VERSION ""

NS_ :

BS_:

BU_: LMFS RMFS TPMS TCU_ERAGLONASS E_APU PCCM NOX_2 NOX_1 ENGINE_CONTROL_MODULE TRANSMISSION INTARDER EBS TACHOGRAPH INSTRUMENT_CLUSTER CAMERA RADAR BCM

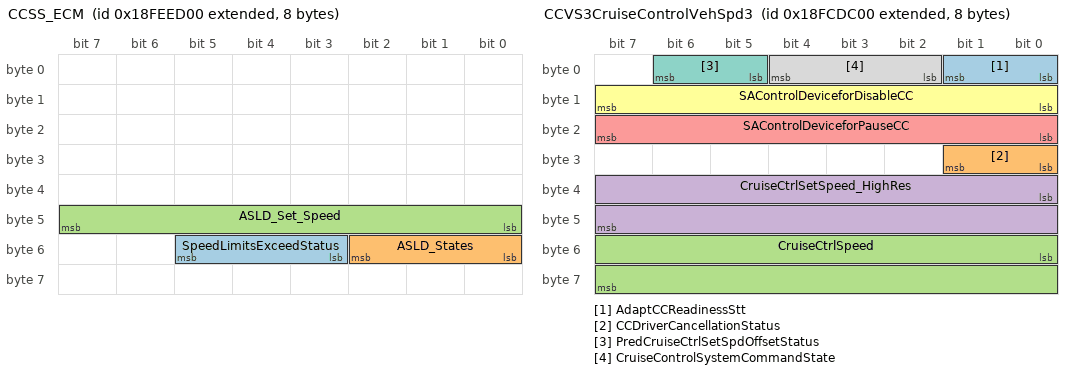
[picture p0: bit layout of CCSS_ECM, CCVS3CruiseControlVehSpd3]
BO_ 2566843648 CCSS_ECM: 8 ENGINE_CONTROL_MODULE
 SG_ SpeedLimitsExceedStatus : 51|3@1+ (1,0) [0|7] ""  PCCM,INSTRUMENT_CLUSTER
 SG_ ASLD_States : 48|3@1+ (1,0) [0|7] "SED"  PCCM,INSTRUMENT_CLUSTER
 SG_ ASLD_Set_Speed : 40|8@1+ (1,0) [0|250] "km/h"  PCCM,INSTRUMENT_CLUSTER

BO_ 2566708224 CCVS3CruiseControlVehSpd3: 8 ENGINE_CONTROL_MODULE
 SG_ AdaptCCReadinessStt : 0|2@1+ (1,0) [0|3] "SED" Vector__XXX
 SG_ CCDriverCancellationStatus : 24|2@1+ (1,0) [0|3] ""  PCCM
 SG_ CruiseCtrlSpeed : 48|16@1+ (0.00390625,0) [0|250.99609375] "km/h"  PCCM
 SG_ CruiseCtrlSetSpeed_HighRes : 32|16@1+ (0.00390625,0) [0|250.99609375] "km/h"  PCCM
 SG_ SAControlDeviceforPauseCC : 16|8@1+ (1,0) [0|255] ""  PCCM
 SG_ SAControlDeviceforDisableCC : 8|8@1+ (1,0) [0|255] ""  PCCM
 SG_ PredCruiseCtrlSetSpdOffsetStatus : 5|2@1+ (1,0) [0|3] ""  PCCM
 SG_ CruiseControlSystemCommandState : 2|3@1+ (1,0) [0|7] ""  PCCM

BO_ 2365512010 EmgcyCallMute: 8 TCU_ERAGLONASS
 SG_ Audio_Mute : 0|2@1+ (1,0) [0|3] ""  BCM

BO_ 2565475095 RQST_IC_EBS: 3 INSTRUMENT_CLUSTER
 SG_ ParameterGroupNumber : 0|24@1+ (1,0) [0|16777215] ""  PCCM,EBS

BO_ 2565472279 RQST_IC_ECM: 3 INSTRUMENT_CLUSTER
 SG_ ParameterGroupNumber : 0|24@1+ (1,0) [0|16777215] ""  ENGINE_CONTROL_MODULE

BO_ 2349465642 CCVS2: 8 RADAR
 SG_ CruiseControlPauseCommand : 4|2@1+ (1,0) [0|3] ""  PCCM
 SG_ CruiseControlDisableCommand : 0|2@1+ (1,0) [0|3] ""  PCCM

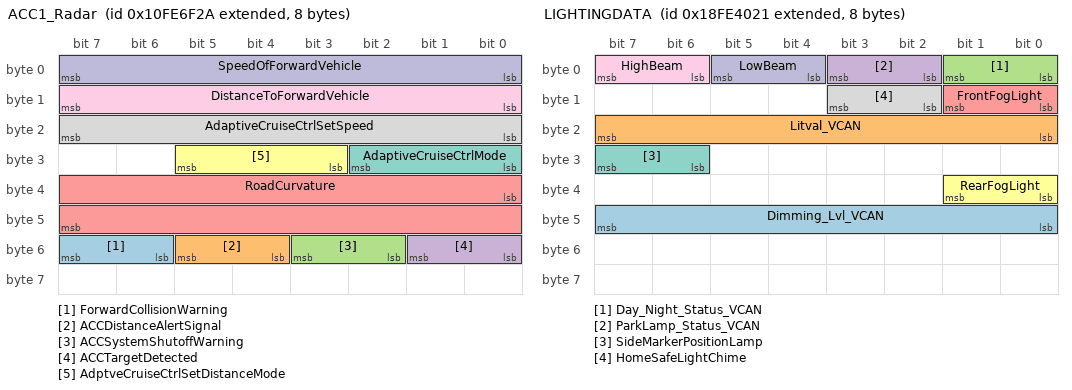
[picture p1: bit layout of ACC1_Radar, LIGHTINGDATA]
BO_ 2432593706 ACC1_Radar: 8 RADAR
 SG_ ForwardCollisionWarning : 54|2@1+ (1,0) [0|3] ""  PCCM,TRANSMISSION,INSTRUMENT_CLUSTER,BCM
 SG_ ACCDistanceAlertSignal : 52|2@1+ (1,0) [0|3] ""  PCCM,TRANSMISSION,INSTRUMENT_CLUSTER,BCM
 SG_ ACCSystemShutoffWarning : 50|2@1+ (1,0) [0|3] ""  PCCM,TRANSMISSION,INSTRUMENT_CLUSTER,BCM
 SG_ ACCTargetDetected : 48|2@1+ (1,0) [0|3] ""  PCCM,TRANSMISSION,INSTRUMENT_CLUSTER,BCM
 SG_ RoadCurvature : 32|16@1+ (0.0078125,-250) [-250|251.992] "1/km"  PCCM,TRANSMISSION,INSTRUMENT_CLUSTER,BCM
 SG_ AdptveCruiseCtrlSetDistanceMode : 27|3@1+ (1,0) [0|7] ""  PCCM,TRANSMISSION,INSTRUMENT_CLUSTER,BCM
 SG_ AdaptiveCruiseCtrlMode : 24|3@1+ (1,0) [0|7] ""  PCCM,TRANSMISSION,INSTRUMENT_CLUSTER,BCM
 SG_ AdaptiveCruiseCtrlSetSpeed : 16|8@1+ (1,0) [0|250] "km/h"  PCCM,TRANSMISSION,INSTRUMENT_CLUSTER,BCM
 SG_ DistanceToForwardVehicle : 8|8@1+ (1,0) [0|250] "m"  PCCM,TRANSMISSION,INSTRUMENT_CLUSTER,BCM
 SG_ SpeedOfForwardVehicle : 0|8@1+ (1,0) [0|250] "km/h"  PCCM,TRANSMISSION,INSTRUMENT_CLUSTER,BCM

BO_ 2566799393 LIGHTINGDATA: 8 BCM
 SG_ Dimming_Lvl_VCAN : 40|8@1+ (1,0) [0|255] ""  PCCM
 SG_ Litval_VCAN : 16|8@1+ (1,0) [0|255] "SED"  PCCM
 SG_ Day_Night_Status_VCAN : 0|2@1+ (1,0) [0|3] "SED"  PCCM
 SG_ ParkLamp_Status_VCAN : 2|2@1+ (1,0) [0|3] "SED"  PCCM
 SG_ FrontFogLight : 8|2@1+ (1,0) [0|3] ""  PCCM,INSTRUMENT_CLUSTER
 SG_ RearFogLight : 32|2@1+ (1,0) [0|3] ""  PCCM,INSTRUMENT_CLUSTER
 SG_ SideMarkerPositionLamp : 30|2@1+ (1,0) [0|3] ""  PCCM,INSTRUMENT_CLUSTER
 SG_ HomeSafeLightChime : 10|2@1+ (1,0) [0|3] ""  PCCM,INSTRUMENT_CLUSTER
 SG_ HighBeam : 6|2@1+ (1,0) [0|3] ""  PCCM,INSTRUMENT_CLUSTER
 SG_ LowBeam : 4|2@1+ (1,0) [0|3] ""  PCCM,INSTRUMENT_CLUSTER

BO_ 2566838561 AUXIO1: 8 BCM
 SG_ LaneDepartureWarningEnable : 30|2@1+ (1,0) [0|3] ""  PCCM,INSTRUMENT_CLUSTER
 SG_ DrvActDemandAdvEmergBrake : 28|2@1+ (1,0) [0|3] ""  PCCM,INSTRUMENT_CLUSTER
 SG_ Ignition_Status_VCAN : 24|4@1+ (1,0) [0|15] "SED"  PCCM,RMFS,RADAR
 SG_ AirDistributionMode : 18|4@1+ (1,0) [0|15] "SED"  PCCM,RMFS,RADAR
 SG_ CabInteriorTempCommand_BCM : 48|8@1+ (0.5,-40) [-40|87] "deg C"  PCCM,RMFS,RADAR
 SG_ TrailerABSEBSFault : 16|2@1+ (1,0) [0|3] "SED"  PCCM,RMFS,RADAR
 SG_ SteWhlSwtchMenu_B_Stat : 15|1@1+ (1,0) [0|1] "SED"  PCCM,RMFS,RADAR
 SG_ SteWhlSwtchBack_B_Stat : 34|1@1+ (1,0) [0|1] "SED"  PCCM,RMFS,RADAR
 SG_ SteWhlSwtchUp_B_Stat : 35|1@1+ (1,0) [0|1] "SED"  PCCM,RMFS,RADAR
 SG_ SteWhlSwtchOk_B_Stat : 36|1@1+ (1,0) [0|1] "SED"  PCCM,RMFS,RADAR
 SG_ SteWhlSwtchDown_B_Stat : 37|1@1+ (1,0) [0|1] "SED"  PCCM,RMFS,RADAR
 SG_ ManeuveringMode : 38|2@1+ (1,0) [0|3] "SED"  PCCM,RMFS,RADAR
 SG_ PowerMode_BCM : 40|2@1+ (1,0) [0|3] ""  PCCM,RMFS,RADAR
 SG_ OffRoadMode_BCM : 42|2@1+ (1,0) [0|3] ""  PCCM,RMFS,RADAR
 SG_ RockingMode_BCM : 44|2@1+ (1,0) [0|3] ""  PCCM,RMFS,RADAR
 SG_ RollingMode_BCM : 46|2@1+ (1,0) [0|3] ""  PCCM,RMFS,RADAR
 SG_ RqedACCDistanceMode : 12|3@1+ (1,0) [0|7] ""  PCCM,RMFS,RADAR
 SG_ AuxI_O08_GearboxNeutralPos_AUX1 : 4|2@1+ (1,0) [0|3] ""  PCCM,RMFS,RADAR
 SG_ AuxI_O07_TrailerABSFulOper_AUX1 : 6|2@1+ (1,0) [0|3] ""  PCCM,RMFS,RADAR
 SG_ AuxI_O06_TrailerABSDetected_AUX1 : 8|2@1+ (1,0) [0|3] ""  PCCM,RMFS,RADAR
 SG_ AuxI_O05_TrailerConnected_AUX1 : 10|2@1+ (1,0) [0|3] ""  PCCM,RMFS,RADAR
 SG_ PassengerDoorStatus : 0|2@1+ (1,0) [0|3] ""  PCCM,RMFS,RADAR,ENGINE_CONTROL_MODULE,INSTRUMENT_CLUSTER
 SG_ DriverDoorStatus : 2|2@1+ (1,0) [0|3] ""  PCCM,RMFS,RADAR,ENGINE_CONTROL_MODULE,INSTRUMENT_CLUSTER

BO_ 2564431089 TSTREQPCCM: 8 Vector__XXX
 SG_ TesterReqPCCM : 0|64@1- (1,0) [0|0] ""  PCCM

BO_ 2564429809 TSTREQCLUSTER: 8 PCCM
 SG_ TesterReqCluster : 0|64@1- (1,0) [0|0] "" Vector__XXX

BO_ 2564434673 TSTREQRADAR: 8 PCCM
 SG_ TesterReqRadar : 0|64@1- (1,0) [0|0] "" Vector__XXX

BO_ 2564428017 TSTREQINTARDER: 8 Vector__XXX

BO_ 2564436209 TSTREQEAPU: 8 Vector__XXX

BO_ 2564423921 TSTREQECM: 8 Vector__XXX

BO_ 2564483313 TSTREQCAMERA: 8 PCCM
 SG_ TesterReqCamera : 0|64@1- (1,0) [0|0] "" Vector__XXX

BO_ 2564432369 TSTREQBCM: 8 Vector__XXX
 SG_ TesterReqBCM : 0|64@1+ (1,0) [0|0] "" Vector__XXX

BO_ 2564426737 TSTREQEBS: 8 PCCM
 SG_ TesterReqEBS : 0|64@1- (1,0) [0|0] "" Vector__XXX

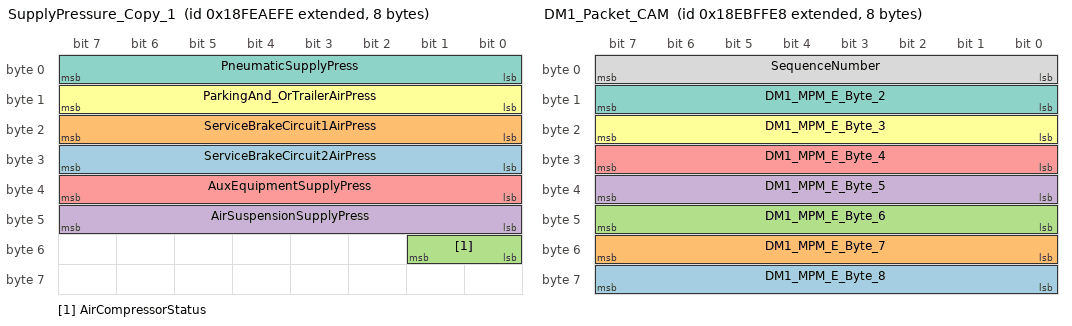
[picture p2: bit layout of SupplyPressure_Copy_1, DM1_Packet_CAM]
BO_ 2566827774 SupplyPressure_Copy_1: 8 Vector__XXX
 SG_ ServiceBrakeCircuit2AirPress : 24|8@1+ (8,0) [0|2000] "kPa" Vector__XXX
 SG_ ServiceBrakeCircuit1AirPress : 16|8@1+ (8,0) [0|2000] "kPa" Vector__XXX
 SG_ AirCompressorStatus : 48|2@1+ (1,0) [0|3] "" Vector__XXX
 SG_ AirSuspensionSupplyPress : 40|8@1+ (8,0) [0|2000] "kPa" Vector__XXX
 SG_ AuxEquipmentSupplyPress : 32|8@1+ (8,0) [0|2000] "kPa" Vector__XXX
 SG_ ParkingAnd_OrTrailerAirPress : 8|8@1+ (8,0) [0|2000] "kPa" Vector__XXX
 SG_ PneumaticSupplyPress : 0|8@1+ (8,0) [0|2000] "kPa" Vector__XXX

BO_ 2565603114 DM1_Packet_Radar: 8 Vector__XXX
 SG_ SequenceNumber : 0|8@1+ (1,0) [0|255] "" Vector__XXX

BO_ 2565668394 DM1_BAM_E_RADAR: 8 Vector__XXX
 SG_ TotalNumberOfPacketsEoMA m19 : 24|8@1+ (1,0) [0|255] "" Vector__XXX
 SG_ TotalMessageSizeEoMA m19 : 8|16@1+ (1,0) [0|64255] "counts" Vector__XXX
 SG_ TotalMessageSizeBAM m32 : 8|16@1+ (1,0) [0|64255] "counts" Vector__XXX
 SG_ TotalNumberOfPacketsBAM m32 : 24|8@1+ (1,0) [0|255] "" Vector__XXX
 SG_ ConnectionAbortReason m255 : 8|8@1+ (1,0) [0|255] "" Vector__XXX
 SG_ NextPacketNumberToBeSent m17 : 16|8@1+ (1,0) [0|255] "" Vector__XXX
 SG_ NumberOfPacketsThatCanBeSent m17 : 8|8@1+ (1,0) [0|255] "" Vector__XXX
 SG_ PGNumber : 40|24@1+ (1,0) [0|16777200] "" Vector__XXX
 SG_ MaximumNumberOfPackets m16 : 32|8@1+ (1,0) [0|255] "" Vector__XXX
 SG_ TotalNumberOfPackets m16 : 24|8@1+ (1,0) [0|255] "" Vector__XXX
 SG_ TotalMessageSize m16 : 8|16@1+ (1,0) [0|64255] "counts" Vector__XXX
 SG_ ControlByte M : 0|8@1+ (1,0) [0|255] "" Vector__XXX

BO_ 2565603304 DM1_Packet_CAM: 8 Vector__XXX
 SG_ DM1_MPM_E_Byte_8 : 56|8@1- (1,0) [0|255] "" Vector__XXX
 SG_ DM1_MPM_E_Byte_7 : 48|8@1- (1,0) [0|255] "" Vector__XXX
 SG_ DM1_MPM_E_Byte_6 : 40|8@1- (1,0) [0|255] "" Vector__XXX
 SG_ DM1_MPM_E_Byte_5 : 32|8@1- (1,0) [0|255] "" Vector__XXX
 SG_ DM1_MPM_E_Byte_4 : 24|8@1- (1,0) [0|255] "" Vector__XXX
 SG_ DM1_MPM_E_Byte_3 : 16|8@1- (1,0) [0|255] "" Vector__XXX
 SG_ DM1_MPM_E_Byte_2 : 8|8@1- (1,0) [0|255] "" Vector__XXX
 SG_ SequenceNumber : 0|8@1+ (1,0) [0|255] "" Vector__XXX

BO_ 2565668840 DM1_BAM_E_TPCM_CAM: 8 Vector__XXX
 SG_ TotalNumberOfPacketsEoMA m19 : 24|8@1+ (1,0) [0|255] "" Vector__XXX
 SG_ TotalMessageSizeEoMA m19 : 8|16@1+ (1,0) [0|64255] "counts" Vector__XXX
 SG_ TotalMessageSizeBAM m32 : 8|16@1+ (1,0) [0|64255] "counts" Vector__XXX
 SG_ TotalNumberOfPacketsBAM m32 : 24|8@1+ (1,0) [0|255] "" Vector__XXX
 SG_ ConnectionAbortReason m255 : 8|8@1+ (1,0) [0|255] "" Vector__XXX
 SG_ NextPacketNumberToBeSent m17 : 16|8@1+ (1,0) [0|255] "" Vector__XXX
 SG_ NumberOfPacketsThatCanBeSent m17 : 8|8@1+ (1,0) [0|255] "" Vector__XXX
 SG_ PGNumber : 40|24@1+ (1,0) [0|16777200] "" Vector__XXX
 SG_ MaximumNumberOfPackets m16 : 32|8@1+ (1,0) [0|255] "" Vector__XXX
 SG_ TotalNumberOfPackets m16 : 24|8@1+ (1,0) [0|255] "" Vector__XXX
 SG_ TotalMessageSize m16 : 8|16@1+ (1,0) [0|64255] "counts" Vector__XXX
 SG_ ControlByte M : 0|8@1+ (1,0) [0|255] "" Vector__XXX

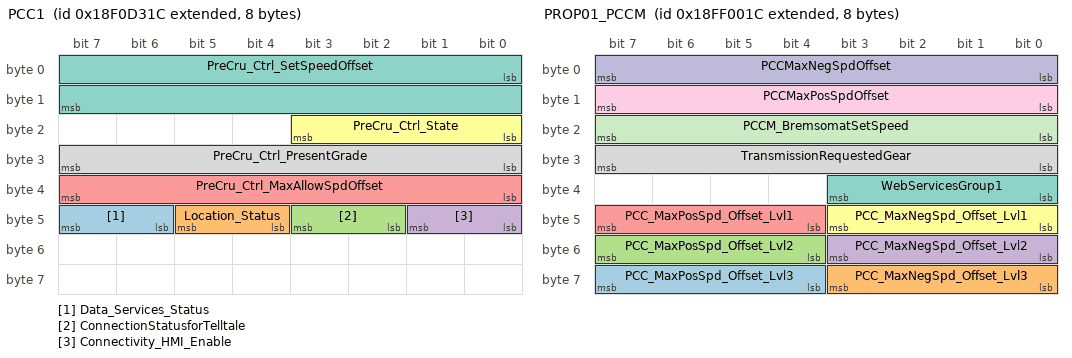
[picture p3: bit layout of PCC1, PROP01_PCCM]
BO_ 2565919516 PCC1: 8 PCCM
 SG_ Data_Services_Status : 46|2@1+ (1,0) [0|3] ""  INSTRUMENT_CLUSTER
 SG_ Location_Status : 44|2@1+ (1,0) [0|3] ""  INSTRUMENT_CLUSTER
 SG_ ConnectionStatusforTelltale : 42|2@1+ (1,0) [0|3] ""  INSTRUMENT_CLUSTER
 SG_ Connectivity_HMI_Enable : 40|2@1+ (1,0) [0|3] ""  INSTRUMENT_CLUSTER
 SG_ PreCru_Ctrl_MaxAllowSpdOffset : 32|8@1+ (0.125,0) [0|31.25] "kph"  ENGINE_CONTROL_MODULE
 SG_ PreCru_Ctrl_State : 16|4@1+ (1,0) [0|15] ""  INSTRUMENT_CLUSTER,ENGINE_CONTROL_MODULE,TRANSMISSION
 SG_ PreCru_Ctrl_SetSpeedOffset : 0|16@1+ (0.00390625,-125) [-125|125.996] "kph"  INSTRUMENT_CLUSTER,ENGINE_CONTROL_MODULE,TRANSMISSION
 SG_ PreCru_Ctrl_PresentGrade : 24|8@1+ (0.125,-16) [-16|15.25] "%"  INSTRUMENT_CLUSTER,ENGINE_CONTROL_MODULE,TRANSMISSION

BO_ 2566848540 PROP01_PCCM: 8 PCCM
 SG_ PCC_MaxPosSpd_Offset_Lvl3 : 60|4@1+ (1,0) [0|15] "kph"  INSTRUMENT_CLUSTER
 SG_ PCC_MaxNegSpd_Offset_Lvl3 : 56|4@1+ (1,-15) [-15|0] "kph"  INSTRUMENT_CLUSTER
 SG_ PCC_MaxPosSpd_Offset_Lvl2 : 52|4@1+ (1,0) [0|15] "kph"  INSTRUMENT_CLUSTER
 SG_ PCC_MaxNegSpd_Offset_Lvl2 : 48|4@1+ (1,-15) [-15|0] "kph"  INSTRUMENT_CLUSTER
 SG_ PCC_MaxPosSpd_Offset_Lvl1 : 44|4@1+ (1,0) [0|15] "kph"  INSTRUMENT_CLUSTER
 SG_ PCC_MaxNegSpd_Offset_Lvl1 : 40|4@1+ (1,-15) [-15|0] "kph"  INSTRUMENT_CLUSTER
 SG_ WebServicesGroup1 : 32|4@1+ (1,0) [0|15] ""  INSTRUMENT_CLUSTER,ENGINE_CONTROL_MODULE
 SG_ TransmissionRequestedGear : 24|8@1+ (1,-125) [-125|125] ""  INSTRUMENT_CLUSTER,ENGINE_CONTROL_MODULE
 SG_ PCCMaxPosSpdOffset : 8|8@1+ (0.125,0) [0|31.25] "kph"  INSTRUMENT_CLUSTER,ENGINE_CONTROL_MODULE,TRANSMISSION
 SG_ PCCMaxNegSpdOffset : 0|8@1+ (0.125,-31.25) [-31.25|0] "kph"  INSTRUMENT_CLUSTER,ENGINE_CONTROL_MODULE,TRANSMISSION
 SG_ PCCM_BremsomatSetSpeed : 16|8@1+ (0.5,0) [0|125] "kph"  INSTRUMENT_CLUSTER,ENGINE_CONTROL_MODULE

BO_ 2566832894 ERC2_PCCM: 8 Vector__XXX
 SG_ CruiseCtrlRetarderSpeedOffset : 8|16@1- (0.00390625,-125) [-125|125.996] "kph" Vector__XXX

BO_ 2558918398 CM2_PCCM: 8 Vector__XXX
 SG_ Pre_Crus_Cnrt_MaxNeg_Offset : 40|8@1- (0.125,-31.25) [-31.25|0] "kph" Vector__XXX
 SG_ Pre_Crus_Cnrt_MaxPoss_Offset : 32|8@1+ (0.125,0) [0|31.25] "kph" Vector__XXX

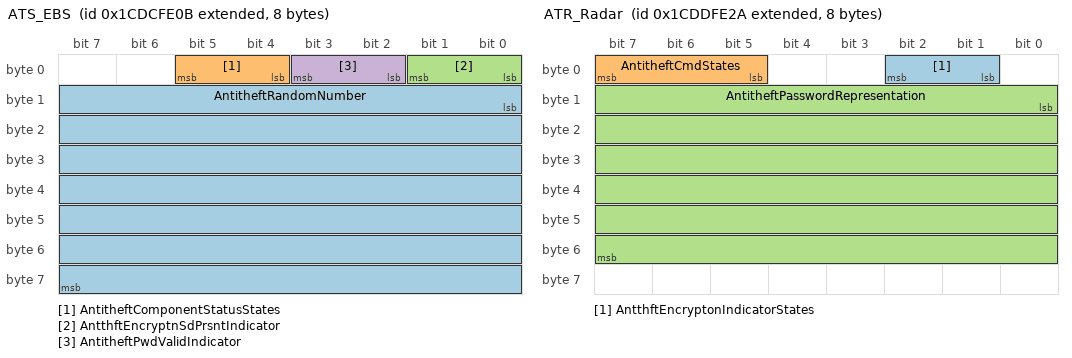
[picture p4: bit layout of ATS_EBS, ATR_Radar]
BO_ 2631728651 ATS_EBS: 8 EBS
 SG_ AntitheftRandomNumber : 8|56@1+ (1,0) [0|7.2057594038E+016] ""  RADAR
 SG_ AntitheftComponentStatusStates : 4|2@1+ (1,0) [0|3] ""  RADAR
 SG_ AntthftEncryptnSdPrsntIndicator : 0|2@1+ (1,0) [0|3] ""  RADAR
 SG_ AntitheftPwdValidIndicator : 2|2@1+ (1,0) [0|3] ""  RADAR

BO_ 2631794218 ATR_Radar: 8 RADAR
 SG_ AntthftEncryptonIndicatorStates : 1|2@1+ (1,0) [0|3] ""  EBS
 SG_ AntitheftCmdStates : 5|3@1+ (1,0) [0|7] ""  EBS
 SG_ AntitheftPasswordRepresentation : 8|48@1+ (1,0) [0|4] ""  EBS

BO_ 2566849534 MotorStatus: 8 Vector__XXX
 SG_ MeasuredPercentMotorSpeed : 48|16@1- (0.5,0) [0|0] "%" Vector__XXX
 SG_ MeasuredMotorPower : 40|8@1- (1,0) [0|0] "" Vector__XXX
 SG_ MeasuredMotorControllerTemp : 24|16@1- (0.03125,-273) [0|0] "" Vector__XXX
 SG_ MeasuredMotorSpeed : 8|16@1- (0.5,0) [0|0] "rpm" Vector__XXX

BO_ 2565865214 MotorCommand: 8 Vector__XXX
 SG_ MotorControllerPowerHoldCommand : 8|8@1- (1,0) [0|3] "" Vector__XXX
 SG_ MotorOnOffDirectionCommand : 0|8@1- (1,0) [0|3] "" Vector__XXX

BO_ 2566775040 CACI_ECM: 8 ENGINE_CONTROL_MODULE
 SG_ CbA_CRfrgrntCmprssorOutletPress : 0|8@1+ (16,0) [0|4000] "kPa"  PCCM,BCM

BO_ 2349202960 ABCD_0000: 8 Vector__XXX

BO_ 2349203198 ABCD: 8 Vector__XXX

BO_ 2566811651 TCU1: 8 TRANSMISSION
 SG_ PitchAngle : 8|8@1+ (0.25,-31) [-31|32.75] "%"  PCCM
 SG_ GrossCombinationWeight : 16|16@1+ (10,0) [0|642.55] "kg"  PCCM
 SG_ DirectorIndicator : 32|2@1+ (1,0) [0|3] ""  PCCM

BO_ 2565668619 TPCM_EBS: 8 EBS
 SG_ TotalNumberOfPacketsEoMA m19 : 24|8@1+ (1,0) [0|255] "" Vector__XXX
 SG_ TotalMessageSizeEoMA m19 : 8|16@1+ (1,0) [0|64255] "counts" Vector__XXX
 SG_ TotalMessageSizeBAM m32 : 8|16@1+ (1,0) [0|64255] "counts" Vector__XXX
 SG_ TotalNumberOfPacketsBAM m32 : 24|8@1+ (1,0) [0|255] "" Vector__XXX
 SG_ ConnectionAbortReason m255 : 8|8@1+ (1,0) [0|255] "" Vector__XXX
 SG_ NextPacketNumberToBeSent m17 : 16|8@1+ (1,0) [0|255] "" Vector__XXX
 SG_ NumberOfPacketsThatCanBeSent m17 : 8|8@1+ (1,0) [0|255] "" Vector__XXX
 SG_ PGNumber : 40|24@1+ (1,0) [0|16777200] "" Vector__XXX
 SG_ MaximumNumberOfPackets m16 : 32|8@1+ (1,0) [0|255] "" Vector__XXX
 SG_ TotalNumberOfPackets m16 : 24|8@1+ (1,0) [0|255] "" Vector__XXX
 SG_ TotalMessageSize m16 : 8|16@1+ (1,0) [0|64255] "counts" Vector__XXX
 SG_ ControlByte M : 0|8@1+ (1,0) [0|255] "" Vector__XXX

BO_ 2565603083 TPDT_EBS: 8 EBS
 SG_ SequenceNumber : 0|8@1+ (1,0) [0|255] "" Vector__XXX

BO_ 2566870526 PROP_IT3_BCM: 8 Vector__XXX
 SG_ Hand_Lever_Signals_PROP_IT3_BCM : 16|8@1+ (1,0) [0|31] "" Vector__XXX

BO_ 2563829271 OPT: 8 BCM
 SG_ TachoDimming : 0|8@1+ (0.4,0) [0|100] "%"  PCCM,TACHOGRAPH

BO_ 2566834920 DM1_Camera: 64 CAMERA
 SG_ OccurenceCount_Camera : 40|7@1+ (1,0) [0|127] ""  PCCM,INSTRUMENT_CLUSTER
 SG_ FailureModeIdentifier1_Camera : 32|5@1+ (1,0) [0|31] ""  PCCM,INSTRUMENT_CLUSTER
 SG_ AmberWarningLampStatus_Camera : 2|2@1+ (1,0) [0|3] ""  PCCM,INSTRUMENT_CLUSTER
 SG_ SPN4_Camera : 47|1@1+ (1,0) [0|1] ""  PCCM,INSTRUMENT_CLUSTER
 SG_ SPN3_Camera : 37|3@1+ (1,0) [0|7] ""  PCCM,INSTRUMENT_CLUSTER
 SG_ SPN2_Camera : 24|8@1+ (1,0) [0|255] ""  PCCM,INSTRUMENT_CLUSTER
 SG_ SPN1_Camera : 16|8@1+ (1,0) [0|255] ""  PCCM,INSTRUMENT_CLUSTER

BO_ 2566834730 DM1_Radar: 64 RADAR
 SG_ SPN4_Radar : 47|1@1+ (1,0) [0|1] ""  PCCM,INSTRUMENT_CLUSTER
 SG_ SPN3_Radar : 37|3@1+ (1,0) [0|7] ""  PCCM,INSTRUMENT_CLUSTER
 SG_ SPN2_Radar : 24|8@1+ (1,0) [0|255] ""  PCCM,INSTRUMENT_CLUSTER
 SG_ SPN1_Radar : 16|8@1+ (1,0) [0|255] ""  PCCM,INSTRUMENT_CLUSTER
 SG_ OccurenceCount_Radar : 40|7@1+ (1,0) [0|127] ""  PCCM,INSTRUMENT_CLUSTER
 SG_ FailureModeIdentifier1_Radar : 32|5@1+ (1,0) [0|31] ""  PCCM,INSTRUMENT_CLUSTER
 SG_ AmberWarningLampStatus_Radar : 2|2@1+ (1,0) [0|3] ""  PCCM,INSTRUMENT_CLUSTER

BO_ 2566759427 PTODE_TRANS: 8 TRANSMISSION
 SG_ PTO1EngagementStatus : 22|2@1+ (1,0) [0|3] ""  PCCM,BCM

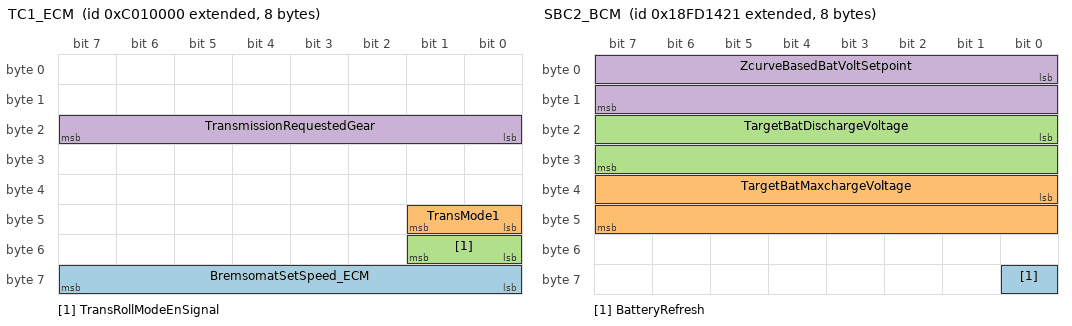
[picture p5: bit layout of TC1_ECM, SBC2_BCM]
BO_ 2348875776 TC1_ECM: 8 ENGINE_CONTROL_MODULE
 SG_ BremsomatSetSpeed_ECM : 56|8@1+ (0.5,0) [0|125] "km/h"  PCCM,RMFS
 SG_ TransMode1 : 40|2@1+ (1,0) [0|3] ""  PCCM
 SG_ TransRollModeEnSignal : 48|2@1+ (1,0) [0|3] "SED"  PCCM,RMFS
 SG_ TransmissionRequestedGear : 16|8@1+ (1,0) [0|255] ""  PCCM

BO_ 2566722593 SBC2_BCM: 8 BCM
 SG_ BatteryRefresh : 56|1@1+ (1,0) [0|1] ""  PCCM,ENGINE_CONTROL_MODULE
 SG_ TargetBatMaxchargeVoltage : 32|16@1+ (0.557,-15000) [-15000|35000] "mV"  PCCM,ENGINE_CONTROL_MODULE
 SG_ TargetBatDischargeVoltage : 16|16@1+ (0.557,-1500) [-1500|35000] "mV"  PCCM,ENGINE_CONTROL_MODULE
 SG_ ZcurveBasedBatVoltSetpoint : 0|16@1+ (0.557,-1500) [-1500|35002.995] "mV"  PCCM,ENGINE_CONTROL_MODULE

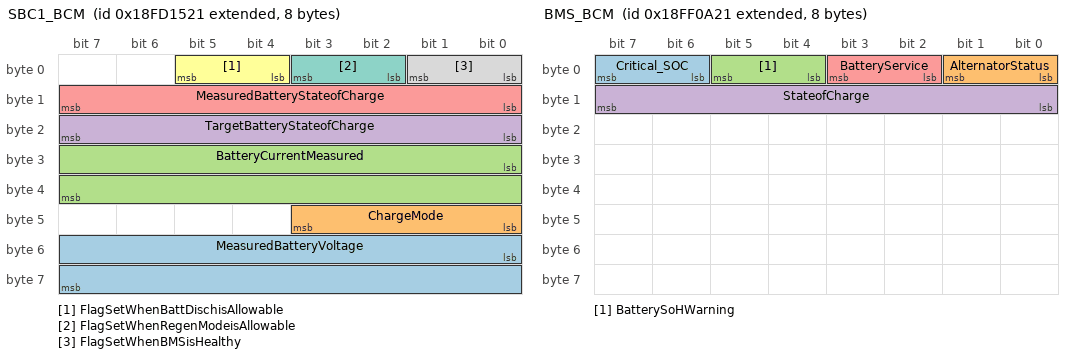
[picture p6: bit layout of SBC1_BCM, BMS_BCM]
BO_ 2566722849 SBC1_BCM: 8 BCM
 SG_ MeasuredBatteryVoltage : 48|16@1+ (0.557,-1500) [-1500|35000] "mV"  PCCM,ENGINE_CONTROL_MODULE
 SG_ ChargeMode : 40|4@1+ (1,0) [0|15] ""  PCCM,ENGINE_CONTROL_MODULE
 SG_ BatteryCurrentMeasured : 24|16@1+ (0.0305,-1600) [-1600|400] "A"  PCCM,ENGINE_CONTROL_MODULE
 SG_ TargetBatteryStateofCharge : 16|8@1+ (0.5,-10) [-10|117.5] "%"  PCCM,ENGINE_CONTROL_MODULE
 SG_ MeasuredBatteryStateofCharge : 8|8@1+ (0.5,-10) [-10|117.5] "%"  PCCM,ENGINE_CONTROL_MODULE
 SG_ FlagSetWhenBattDischisAllowable : 4|2@1+ (1,0) [0|3] ""  PCCM,ENGINE_CONTROL_MODULE
 SG_ FlagSetWhenRegenModeisAllowable : 2|2@1+ (1,0) [0|3] ""  PCCM,ENGINE_CONTROL_MODULE
 SG_ FlagSetWhenBMSisHealthy : 0|2@1+ (1,0) [0|3] ""  PCCM,ENGINE_CONTROL_MODULE

BO_ 2566879486 AUTODROP_BCM: 4 Vector__XXX
 SG_ AxleState : 24|8@1+ (1,0) [0|4] "" Vector__XXX
 SG_ AxleLoweringRemainingTime : 16|8@1+ (1,0) [0|255] "" Vector__XXX
 SG_ Warning : 8|8@1+ (1,0) [0|255] "" Vector__XXX
 SG_ Action : 0|8@1+ (1,0) [0|255] "" Vector__XXX

BO_ 2564487475 UDSClientTPMS_resp: 8 TPMS
 SG_ SignalFiller1 : 32|32@1- (1,0) [0|0] ""  PCCM
 SG_ SignalFiller0 : 0|32@1- (1,0) [0|0] ""  PCCM

BO_ 2566851105 BMS_BCM: 8 BCM
 SG_ Critical_SOC : 6|2@1+ (1,0) [0|3] "SED"  PCCM
 SG_ AlternatorStatus : 0|2@1+ (1,0) [0|3] ""  PCCM,INSTRUMENT_CLUSTER
 SG_ BatterySoHWarning : 4|2@1+ (1,0) [0|3] ""  PCCM,INSTRUMENT_CLUSTER
 SG_ StateofCharge : 8|8@1+ (1,0) [0|250] ""  PCCM,INSTRUMENT_CLUSTER
 SG_ BatteryService : 2|2@1+ (1,0) [0|3] ""  PCCM,INSTRUMENT_CLUSTER

BO_ 2566843134 VW_BCM_0000: 8 Vector__XXX
 SG_ AxleLocation M : 0|8@1+ (1,0) [0|255] "" Vector__XXX
 SG_ CargoWeight_30 m48 : 40|16@1+ (2,0) [0|128510] "kg" Vector__XXX
 SG_ CargoWeight_20 m32 : 40|16@1+ (2,0) [0|128510] "kg" Vector__XXX
 SG_ CargoWeight_10 m16 : 40|16@1+ (2,0) [0|128510] "kg" Vector__XXX
 SG_ CargoWeight_00 m0 : 40|16@1+ (2,0) [0|128510] "kg" Vector__XXX
 SG_ TrailerWeight_30 m48 : 24|16@1+ (2,0) [0|128510] "kg" Vector__XXX
 SG_ TrailerWeight_20 m32 : 24|16@1+ (2,0) [0|128510] "kg" Vector__XXX
 SG_ TrailerWeight_10 m16 : 24|16@1+ (2,0) [0|128510] "kg" Vector__XXX
 SG_ TrailerWeight_00 m0 : 24|16@1+ (2,0) [0|128510] "kg" Vector__XXX
 SG_ AxleWeight_30 m48 : 8|16@1+ (0.5,0) [0|32127.5] "kg" Vector__XXX
 SG_ AxleWeight_20 m32 : 8|16@1+ (0.5,0) [0|32127.5] "kg" Vector__XXX
 SG_ AxleWeight_10 m16 : 8|16@1+ (0.5,0) [0|32127.5] "kg" Vector__XXX
 SG_ AxleWeight_00 m0 : 8|16@1+ (0.5,0) [0|32127.5] "kg" Vector__XXX

BO_ 2365479678 ASC1_BCM_ECAS: 8 Vector__XXX
 SG_ SpeedDependantLevelCtrlStatus : 54|2@1+ (1,0) [0|3] "" Vector__XXX
 SG_ MemoryLevel : 60|4@1+ (1,0) [0|15] "" Vector__XXX
 SG_ AllwLvelCtrlDuringBrakingStatus : 52|2@1+ (1,0) [0|3] "" Vector__XXX
 SG_ SspensionCtrlRefusalInformation : 56|4@1+ (1,0) [0|15] "" Vector__XXX
 SG_ SuspensionRemoteCtrl2 : 50|2@1+ (1,0) [0|3] "" Vector__XXX
 SG_ SuspensionRemoteCtrl1 : 48|2@1+ (1,0) [0|3] "" Vector__XXX
 SG_ RearAxleInBumperRange : 42|2@1+ (1,0) [0|3] "" Vector__XXX
 SG_ FrontAxleInBumperRange : 40|2@1+ (1,0) [0|3] "" Vector__XXX
 SG_ DoorRelease : 36|2@1+ (1,0) [0|3] "" Vector__XXX
 SG_ VehicleMotionInhibit : 34|2@1+ (1,0) [0|3] "" Vector__XXX
 SG_ SecurityDevice : 32|2@1+ (1,0) [0|3] "" Vector__XXX
 SG_ LevelCtrlMode : 28|4@1+ (1,0) [0|15] "" Vector__XXX
 SG_ KneelingInformation : 24|4@1+ (1,0) [0|15] "" Vector__XXX
 SG_ LiftingCtrlModeRearAxle : 22|2@1+ (1,0) [0|3] "" Vector__XXX
 SG_ LiftingCtrlModeFrontAxle : 20|2@1+ (1,0) [0|3] "" Vector__XXX
 SG_ LoweringCtrlModeRearAxle : 18|2@1+ (1,0) [0|3] "" Vector__XXX
 SG_ LoweringCtrlModeFrontAxle : 16|2@1+ (1,0) [0|3] "" Vector__XXX
 SG_ AboveNominalLevelRearAxle : 14|2@1+ (1,0) [0|3] "" Vector__XXX
 SG_ AboveNominalLevelFrontAxle : 12|2@1+ (1,0) [0|3] "" Vector__XXX
 SG_ BelowNominalLevelRearAxle : 10|2@1+ (1,0) [0|3] "" Vector__XXX
 SG_ BelowNominalLevelFrontAxle : 8|2@1+ (1,0) [0|3] "" Vector__XXX
 SG_ NominalLevelRearAxle : 4|4@1+ (1,0) [0|15] "" Vector__XXX
 SG_ NominalLevelFrontAxle : 0|4@1+ (1,0) [0|15] "" Vector__XXX
 SG_ LiftAxle2Pos : 46|2@1+ (1,0) [0|3] "" Vector__XXX
 SG_ LiftAxle1Pos : 38|2@1+ (1,0) [0|3] "" Vector__XXX

BO_ 2566759457 PTDOE_BCM: 8 BCM
 SG_ PTOEngagementStatus : 38|2@1+ (1,0) [0|3] ""  PCCM,TRANSMISSION
 SG_ EnableSwitchStatus : 6|2@1+ (1,0) [0|3] ""  PCCM,TRANSMISSION

BO_ 2566756875 EBS24: 8 EBS
 SG_ GeoDataIndex : 0|8@1+ (1,0) [0|29] ""  PCCM

BO_ 2566910718 SRA12EDC: 1 Vector__XXX
 SG_ MultiplexValue : 0|8@1+ (1,0) [0|12] "" Vector__XXX

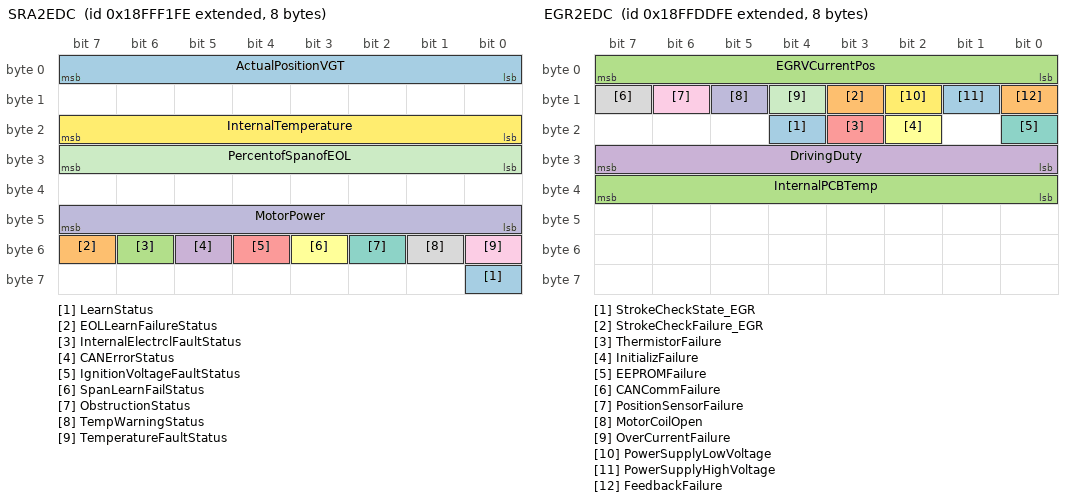
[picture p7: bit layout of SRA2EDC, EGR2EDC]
BO_ 2566910462 SRA2EDC: 8 Vector__XXX
 SG_ LearnStatus : 56|1@1+ (1,0) [0|0] "" Vector__XXX
 SG_ EOLLearnFailureStatus : 55|1@1+ (1,0) [0|1] "" Vector__XXX
 SG_ InternalElectrclFaultStatus : 54|1@1+ (1,0) [0|1] "" Vector__XXX
 SG_ CANErrorStatus : 53|1@1+ (1,0) [0|1] "" Vector__XXX
 SG_ IgnitionVoltageFaultStatus : 52|1@1+ (1,0) [0|1] "" Vector__XXX
 SG_ SpanLearnFailStatus : 51|1@1+ (1,0) [0|1] "" Vector__XXX
 SG_ ObstructionStatus : 50|1@1+ (1,0) [0|1] "" Vector__XXX
 SG_ TempWarningStatus : 49|1@1+ (1,0) [0|1] "" Vector__XXX
 SG_ TemperatureFaultStatus : 48|1@1+ (1,0) [0|1] "" Vector__XXX
 SG_ MotorPower : 40|8@1+ (1,0) [0|50] "W" Vector__XXX
 SG_ PercentofSpanofEOL : 24|8@1+ (1,0) [0|150] "%" Vector__XXX
 SG_ InternalTemperature : 16|8@1+ (1,0) [0|214] "deg C" Vector__XXX
 SG_ ActualPositionVGT : 0|8@1+ (1,0) [0|100] "%" Vector__XXX

BO_ 2566905342 EGR2EDC: 8 Vector__XXX
 SG_ StrokeCheckState_EGR : 20|1@1+ (1,0) [0|1] "" Vector__XXX
 SG_ StrokeCheckFailure_EGR : 11|1@1+ (1,0) [0|1] "" Vector__XXX
 SG_ InternalPCBTemp : 32|8@1+ (1,0) [0|150] "C deg" Vector__XXX
 SG_ DrivingDuty : 24|8@1- (1,0) [0|100] "%" Vector__XXX
 SG_ ThermistorFailure : 19|1@1- (1,0) [0|1] "" Vector__XXX
 SG_ InitializFailure : 18|1@1- (1,0) [0|1] "" Vector__XXX
 SG_ EEPROMFailure : 16|1@1+ (1,0) [0|1] "" Vector__XXX
 SG_ CANCommFailure : 15|1@1+ (1,0) [0|1] "" Vector__XXX
 SG_ PositionSensorFailure : 14|1@1+ (1,0) [0|1] "" Vector__XXX
 SG_ MotorCoilOpen : 13|1@1+ (1,0) [0|1] "" Vector__XXX
 SG_ OverCurrentFailure : 12|1@1+ (1,0) [0|1] "" Vector__XXX
 SG_ PowerSupplyLowVoltage : 10|1@1+ (1,0) [0|1] "" Vector__XXX
 SG_ PowerSupplyHighVoltage : 9|1@1+ (1,0) [0|1] "" Vector__XXX
 SG_ FeedbackFailure : 8|1@1+ (1,0) [0|1] "" Vector__XXX
 SG_ EGRVCurrentPos : 0|8@1+ (1,0) [0|80] "deg" Vector__XXX

BO_ 2566905086 EDC2EGR: 8 Vector__XXX
 SG_ StrokeCheckRequest_EGR : 47|1@1+ (1,0) [0|1] "" Vector__XXX
 SG_ CrankingSignal : 45|1@1+ (1,0) [0|1] "" Vector__XXX
 SG_ DesiredEGRValvePos : 0|8@1+ (1,0) [0|80] "deg" Vector__XXX

BO_ 2566910206 EDC2SRA: 3 Vector__XXX
 SG_ LearnedCommandPermission : 17|1@1+ (1,0) [0|1] "" Vector__XXX
 SG_ MotorOnOffStatus : 16|1@1+ (1,0) [0|1] "" Vector__XXX
 SG_ DesiredPosition : 0|8@1+ (0.1,0) [0|100] "%" Vector__XXX

BO_ 2566841344 SHUTDN_ECM: 8 ENGINE_CONTROL_MODULE
 SG_ EngineOperationMode : 26|4@1+ (1,0) [0|15] ""  INSTRUMENT_CLUSTER,PCCM
 SG_ EngOverspeedTest : 54|2@1+ (1,0) [0|3] ""  INSTRUMENT_CLUSTER,PCCM
 SG_ EngAirShutoffCmdStatus : 52|2@1+ (1,0) [0|3] ""  INSTRUMENT_CLUSTER,PCCM
 SG_ EngAlarmOutputCmdStatus : 50|2@1+ (1,0) [0|3] ""  INSTRUMENT_CLUSTER,PCCM
 SG_ EngAlarmAcknowledge : 48|2@1+ (1,0) [0|3] ""  INSTRUMENT_CLUSTER,PCCM
 SG_ EngProtectionSystemConfig : 46|2@1+ (1,0) [0|3] ""  INSTRUMENT_CLUSTER,PCCM
 SG_ EngProtectionSystemTimerState : 38|2@1+ (1,0) [0|3] ""  INSTRUMENT_CLUSTER,PCCM
 SG_ EngPrtectionSystemTimerOverride : 36|2@1+ (1,0) [0|3] ""  INSTRUMENT_CLUSTER,PCCM
 SG_ EngPrtctnSystmApprchingShutdown : 34|2@1+ (1,0) [0|3] ""  INSTRUMENT_CLUSTER,PCCM
 SG_ EngWaitToStartLamp : 24|2@1+ (1,0) [0|3] ""  INSTRUMENT_CLUSTER,PCCM
 SG_ RefrigerantHighPressSwitch : 20|2@1+ (1,0) [0|3] ""  INSTRUMENT_CLUSTER,PCCM
 SG_ RefrigerantLowPressSwitch : 18|2@1+ (1,0) [0|3] ""  INSTRUMENT_CLUSTER,PCCM
 SG_ A_CHighPressFanSwitch : 16|2@1+ (1,0) [0|3] ""  INSTRUMENT_CLUSTER,PCCM
 SG_ EngIdleShutdownTimerFunction : 14|2@1+ (1,0) [0|3] ""  INSTRUMENT_CLUSTER,PCCM
 SG_ EngIdleShutdownTimerState : 6|2@1+ (1,0) [0|3] ""  INSTRUMENT_CLUSTER,PCCM
 SG_ EngIdleShutdownTimerOverride : 4|2@1+ (1,0) [0|3] ""  INSTRUMENT_CLUSTER,PCCM
 SG_ EngIdleShutdownDriverAlertMode : 2|2@1+ (1,0) [0|3] ""  INSTRUMENT_CLUSTER,PCCM
 SG_ PTOShutdownHasShutdownEng : 58|2@1+ (1,0) [0|3] ""  INSTRUMENT_CLUSTER,PCCM
 SG_ EngPrtctnSystmHasShutdownEngine : 32|2@1+ (1,0) [0|3] ""  INSTRUMENT_CLUSTER,PCCM
 SG_ EngIdlShutdownHasShutdownEngine : 0|2@1+ (1,0) [0|3] ""  INSTRUMENT_CLUSTER,PCCM
 SG_ EngAirShutoffStatus : 56|2@1+ (1,0) [0|3] ""  INSTRUMENT_CLUSTER,PCCM

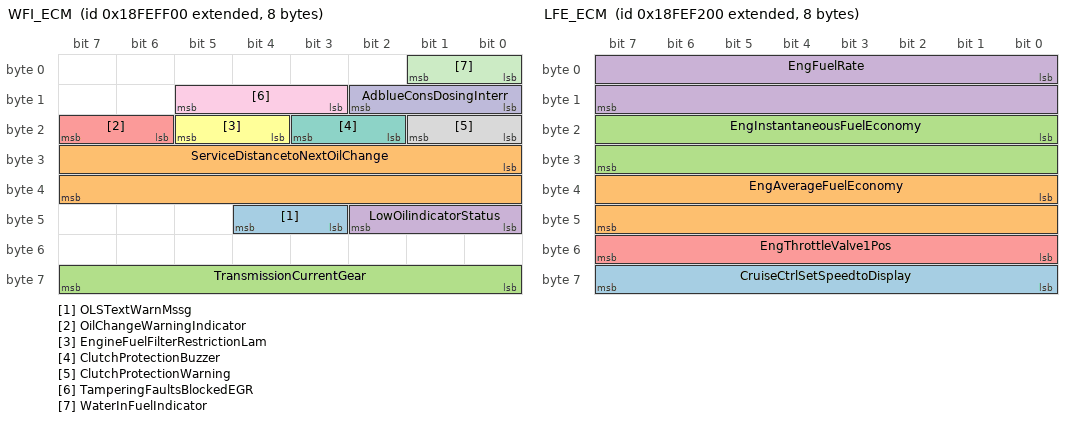
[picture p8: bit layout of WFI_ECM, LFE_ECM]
BO_ 2566848256 WFI_ECM: 8 ENGINE_CONTROL_MODULE
 SG_ OLSTextWarnMssg : 43|2@1+ (1,0) [0|3] "SED"  PCCM,INSTRUMENT_CLUSTER,BCM
 SG_ ServiceDistancetoNextOilChange : 24|16@1+ (5,-160635) [-160635|160640] ""  PCCM,INSTRUMENT_CLUSTER,BCM
 SG_ TransmissionCurrentGear : 56|8@1+ (1,-125) [-125|125] ""  PCCM,INSTRUMENT_CLUSTER,BCM
 SG_ LowOilindicatorStatus : 40|3@1+ (1,0) [0|7] ""  PCCM,INSTRUMENT_CLUSTER,BCM
 SG_ OilChangeWarningIndicator : 22|2@1+ (1,0) [0|3] ""  PCCM,INSTRUMENT_CLUSTER,BCM
 SG_ EngineFuelFilterRestrictionLam : 20|2@1+ (1,0) [0|3] ""  PCCM,INSTRUMENT_CLUSTER,BCM
 SG_ ClutchProtectionBuzzer : 18|2@1+ (1,0) [0|3] ""  PCCM,INSTRUMENT_CLUSTER,BCM
 SG_ ClutchProtectionWarning : 16|2@1+ (1,0) [0|3] ""  PCCM,INSTRUMENT_CLUSTER,BCM
 SG_ TamperingFaultsBlockedEGR : 11|3@1+ (1,0) [0|7] ""  PCCM,INSTRUMENT_CLUSTER,BCM
 SG_ AdblueConsDosingInterr : 8|3@1+ (1,0) [0|7] ""  PCCM,INSTRUMENT_CLUSTER,BCM
 SG_ WaterInFuelIndicator : 0|2@1+ (1,0) [0|3] ""  PCCM,INSTRUMENT_CLUSTER,BCM

BO_ 2566719744 HRLFC_ECM: 8 Vector__XXX
 SG_ HighResolutionEngTotalFuelUsed : 32|32@1+ (0.001,0) [0|4211081.215] "L" Vector__XXX
 SG_ HighResolutionEngTripFuel : 0|32@1+ (0.001,0) [0|4211081.215] "L" Vector__XXX

BO_ 2566844928 LFE_ECM: 8 ENGINE_CONTROL_MODULE
 SG_ CruiseCtrlSetSpeedtoDisplay : 56|8@1+ (1,0) [0|255] "km/h"  PCCM,INSTRUMENT_CLUSTER,BCM
 SG_ EngAverageFuelEconomy : 32|16@1+ (0.001953125,0) [0|125.5] "km/L"  PCCM,INSTRUMENT_CLUSTER,BCM
 SG_ EngInstantaneousFuelEconomy : 16|16@1+ (0.001953125,0) [0|125.5] "km/L"  PCCM,INSTRUMENT_CLUSTER,BCM
 SG_ EngFuelRate : 0|16@1+ (0.05,0) [0|3212.75] "L/h"  PCCM,INSTRUMENT_CLUSTER,BCM
 SG_ EngThrottleValve1Pos : 48|8@1+ (0.4,0) [0|100] "%"  PCCM,INSTRUMENT_CLUSTER,BCM

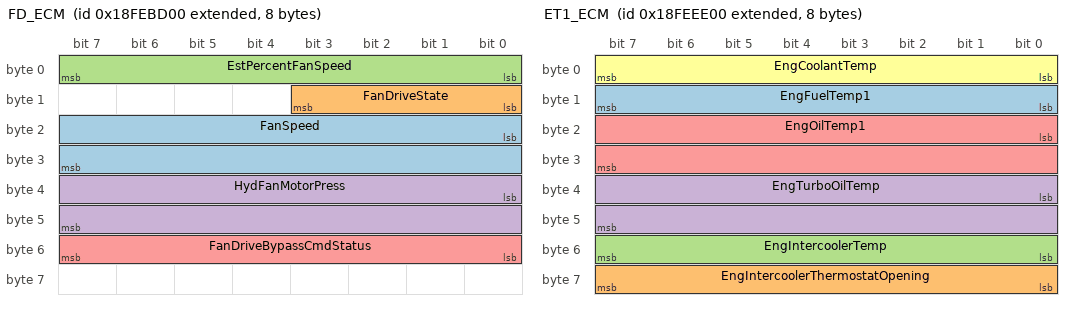
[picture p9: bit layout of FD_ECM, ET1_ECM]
BO_ 2566831360 FD_ECM: 8 ENGINE_CONTROL_MODULE
 SG_ FanSpeed : 16|16@1+ (0.125,0) [0|8031.875] "rpm"  PCCM,BCM
 SG_ FanDriveState : 8|4@1+ (1,0) [0|15] ""  PCCM,BCM
 SG_ EstPercentFanSpeed : 0|8@1+ (0.4,0) [0|100] "%"  PCCM,BCM
 SG_ HydFanMotorPress : 32|16@1+ (0.5,0) [0|32127.5] "kPa"  PCCM,BCM
 SG_ FanDriveBypassCmdStatus : 48|8@1+ (0.4,0) [0|100] "%"  PCCM,BCM

BO_ 2566843904 ET1_ECM: 8 ENGINE_CONTROL_MODULE
 SG_ EngFuelTemp1 : 8|8@1+ (1,-40) [-40|210] "deg C"  PCCM,TRANSMISSION,INSTRUMENT_CLUSTER,BCM
 SG_ EngIntercoolerThermostatOpening : 56|8@1+ (0.4,0) [0|100] "%"  PCCM,TRANSMISSION,INSTRUMENT_CLUSTER,BCM
 SG_ EngIntercoolerTemp : 48|8@1+ (1,-40) [-40|210] "deg C"  PCCM,TRANSMISSION,INSTRUMENT_CLUSTER,BCM
 SG_ EngTurboOilTemp : 32|16@1+ (0.03125,-273) [-273|1735] "deg C"  PCCM,TRANSMISSION,INSTRUMENT_CLUSTER,BCM
 SG_ EngOilTemp1 : 16|16@1+ (0.03125,-273) [-273|1735] "deg C"  PCCM,TRANSMISSION,INSTRUMENT_CLUSTER,BCM
 SG_ EngCoolantTemp : 0|8@1+ (1,-40) [-40|210] "deg C"  PCCM,TRANSMISSION,INSTRUMENT_CLUSTER,BCM

BO_ 2566841088 EC1_ECM: 39 ENGINE_CONTROL_MODULE
 SG_ SupportTSC1CtrlPurposeGroup4 : 304|8@1+ (1,0) [0|255] ""  PCCM,TRANSMISSION,EBS
 SG_ SupportTSC1CtrlPurposeGroup3 : 296|8@1+ (1,0) [0|255] ""  PCCM,TRANSMISSION,EBS
 SG_ SupportTSC1CtrlPurposeGroup2 : 288|8@1+ (1,0) [0|255] ""  PCCM,TRANSMISSION,EBS
 SG_ SupportTSC1CtrlPurposeGroup1 : 280|8@1+ (1,0) [0|255] ""  PCCM,TRANSMISSION,EBS
 SG_ SupportVariableRateTSC1Message : 272|8@1+ (1,0) [0|255] ""  PCCM,TRANSMISSION,EBS
 SG_ EngDefaultTorqueLimit : 256|16@1+ (1,0) [0|64255] "Nm"  PCCM,TRANSMISSION,EBS
 SG_ EngMomentOfInertia : 240|16@1+ (0.004,0) [0|257.02] "kg-m²"  PCCM,TRANSMISSION,EBS
 SG_ EngExRngRqdSpdCtrlRngUpperLimit : 224|16@1+ (0.125,0) [0|8031.875] "rpm"  PCCM,TRANSMISSION,EBS
 SG_ EngRqdTorqueCtrlRangeUpperLimit : 216|8@1+ (1,-125) [-125|125] "%"  PCCM,TRANSMISSION,EBS
 SG_ EngRqdTorqueCtrlRangeLowerLimit : 208|8@1+ (1,-125) [-125|125] "%"  PCCM,TRANSMISSION,EBS
 SG_ EngRqedSpeedCtrlRangeUpperLimit : 200|8@1+ (10,0) [0|2500] "rpm"  PCCM,TRANSMISSION,EBS
 SG_ EngRqedSpeedCtrlRangeLowerLimit : 192|8@1+ (10,0) [0|2500] "rpm"  PCCM,TRANSMISSION,EBS
 SG_ EngMxMomentaryOverrideTimeLimit : 184|8@1+ (0.1,0) [0|25] "s"  PCCM,TRANSMISSION,EBS
 SG_ EngMxMmntaryOverrideSpeedPoint7 : 168|16@1+ (0.125,0) [0|8031.875] "rpm"  PCCM,TRANSMISSION,EBS
 SG_ EngReferenceTorque : 152|16@1+ (1,0) [0|64255] "Nm"  PCCM,TRANSMISSION,EBS
 SG_ EngSpeedAtHighIdlePoint6 : 120|16@1+ (0.125,0) [0|8031.875] "rpm"  PCCM,TRANSMISSION,EBS
 SG_ EngGainOfEndspeedGovernor : 136|16@1+ (0.00078125,0) [0|50.2] "%/rpm"  PCCM,TRANSMISSION,EBS
 SG_ EngPercentTorqueAtPoint5 : 112|8@1+ (1,-125) [-125|125] "%"  PCCM,TRANSMISSION,EBS
 SG_ EngSpeedAtPoint5 : 96|16@1+ (0.125,0) [0|8031.875] "rpm"  PCCM,TRANSMISSION,EBS
 SG_ EngPercentTorqueAtPoint4 : 88|8@1+ (1,-125) [-125|125] "%"  PCCM,TRANSMISSION,EBS
 SG_ EngSpeedAtPoint4 : 72|16@1+ (0.125,0) [0|8031.875] "rpm"  PCCM,TRANSMISSION,EBS
 SG_ EngPercentTorqueAtPoint3 : 64|8@1+ (1,-125) [-125|125] "%"  PCCM,TRANSMISSION,EBS
 SG_ EngSpeedAtPoint3 : 48|16@1+ (0.125,0) [0|8031.875] "rpm"  PCCM,TRANSMISSION,EBS
 SG_ EngPercentTorqueAtPoint2 : 40|8@1+ (1,-125) [-125|125] "%"  PCCM,TRANSMISSION,EBS
 SG_ EngSpeedAtPoint2 : 24|16@1+ (0.125,0) [0|8031.875] "rpm"  PCCM,TRANSMISSION,EBS
 SG_ EngPercentTorqueAtIdlePoint1 : 16|8@1+ (1,-125) [-125|125] "%"  PCCM,TRANSMISSION,EBS
 SG_ EngSpeedAtIdlePoint1 : 0|16@1+ (0.125,0) [0|8031.875] "rpm"  PCCM,TRANSMISSION,EBS

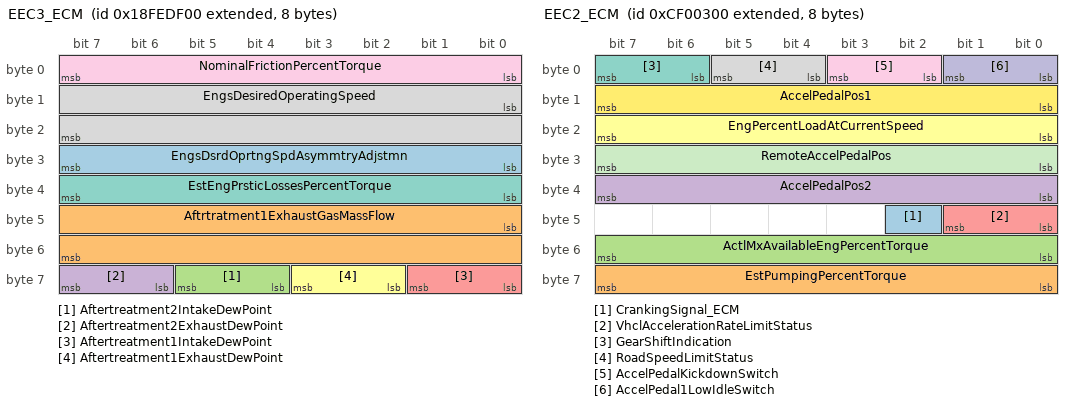
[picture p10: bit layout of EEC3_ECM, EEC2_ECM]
BO_ 2566840064 EEC3_ECM: 8 ENGINE_CONTROL_MODULE
 SG_ EngsDsrdOprtngSpdAsymmtryAdjstmn : 24|8@1+ (1,0) [0|250] ""  PCCM,TRANSMISSION,EBS,RADAR
 SG_ Aftrtratment1ExhaustGasMassFlow : 40|16@1+ (0.2,0) [0|12851] "kg/h"  PCCM,TRANSMISSION,EBS,RADAR
 SG_ Aftertreatment2IntakeDewPoint : 60|2@1+ (1,0) [0|3] ""  PCCM,TRANSMISSION,EBS,RADAR
 SG_ Aftertreatment2ExhaustDewPoint : 62|2@1+ (1,0) [0|3] ""  PCCM,TRANSMISSION,EBS,RADAR
 SG_ Aftertreatment1IntakeDewPoint : 56|2@1+ (1,0) [0|3] ""  PCCM,TRANSMISSION,EBS,RADAR
 SG_ Aftertreatment1ExhaustDewPoint : 58|2@1+ (1,0) [0|3] ""  PCCM,TRANSMISSION,EBS,RADAR
 SG_ EstEngPrsticLossesPercentTorque : 32|8@1+ (1,-125) [0|125] "%"  PCCM,TRANSMISSION,EBS,RADAR
 SG_ EngsDesiredOperatingSpeed : 8|16@1+ (0.125,0) [0|8031.875] "rpm"  PCCM,TRANSMISSION,EBS,RADAR
 SG_ NominalFrictionPercentTorque : 0|8@1+ (1,-125) [0|125] "%"  PCCM,TRANSMISSION,EBS,RADAR

BO_ 2364539648 EEC2_ECM: 8 ENGINE_CONTROL_MODULE
 SG_ CrankingSignal_ECM : 42|1@1+ (1,0) [0|1] ""  E_APU,PCCM,TRANSMISSION,INTARDER,EBS,RADAR,BCM
 SG_ EstPumpingPercentTorque : 56|8@1+ (1,-125) [-125|125] "%"  E_APU,PCCM,TRANSMISSION,INTARDER,EBS,RADAR,BCM
 SG_ ActlMxAvailableEngPercentTorque : 48|8@1+ (0.4,0) [0|100] "%"  E_APU,PCCM,TRANSMISSION,INTARDER,EBS,RADAR,BCM
 SG_ AccelPedalPos2 : 32|8@1+ (0.4,0) [0|100] "%"  E_APU,PCCM,TRANSMISSION,INTARDER,EBS,RADAR,BCM
 SG_ VhclAccelerationRateLimitStatus : 40|2@1+ (1,0) [0|3] ""  E_APU,PCCM,TRANSMISSION,INTARDER,EBS,RADAR,BCM
 SG_ EngPercentLoadAtCurrentSpeed : 16|8@1+ (1,0) [0|250] "%"  E_APU,PCCM,TRANSMISSION,INTARDER,EBS,RADAR,BCM
 SG_ GearShiftIndication : 6|2@1+ (1,0) [0|3] ""  E_APU,PCCM,TRANSMISSION,INTARDER,EBS,RADAR,BCM
 SG_ RoadSpeedLimitStatus : 4|2@1+ (1,0) [0|3] ""  E_APU,PCCM,TRANSMISSION,INTARDER,EBS,RADAR,BCM
 SG_ AccelPedalKickdownSwitch : 2|2@1+ (1,0) [0|3] ""  E_APU,PCCM,TRANSMISSION,INTARDER,EBS,RADAR,BCM
 SG_ AccelPedal1LowIdleSwitch : 0|2@1+ (1,0) [0|3] ""  E_APU,PCCM,TRANSMISSION,INTARDER,EBS,RADAR,BCM
 SG_ RemoteAccelPedalPos : 24|8@1+ (0.4,0) [0|100] "%"  E_APU,PCCM,TRANSMISSION,INTARDER,EBS,RADAR,BCM
 SG_ AccelPedalPos1 : 8|8@1+ (0.4,0) [0|100] "%"  E_APU,PCCM,TRANSMISSION,INTARDER,EBS,RADAR,BCM

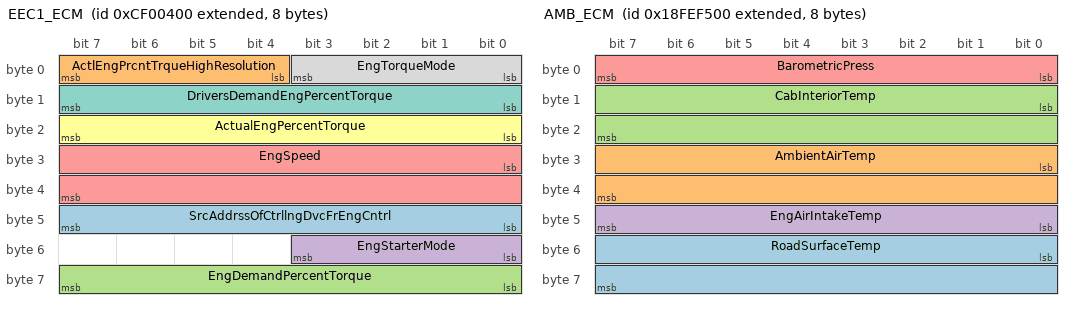
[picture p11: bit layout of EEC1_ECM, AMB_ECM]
BO_ 2364539904 EEC1_ECM: 8 ENGINE_CONTROL_MODULE
 SG_ SrcAddrssOfCtrllngDvcFrEngCntrl : 40|8@1+ (1,0) [0|255] ""  CAMERA,E_APU,PCCM,TPMS,TRANSMISSION,INTARDER,EBS,RADAR,INSTRUMENT_CLUSTER,BCM
 SG_ ActlEngPrcntTrqueHighResolution : 4|4@1+ (0.125,0) [0|0.875] "%"  CAMERA,E_APU,PCCM,TPMS,TRANSMISSION,INTARDER,EBS,RADAR,INSTRUMENT_CLUSTER,BCM
 SG_ EngDemandPercentTorque : 56|8@1+ (1,-125) [0|125] "%"  CAMERA,E_APU,PCCM,TPMS,TRANSMISSION,INTARDER,EBS,RADAR,INSTRUMENT_CLUSTER,BCM
 SG_ EngStarterMode : 48|4@1+ (1,0) [0|15] ""  CAMERA,E_APU,PCCM,TPMS,TRANSMISSION,INTARDER,EBS,RADAR,INSTRUMENT_CLUSTER,BCM
 SG_ EngSpeed : 24|16@1+ (0.125,0) [0|8031.875] "rpm"  CAMERA,E_APU,PCCM,TPMS,TRANSMISSION,INTARDER,EBS,RADAR,INSTRUMENT_CLUSTER,BCM
 SG_ ActualEngPercentTorque : 16|8@1+ (1,-125) [0|125] "%"  CAMERA,E_APU,PCCM,TPMS,TRANSMISSION,INTARDER,EBS,RADAR,INSTRUMENT_CLUSTER,BCM
 SG_ DriversDemandEngPercentTorque : 8|8@1+ (1,-125) [0|125] "%"  CAMERA,E_APU,PCCM,TPMS,TRANSMISSION,INTARDER,EBS,RADAR,INSTRUMENT_CLUSTER,BCM
 SG_ EngTorqueMode : 0|4@1+ (1,0) [0|15] ""  CAMERA,E_APU,PCCM,TPMS,TRANSMISSION,INTARDER,EBS,RADAR,INSTRUMENT_CLUSTER,BCM

BO_ 2566844672 CCVS_ECM: 8 ENGINE_CONTROL_MODULE
 SG_ PTOGovernorState_CCVS_ECM : 48|5@1+ (1,0) [0|31] ""  E_APU,PCCM,TRANSMISSION,INTARDER,EBS,RADAR,INSTRUMENT_CLUSTER,BCM
 SG_ EngShutdownOverrideSwitch : 62|2@1+ (1,0) [0|3] ""  E_APU,PCCM,TRANSMISSION,INTARDER,EBS,RADAR,INSTRUMENT_CLUSTER,BCM
 SG_ EngTestModeSwitch : 60|2@1+ (1,0) [0|3] ""  E_APU,PCCM,TRANSMISSION,INTARDER,EBS,RADAR,INSTRUMENT_CLUSTER,BCM
 SG_ EngIdleDecrementSwitch : 58|2@1+ (1,0) [0|3] ""  E_APU,PCCM,TRANSMISSION,INTARDER,EBS,RADAR,INSTRUMENT_CLUSTER,BCM
 SG_ EngIdleIncrementSwitch : 56|2@1+ (1,0) [0|3] ""  E_APU,PCCM,TRANSMISSION,INTARDER,EBS,RADAR,INSTRUMENT_CLUSTER,BCM
 SG_ CruiseCtrlStates : 53|3@1+ (1,0) [0|7] ""  E_APU,PCCM,TRANSMISSION,INTARDER,EBS,RADAR,INSTRUMENT_CLUSTER,BCM
 SG_ CruiseCtrlSetSpeed : 40|8@1+ (1,0) [0|250] "km/h"  E_APU,PCCM,TRANSMISSION,INTARDER,EBS,RADAR,INSTRUMENT_CLUSTER,BCM
 SG_ CruiseCtrlAccelerateSwitch_CCVSE : 38|2@1+ (1,0) [0|3] ""  E_APU,PCCM,TRANSMISSION,INTARDER,EBS,RADAR,INSTRUMENT_CLUSTER,BCM
 SG_ CruiseCtrlResumeSwitch_CCVS_ECM : 36|2@1+ (1,0) [0|3] ""  E_APU,PCCM,TRANSMISSION,INTARDER,EBS,RADAR,INSTRUMENT_CLUSTER,BCM
 SG_ CruiseCtrlCoastSwitch_CCVS_ECM : 34|2@1+ (1,0) [0|3] ""  E_APU,PCCM,TRANSMISSION,INTARDER,EBS,RADAR,INSTRUMENT_CLUSTER,BCM
 SG_ CruiseCtrlSetSwitch : 32|2@1+ (1,0) [0|3] ""  E_APU,PCCM,TRANSMISSION,INTARDER,EBS,RADAR,INSTRUMENT_CLUSTER,BCM
 SG_ ClutchSwitch_CCVS_ECM : 30|2@1+ (1,0) [0|3] ""  E_APU,PCCM,TRANSMISSION,INTARDER,EBS,RADAR,INSTRUMENT_CLUSTER,BCM
 SG_ BrakeSwitch_CCVS_ECM : 28|2@1+ (1,0) [0|3] ""  E_APU,PCCM,TRANSMISSION,INTARDER,EBS,RADAR,INSTRUMENT_CLUSTER,BCM
 SG_ CruiseCtrlEnableSwitch : 26|2@1+ (1,0) [0|3] ""  E_APU,PCCM,TRANSMISSION,INTARDER,EBS,RADAR,INSTRUMENT_CLUSTER,BCM
 SG_ CruiseCtrlActive : 24|2@1+ (1,0) [0|3] ""  E_APU,PCCM,TRANSMISSION,INTARDER,EBS,RADAR,INSTRUMENT_CLUSTER,BCM
 SG_ WheelBasedVehicleSpeed_CCVS_ECM : 8|16@1+ (0.00390625,0) [0|251] "km/h"  E_APU,PCCM,TRANSMISSION,INTARDER,EBS,RADAR,INSTRUMENT_CLUSTER,BCM
 SG_ ParkingBrakeSwitch_CCVS_ECM : 2|2@1+ (1,0) [0|3] ""  E_APU,PCCM,TRANSMISSION,INTARDER,EBS,RADAR,INSTRUMENT_CLUSTER,BCM

BO_ 2566845696 AMB_ECM: 8 ENGINE_CONTROL_MODULE
 SG_ RoadSurfaceTemp : 48|16@1+ (1,-273) [-40|210] "deg C"  E_APU,PCCM,TPMS,TRANSMISSION,EBS,BCM
 SG_ AmbientAirTemp : 24|16@1+ (0.03125,-273) [-273|1734.96875] "deg C"  E_APU,PCCM,TPMS,TRANSMISSION,EBS,BCM
 SG_ CabInteriorTemp : 8|16@1+ (0.03125,-273) [-273|1774.96875] "deg C"  E_APU,PCCM,TPMS,TRANSMISSION,EBS,BCM
 SG_ EngAirIntakeTemp : 40|8@1+ (1,-40) [-40|210] "deg C"  E_APU,PCCM,TPMS,TRANSMISSION,EBS,BCM
 SG_ BarometricPress : 0|8@1+ (0.5,0) [0|125] "kPa"  E_APU,PCCM,TPMS,TRANSMISSION,EBS,BCM

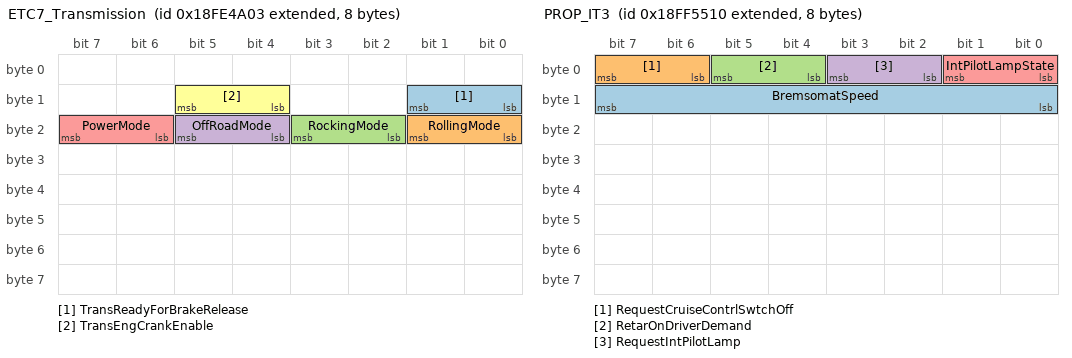
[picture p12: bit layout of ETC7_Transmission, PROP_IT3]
BO_ 2566801923 ETC7_Transmission: 8 TRANSMISSION
 SG_ TransReadyForBrakeRelease : 8|2@1+ (1,0) [0|3] ""  PCCM,ENGINE_CONTROL_MODULE,EBS,INSTRUMENT_CLUSTER,BCM
 SG_ RollingMode : 16|2@1+ (1,0) [0|3] ""  PCCM,ENGINE_CONTROL_MODULE,EBS,INSTRUMENT_CLUSTER,BCM
 SG_ RockingMode : 18|2@1+ (1,0) [0|3] ""  PCCM,ENGINE_CONTROL_MODULE,EBS,INSTRUMENT_CLUSTER,BCM
 SG_ OffRoadMode : 20|2@1+ (1,0) [0|3] ""  PCCM,ENGINE_CONTROL_MODULE,EBS,INSTRUMENT_CLUSTER,BCM
 SG_ PowerMode : 22|2@1+ (1,0) [0|3] ""  PCCM,ENGINE_CONTROL_MODULE,EBS,INSTRUMENT_CLUSTER,BCM
 SG_ TransEngCrankEnable : 12|2@1+ (1,0) [0|3] ""  PCCM,ENGINE_CONTROL_MODULE,EBS,INSTRUMENT_CLUSTER,BCM

BO_ 2565406224 DM3_ACKM_Intarder: 8 INTARDER
 SG_ AddressBusy m3 : 32|8@1+ (1,0) [0|255] ""  PCCM
 SG_ ControlByte M : 0|8@1+ (1,0) [0|255] ""  PCCM
 SG_ ParameterGroupNumber : 40|24@1+ (1,0) [0|16777215] ""  PCCM
 SG_ GroupFunctionValue : 8|8@1+ (1,0) [0|255] ""  PCCM
 SG_ AddressAccessDenied m2 : 32|8@1+ (1,0) [0|255] ""  PCCM
 SG_ AddressNegativeAcknowledgement m1 : 32|8@1+ (1,0) [0|255] ""  PCCM
 SG_ AddressAcknowledged m0 : 32|8@1+ (1,0) [0|255] ""  PCCM

BO_ 2566870288 PROP_IT3: 8 INTARDER
 SG_ BremsomatSpeed : 8|8@1+ (0.5,0) [0|125] ""  RMFS,PCCM,ENGINE_CONTROL_MODULE,BCM
 SG_ RequestCruiseContrlSwtchOff : 6|2@1+ (1,0) [0|3] ""  RMFS,PCCM,ENGINE_CONTROL_MODULE
 SG_ RetarOnDriverDemand : 4|2@1+ (1,0) [0|3] ""  RMFS,PCCM,ENGINE_CONTROL_MODULE
 SG_ RequestIntPilotLamp : 2|2@1+ (1,0) [0|3] ""  RMFS,PCCM,ENGINE_CONTROL_MODULE
 SG_ IntPilotLampState : 0|2@1+ (1,0) [0|3] ""  RMFS,PCCM,ENGINE_CONTROL_MODULE

BO_ 2566810606 DI_TACHOGRAPH: 8 TACHOGRAPH
 SG_ Driver2 : 8|8@1+ (1,0) [0|255] ""  PCCM,BCM
 SG_ Driver1 : 0|8@1+ (1,0) [0|255] ""  PCCM,BCM

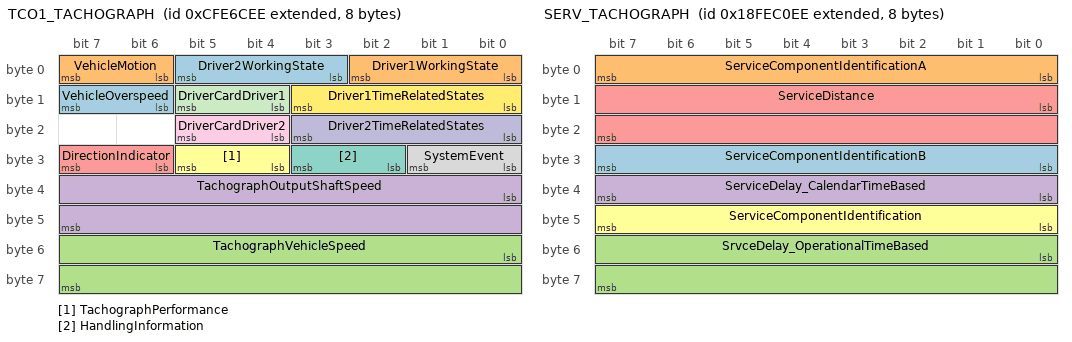
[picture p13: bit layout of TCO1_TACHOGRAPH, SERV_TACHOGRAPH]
BO_ 2365484270 TCO1_TACHOGRAPH: 8 TACHOGRAPH
 SG_ VehicleOverspeed : 14|2@1+ (1,0) [0|3] ""  PCCM,TPMS,TRANSMISSION,INTARDER,ENGINE_CONTROL_MODULE,EBS,INSTRUMENT_CLUSTER,BCM
 SG_ VehicleMotion : 6|2@1+ (1,0) [0|3] ""  PCCM,TPMS,TRANSMISSION,INTARDER,ENGINE_CONTROL_MODULE,EBS,INSTRUMENT_CLUSTER,BCM
 SG_ TachographVehicleSpeed : 48|16@1+ (0.00390625,0) [0|250.996] "km/h"  PCCM,TPMS,TRANSMISSION,INTARDER,ENGINE_CONTROL_MODULE,EBS,INSTRUMENT_CLUSTER,BCM
 SG_ TachographOutputShaftSpeed : 32|16@1+ (0.125,0) [0|8031.875] "rpm"  PCCM,TPMS,TRANSMISSION,INTARDER,ENGINE_CONTROL_MODULE,EBS,INSTRUMENT_CLUSTER,BCM
 SG_ DirectionIndicator : 30|2@1+ (1,0) [0|3] ""  PCCM,TPMS,TRANSMISSION,INTARDER,ENGINE_CONTROL_MODULE,EBS,INSTRUMENT_CLUSTER,BCM
 SG_ TachographPerformance : 28|2@1+ (1,0) [0|3] ""  PCCM,TPMS,TRANSMISSION,INTARDER,ENGINE_CONTROL_MODULE,EBS,INSTRUMENT_CLUSTER,BCM
 SG_ HandlingInformation : 26|2@1+ (1,0) [0|3] ""  PCCM,TPMS,TRANSMISSION,INTARDER,ENGINE_CONTROL_MODULE,EBS,INSTRUMENT_CLUSTER,BCM
 SG_ SystemEvent : 24|2@1+ (1,0) [0|3] ""  PCCM,TPMS,TRANSMISSION,INTARDER,ENGINE_CONTROL_MODULE,EBS,INSTRUMENT_CLUSTER,BCM
 SG_ DriverCardDriver2 : 20|2@1+ (1,0) [0|3] ""  PCCM,TPMS,TRANSMISSION,INTARDER,ENGINE_CONTROL_MODULE,EBS,INSTRUMENT_CLUSTER,BCM
 SG_ Driver2TimeRelatedStates : 16|4@1+ (1,0) [0|15] ""  PCCM,TPMS,TRANSMISSION,INTARDER,ENGINE_CONTROL_MODULE,EBS,INSTRUMENT_CLUSTER,BCM
 SG_ DriverCardDriver1 : 12|2@1+ (1,0) [0|3] ""  PCCM,TPMS,TRANSMISSION,INTARDER,ENGINE_CONTROL_MODULE,EBS,INSTRUMENT_CLUSTER,BCM
 SG_ Driver1TimeRelatedStates : 8|4@1+ (1,0) [0|15] ""  PCCM,TPMS,TRANSMISSION,INTARDER,ENGINE_CONTROL_MODULE,EBS,INSTRUMENT_CLUSTER,BCM
 SG_ Driver2WorkingState : 3|3@1+ (1,0) [0|7] ""  PCCM,TPMS,TRANSMISSION,INTARDER,ENGINE_CONTROL_MODULE,EBS,INSTRUMENT_CLUSTER,BCM
 SG_ Driver1WorkingState : 0|3@1+ (1,0) [0|7] ""  PCCM,TPMS,TRANSMISSION,INTARDER,ENGINE_CONTROL_MODULE,EBS,INSTRUMENT_CLUSTER,BCM

BO_ 2566832366 SERV_TACHOGRAPH: 8 TACHOGRAPH
 SG_ ServiceComponentIdentificationB : 24|8@1+ (1,0) [0|250] "ID"  BCM,PCCM
 SG_ ServiceComponentIdentificationA : 0|8@1+ (1,0) [0|250] "ID"  BCM,PCCM
 SG_ SrvceDelay_OperationalTimeBased : 48|16@1+ (1,-32127) [-32127|32128] "hr"  BCM,PCCM
 SG_ ServiceDelay_CalendarTimeBased : 32|8@1+ (1,-125) [-125|125] "weeks"  BCM,PCCM
 SG_ ServiceDistance : 8|16@1+ (5,-160635) [-160635|160640] "km"  BCM,PCCM
 SG_ ServiceComponentIdentification : 40|8@1+ (1,0) [0|250] "ID"  BCM,PCCM

BO_ 2566832622 VDHR_TACHOGRAPH: 8 TACHOGRAPH
 SG_ HighResolutionTripDistance : 32|32@1+ (5,0) [0|1410065403] "m"  PCCM,TRANSMISSION,ENGINE_CONTROL_MODULE,EBS,CAMERA,RADAR,INSTRUMENT_CLUSTER,BCM
 SG_ HghRslutionTotalVehicleDistance : 0|32@1+ (5,0) [0|1410065403] "m"  PCCM,TRANSMISSION,ENGINE_CONTROL_MODULE,EBS,CAMERA,RADAR,INSTRUMENT_CLUSTER,BCM

BO_ 2566843630 VI_TACHOGRAPH: 8 TACHOGRAPH
 SG_ VehicleIdentificationNumber : 0|8@1+ (1,0) [0|255] ""  PCCM,BCM

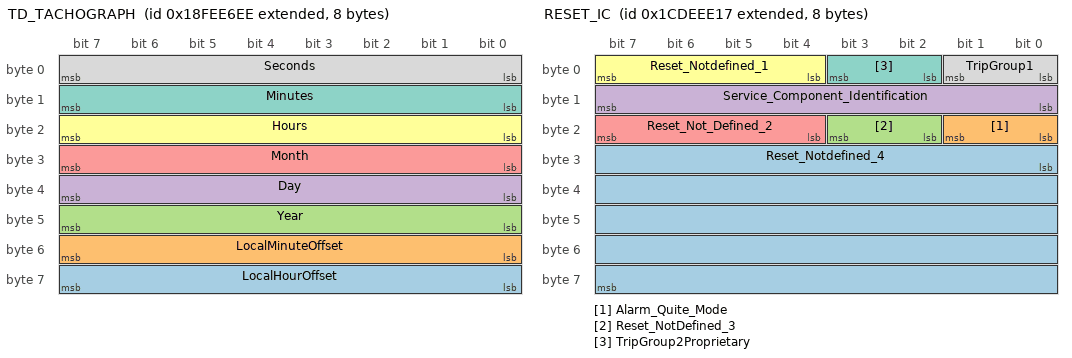
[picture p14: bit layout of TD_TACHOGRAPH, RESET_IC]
BO_ 2566842094 TD_TACHOGRAPH: 8 TACHOGRAPH
 SG_ LocalHourOffset : 56|8@1+ (1,-125) [-125|125] "hr"  E_APU,PCCM,TPMS,TRANSMISSION,ENGINE_CONTROL_MODULE,EBS,CAMERA,RADAR,INSTRUMENT_CLUSTER,BCM
 SG_ LocalMinuteOffset : 48|8@1+ (1,-125) [-125|125] "mins"  E_APU,PCCM,TPMS,TRANSMISSION,ENGINE_CONTROL_MODULE,EBS,CAMERA,RADAR,INSTRUMENT_CLUSTER,BCM
 SG_ Year : 40|8@1+ (1,1985) [1985|2235] "years"  E_APU,PCCM,TPMS,TRANSMISSION,ENGINE_CONTROL_MODULE,EBS,CAMERA,RADAR,INSTRUMENT_CLUSTER,BCM
 SG_ Day : 32|8@1+ (0.25,0) [1|31] "days"  E_APU,PCCM,TPMS,TRANSMISSION,ENGINE_CONTROL_MODULE,EBS,CAMERA,RADAR,INSTRUMENT_CLUSTER,BCM
 SG_ Month : 24|8@1+ (1,0) [1|12] "months"  E_APU,PCCM,TPMS,TRANSMISSION,ENGINE_CONTROL_MODULE,EBS,CAMERA,RADAR,INSTRUMENT_CLUSTER,BCM
 SG_ Hours : 16|8@1+ (1,0) [0|23] "hr"  E_APU,PCCM,TPMS,TRANSMISSION,ENGINE_CONTROL_MODULE,EBS,CAMERA,RADAR,INSTRUMENT_CLUSTER,BCM
 SG_ Minutes : 8|8@1+ (1,0) [0|59] "mins"  E_APU,PCCM,TPMS,TRANSMISSION,ENGINE_CONTROL_MODULE,EBS,CAMERA,RADAR,INSTRUMENT_CLUSTER,BCM
 SG_ Seconds : 0|8@1+ (0.25,0) [0|59.75] "s"  E_APU,PCCM,TPMS,TRANSMISSION,ENGINE_CONTROL_MODULE,EBS,CAMERA,RADAR,INSTRUMENT_CLUSTER,BCM

BO_ 2631855639 RESET_IC: 8 INSTRUMENT_CLUSTER
 SG_ Reset_Notdefined_4 : 24|40@1+ (1,0) [0|4294967295] ""  PCCM,TACHOGRAPH
 SG_ Alarm_Quite_Mode : 16|2@1+ (1,0) [0|3] ""  PCCM,TACHOGRAPH
 SG_ Reset_NotDefined_3 : 18|2@1+ (1,0) [0|3] ""  PCCM,TACHOGRAPH
 SG_ Service_Component_Identification : 8|8@1+ (1,0) [0|255] ""  PCCM,TACHOGRAPH
 SG_ Reset_Not_Defined_2 : 20|4@1+ (1,0) [0|15] ""  PCCM,TACHOGRAPH
 SG_ Reset_Notdefined_1 : 4|4@1+ (1,0) [0|15] ""  PCCM,TACHOGRAPH
 SG_ TripGroup2Proprietary : 2|2@1+ (1,0) [0|3] ""  PCCM,TACHOGRAPH
 SG_ TripGroup1 : 0|2@1+ (1,0) [0|3] ""  PCCM,TACHOGRAPH

BO_ 2566847511 DD_IC: 8 INSTRUMENT_CLUSTER
 SG_ FuelLevel1 : 8|8@1+ (0.4,0) [0|100] "%"  PCCM,ENGINE_CONTROL_MODULE,BCM
 SG_ CargoAmbientTemp : 32|16@1+ (0.03125,-273) [-273|1734.96875] "deg C"  PCCM,ENGINE_CONTROL_MODULE,BCM

BO_ 2566838551 AUXIO_R_IC: 8 INSTRUMENT_CLUSTER
 SG_ DataandLocationServicesSelection : 45|2@1+ (1,0) [0|2] ""  PCCM
 SG_ User_Connectivity_Selection : 43|2@1+ (1,0) [0|2] ""  PCCM
 SG_ CreepSelection : 38|2@1+ (1,0) [0|3] "bit"  TRANSMISSION
 SG_ Trip_Reset_2 : 31|2@0+ (1,0) [0|3] ""  PCCM
 SG_ Trip_Reset_1 : 29|2@0+ (1,0) [0|3] ""  PCCM
 SG_ LowCoolantLevel : 54|2@1+ (1,0) [0|3] ""  ENGINE_CONTROL_MODULE
 SG_ AirFilterRestriction : 52|2@1+ (1,0) [0|3] ""  ENGINE_CONTROL_MODULE
 SG_ EcoRollSelection : 26|2@1+ (1,0) [0|3] ""  ENGINE_CONTROL_MODULE,RMFS
 SG_ RaiseChassisHeight_AUXIO_R_IC : 58|1@1+ (1,0) [0|1] "SED"  ENGINE_CONTROL_MODULE,BCM,CAMERA,EBS,PCCM,RADAR
 SG_ LowerChassisHeight_AUXIO_R_IC : 57|1@1+ (1,0) [0|1] "SED"  ENGINE_CONTROL_MODULE,BCM,CAMERA,EBS,PCCM,RADAR
 SG_ RideHeightRequest_AUXIO_R_IC : 56|1@1+ (1,0) [0|1] "SED"  ENGINE_CONTROL_MODULE,CAMERA,EBS,PCCM,RADAR,BCM
 SG_ ClusterRideHeightReq_reserved : 59|5@1+ (1,0) [0|31] "SED"  ENGINE_CONTROL_MODULE,BCM,CAMERA,EBS,PCCM,RADAR
 SG_ DrvTips_Enable : 48|2@1+ (1,0) [0|3] "SED"  ENGINE_CONTROL_MODULE,BCM,CAMERA,EBS,PCCM,RADAR
 SG_ DrvEva_Reset : 50|2@1+ (1,0) [0|3] "SED"  ENGINE_CONTROL_MODULE,BCM,CAMERA,EBS,PCCM,RADAR
 SG_ ACCUsageDemand_AUXIO_R_IC : 40|2@1+ (1,0) [0|3] ""  ENGINE_CONTROL_MODULE,BCM,CAMERA,EBS,PCCM,RADAR
 SG_ ADASWarningMuteReq : 42|1@1+ (1,0) [0|1] "SED"  ENGINE_CONTROL_MODULE,BCM,CAMERA,EBS,PCCM,RADAR
 SG_ AuxI_O03_RetarderLeverPosition : 2|2@1+ (1,0) [0|3] ""  ENGINE_CONTROL_MODULE
 SG_ TrailerABSFullyOperational : 10|2@1+ (1,0) [0|3] "SED"  ENGINE_CONTROL_MODULE,PCCM,EBS,CAMERA,RADAR
 SG_ TrailerABSDetected : 12|2@1+ (1,0) [0|3] "SED"  ENGINE_CONTROL_MODULE,PCCM,EBS,CAMERA,RADAR
 SG_ TrailerConnected : 14|2@1+ (1,0) [0|3] "SED"  ENGINE_CONTROL_MODULE,PCCM,EBS,CAMERA,RADAR
 SG_ LanguageInfo : 32|6@1+ (1,0) [0|63] "unitless"  ENGINE_CONTROL_MODULE,PCCM,EBS,CAMERA,RADAR,BCM
 SG_ RainSensingActivation : 6|2@1+ (1,0) [0|3] "SED"  ENGINE_CONTROL_MODULE,PCCM,EBS,CAMERA,RADAR,BCM
 SG_ Autolock_Activation : 22|2@1+ (1,0) [0|3] "SED"  ENGINE_CONTROL_MODULE,PCCM,EBS,CAMERA,RADAR,BCM
 SG_ AuxI_O02_BlendingSwitchPos : 4|2@1+ (1,0) [0|3] ""  ENGINE_CONTROL_MODULE,PCCM,EBS,CAMERA,RADAR,BCM
 SG_ OTAUpdateRequest1 : 24|2@1+ (1,0) [0|3] "SED"  ENGINE_CONTROL_MODULE,PCCM,EBS,CAMERA,RADAR,BCM
 SG_ PCCLevelSelection : 18|4@1+ (1,0) [0|15] ""  ENGINE_CONTROL_MODULE,PCCM,EBS,CAMERA,RADAR,BCM
 SG_ CabinTiltSwitch : 16|2@1+ (1,0) [0|3] ""  ENGINE_CONTROL_MODULE,PCCM,EBS,CAMERA,RADAR,BCM
 SG_ LDWBuzzerStatus_AUXIO_R_IC : 0|2@1+ (1,0) [0|3] ""  ENGINE_CONTROL_MODULE,PCCM,EBS,CAMERA,RADAR,BCM

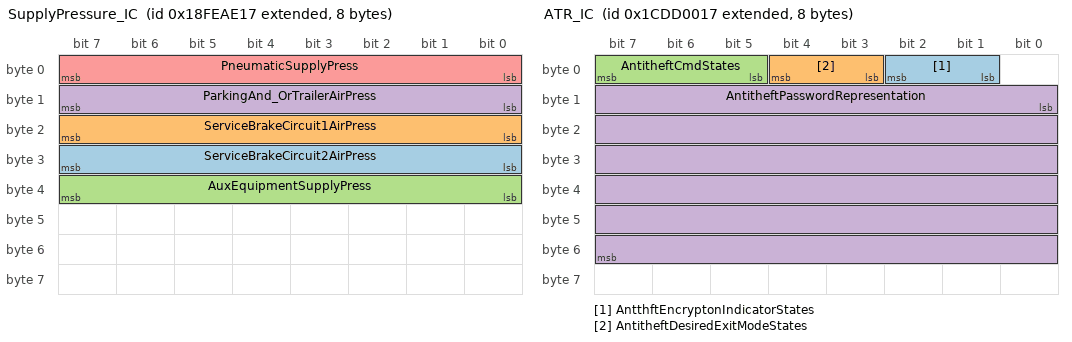
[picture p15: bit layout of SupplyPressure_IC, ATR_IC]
BO_ 2566827543 SupplyPressure_IC: 8 Vector__XXX
 SG_ ServiceBrakeCircuit2AirPress : 24|8@1+ (8,0) [0|2000] "kPa" Vector__XXX
 SG_ ServiceBrakeCircuit1AirPress : 16|8@1+ (8,0) [0|2000] "kPa" Vector__XXX
 SG_ AuxEquipmentSupplyPress : 32|8@1+ (8,0) [0|2000] "kPa" Vector__XXX
 SG_ ParkingAnd_OrTrailerAirPress : 8|8@1+ (8,0) [0|2000] "kPa" Vector__XXX
 SG_ PneumaticSupplyPress : 0|8@1+ (8,0) [0|2000] "kPa" Vector__XXX

BO_ 2565537534 RQST_IC: 3 Vector__XXX
 SG_ ParameterGroupNumber : 0|24@1+ (1,0) [0|16777215] "" Vector__XXX

BO_ 2631729175 ATR_IC: 8 INSTRUMENT_CLUSTER
 SG_ AntthftEncryptonIndicatorStates : 1|2@1+ (1,0) [0|3] ""  ENGINE_CONTROL_MODULE
 SG_ AntitheftDesiredExitModeStates : 3|2@1+ (1,0) [0|3] ""  ENGINE_CONTROL_MODULE
 SG_ AntitheftCmdStates : 5|3@1+ (1,0) [0|7] ""  ENGINE_CONTROL_MODULE
 SG_ AntitheftPasswordRepresentation : 8|48@1+ (1,0) [0|4] ""  ENGINE_CONTROL_MODULE

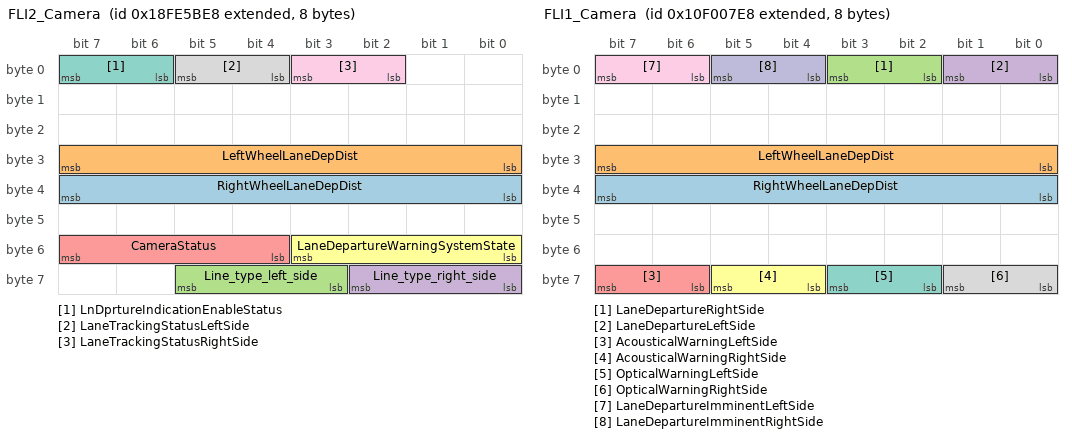
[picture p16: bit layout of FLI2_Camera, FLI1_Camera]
BO_ 2566806504 FLI2_Camera: 8 CAMERA
 SG_ RightWheelLaneDepDist : 32|8@1+ (1,-125) [-125|125] "cm"  PCCM
 SG_ LeftWheelLaneDepDist : 24|8@1+ (1,-125) [-125|125] "cm"  PCCM
 SG_ Line_type_left_side : 59|3@1+ (1,0) [0|7] ""  PCCM,INSTRUMENT_CLUSTER,BCM
 SG_ Line_type_right_side : 56|3@1+ (1,0) [0|7] ""  PCCM,INSTRUMENT_CLUSTER,BCM
 SG_ CameraStatus : 52|4@1+ (1,0) [0|15] ""  PCCM,INSTRUMENT_CLUSTER,BCM
 SG_ LaneDepartureWarningSystemState : 48|4@1+ (1,0) [0|15] ""  PCCM,INSTRUMENT_CLUSTER,BCM
 SG_ LnDprtureIndicationEnableStatus : 6|2@1+ (1,0) [0|3] ""  PCCM,INSTRUMENT_CLUSTER,BCM
 SG_ LaneTrackingStatusLeftSide : 4|2@1+ (1,0) [0|3] ""  PCCM,INSTRUMENT_CLUSTER,BCM
 SG_ LaneTrackingStatusRightSide : 2|2@1+ (1,0) [0|3] ""  PCCM,INSTRUMENT_CLUSTER,BCM

BO_ 2431649768 FLI1_Camera: 8 CAMERA
 SG_ RightWheelLaneDepDist : 32|8@1+ (1,-125) [-125|125] "cm"  PCCM,INSTRUMENT_CLUSTER
 SG_ LeftWheelLaneDepDist : 24|8@1+ (1,-125) [-125|125] "cm"  PCCM,INSTRUMENT_CLUSTER
 SG_ LaneDepartureRightSide : 2|2@1+ (1,0) [0|3] ""  PCCM,INSTRUMENT_CLUSTER
 SG_ LaneDepartureLeftSide : 0|2@1+ (1,0) [0|3] ""  PCCM,INSTRUMENT_CLUSTER
 SG_ AcousticalWarningLeftSide : 62|2@1+ (1,0) [0|3] ""  PCCM,INSTRUMENT_CLUSTER,BCM
 SG_ AcousticalWarningRightSide : 60|2@1+ (1,0) [0|3] ""  PCCM,INSTRUMENT_CLUSTER,BCM
 SG_ OpticalWarningLeftSide : 58|2@1+ (1,0) [0|3] ""  PCCM,INSTRUMENT_CLUSTER,BCM
 SG_ OpticalWarningRightSide : 56|2@1+ (1,0) [0|3] ""  PCCM,INSTRUMENT_CLUSTER,BCM
 SG_ LaneDepartureImminentLeftSide : 6|2@1+ (1,0) [0|3] ""  PCCM,INSTRUMENT_CLUSTER,BCM
 SG_ LaneDepartureImminentRightSide : 4|2@1+ (1,0) [0|3] ""  PCCM,INSTRUMENT_CLUSTER,BCM

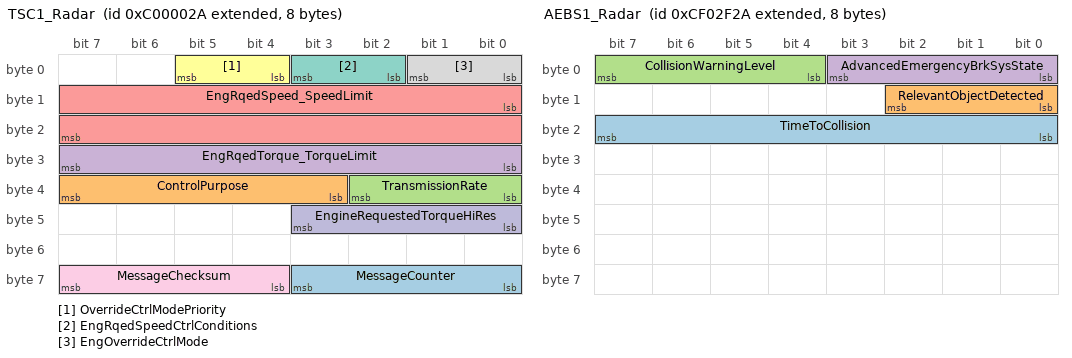
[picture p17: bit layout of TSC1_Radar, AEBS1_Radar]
BO_ 2348810282 TSC1_Radar: 8 RADAR
 SG_ MessageCounter : 56|4@1+ (1,0) [0|15] ""  PCCM,ENGINE_CONTROL_MODULE
 SG_ ControlPurpose : 35|5@1+ (1,0) [0|31] ""  PCCM,ENGINE_CONTROL_MODULE
 SG_ TransmissionRate : 32|3@1+ (1,0) [0|7] ""  PCCM,ENGINE_CONTROL_MODULE
 SG_ EngRqedTorque_TorqueLimit : 24|8@1+ (1,-125) [-125|125] "%"  PCCM,ENGINE_CONTROL_MODULE
 SG_ EngRqedSpeed_SpeedLimit : 8|16@1+ (0.125,0) [0|8031.875] "rpm"  PCCM,ENGINE_CONTROL_MODULE
 SG_ OverrideCtrlModePriority : 4|2@1+ (1,0) [0|3] ""  PCCM,ENGINE_CONTROL_MODULE
 SG_ EngRqedSpeedCtrlConditions : 2|2@1+ (1,0) [0|3] ""  PCCM,ENGINE_CONTROL_MODULE
 SG_ EngOverrideCtrlMode : 0|2@1+ (1,0) [0|3] ""  PCCM,ENGINE_CONTROL_MODULE
 SG_ MessageChecksum : 60|4@1+ (1,0) [0|15] ""  PCCM,ENGINE_CONTROL_MODULE
 SG_ EngineRequestedTorqueHiRes : 40|4@1+ (0.125,0) [0|0.875] "%"  PCCM,ENGINE_CONTROL_MODULE

BO_ 2364550954 AEBS1_Radar: 8 RADAR
 SG_ TimeToCollision : 16|8@1+ (0.05,0) [0|12.75] "s"  PCCM,TRANSMISSION,ENGINE_CONTROL_MODULE,INSTRUMENT_CLUSTER,BCM
 SG_ RelevantObjectDetected : 8|3@1+ (1,0) [0|7] ""  PCCM,TRANSMISSION,ENGINE_CONTROL_MODULE,INSTRUMENT_CLUSTER,BCM
 SG_ CollisionWarningLevel : 4|4@1+ (1,0) [0|15] ""  PCCM,TRANSMISSION,ENGINE_CONTROL_MODULE,INSTRUMENT_CLUSTER,BCM
 SG_ AdvancedEmergencyBrkSysState : 0|4@1+ (1,0) [0|15] ""  PCCM,TRANSMISSION,ENGINE_CONTROL_MODULE,INSTRUMENT_CLUSTER,BCM

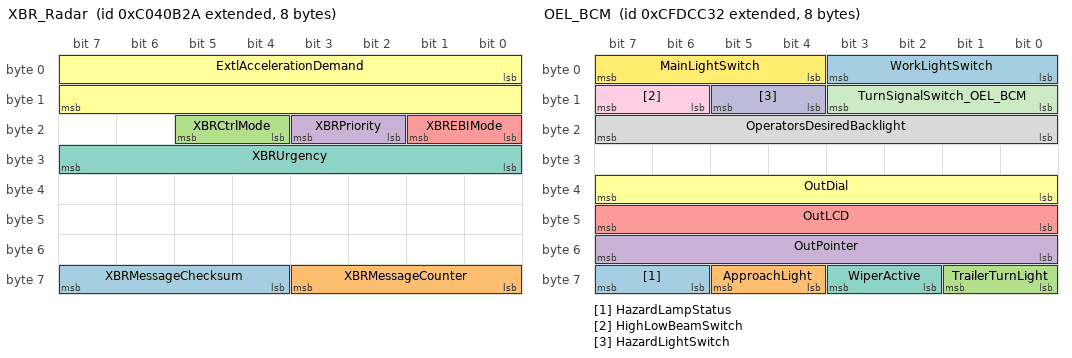
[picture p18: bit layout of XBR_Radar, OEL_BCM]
BO_ 2349075242 XBR_Radar: 8 RADAR
 SG_ XBRMessageChecksum : 60|4@1+ (1,0) [0|15] ""  PCCM,TRANSMISSION,EBS
 SG_ XBRMessageCounter : 56|4@1+ (1,0) [0|15] ""  PCCM,TRANSMISSION,EBS
 SG_ XBRCtrlMode : 20|2@1+ (1,0) [0|3] ""  PCCM,BCM,TRANSMISSION,EBS
 SG_ XBRPriority : 18|2@1+ (1,0) [0|3] ""  PCCM,TRANSMISSION,EBS
 SG_ XBREBIMode : 16|2@1+ (1,0) [0|3] ""  PCCM,TRANSMISSION,EBS
 SG_ ExtlAccelerationDemand : 0|16@1+ (0.00048828125,-15.687) [-15.687|15.687] "m/s²"  PCCM,TRANSMISSION,EBS
 SG_ XBRUrgency : 24|8@1+ (0.4,0) [0|100] "%"  PCCM,TRANSMISSION,EBS

BO_ 2365443122 OEL_BCM: 8 BCM
 SG_ HazardLampStatus : 62|2@1+ (1,0) [0|3] ""  PCCM,INSTRUMENT_CLUSTER
 SG_ ApproachLight : 60|2@1+ (1,0) [0|3] ""  PCCM
 SG_ TrailerTurnLight : 56|2@1+ (1,0) [0|3] ""  PCCM,CAMERA,RADAR
 SG_ OutPointer : 48|8@1+ (0.4,0) [0|100] "%"  PCCM,CAMERA,RADAR
 SG_ OutLCD : 40|8@1+ (0.4,0) [0|100] "%"  PCCM,CAMERA,RADAR
 SG_ OutDial : 32|8@1+ (0.4,0) [0|100] "%"  PCCM,CAMERA,RADAR
 SG_ WiperActive : 58|2@1+ (1,0) [0|3] ""  PCCM,CAMERA,RADAR
 SG_ OperatorsDesiredBacklight : 16|8@1+ (0.4,0) [0|100] "%"  PCCM,CAMERA,RADAR
 SG_ HighLowBeamSwitch : 14|2@1+ (1,0) [0|3] ""  PCCM,CAMERA,RADAR
 SG_ HazardLightSwitch : 12|2@1+ (1,0) [0|3] ""  PCCM,CAMERA,RADAR,INSTRUMENT_CLUSTER
 SG_ TurnSignalSwitch_OEL_BCM : 8|4@1+ (1,0) [0|15] ""  PCCM,CAMERA,RADAR,INSTRUMENT_CLUSTER
 SG_ MainLightSwitch : 4|4@1+ (1,0) [0|15] ""  PCCM,CAMERA,RADAR
 SG_ WorkLightSwitch : 0|4@1+ (1,0) [0|15] ""  PCCM,CAMERA,RADAR

BO_ 2561271841 FLIC_BCM: 8 BCM
 SG_ LDWBuzzerStatus_FLIC_BCM : 56|2@1+ (1,0) [0|3] ""  PCCM
 SG_ LaneDepartureWarningEnableCmd : 0|2@1+ (1,0) [0|3] ""  PCCM,CAMERA

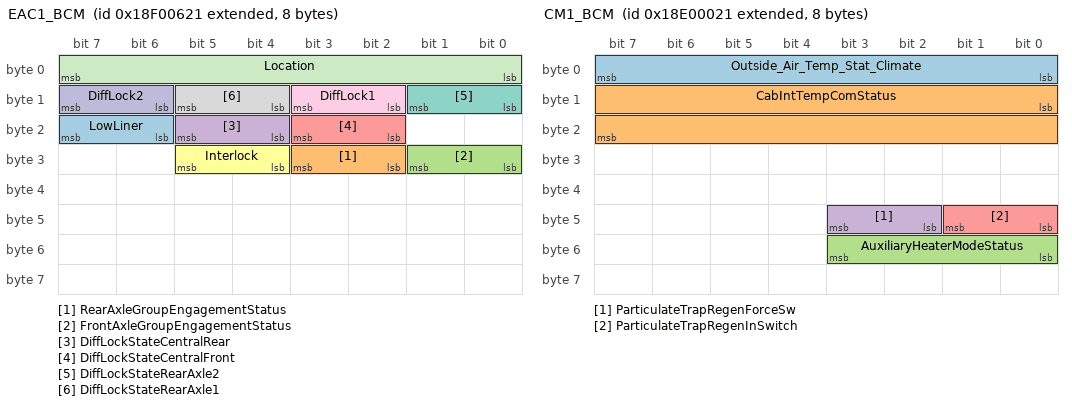
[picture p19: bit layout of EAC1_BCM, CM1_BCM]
BO_ 2565867041 EAC1_BCM: 8 BCM
 SG_ LowLiner : 22|2@1+ (1,0) [0|3] ""  PCCM,EBS,INSTRUMENT_CLUSTER
 SG_ RearAxleGroupEngagementStatus : 26|2@1+ (1,0) [0|3] ""  PCCM,EBS,INSTRUMENT_CLUSTER
 SG_ FrontAxleGroupEngagementStatus : 24|2@1+ (1,0) [0|3] ""  PCCM,EBS,INSTRUMENT_CLUSTER
 SG_ DiffLockStateCentralRear : 20|2@1+ (1,0) [0|3] ""  PCCM,EBS,INSTRUMENT_CLUSTER
 SG_ DiffLockStateCentralFront : 18|2@1+ (1,0) [0|3] ""  PCCM,EBS,INSTRUMENT_CLUSTER
 SG_ Interlock : 28|2@1+ (1,0) [0|3] ""  PCCM,EBS,INSTRUMENT_CLUSTER
 SG_ DiffLockStateRearAxle2 : 8|2@1+ (1,0) [0|3] ""  PCCM,EBS,INSTRUMENT_CLUSTER
 SG_ DiffLockStateRearAxle1 : 12|2@1+ (1,0) [0|3] ""  PCCM,EBS,INSTRUMENT_CLUSTER
 SG_ DiffLock1 : 10|2@1+ (1,0) [0|3] ""  PCCM,EBS,INSTRUMENT_CLUSTER
 SG_ DiffLock2 : 14|2@1+ (1,0) [0|3] ""  PCCM,EBS,INSTRUMENT_CLUSTER
 SG_ Location : 0|8@1+ (1,0) [0|255] ""  PCCM,EBS,INSTRUMENT_CLUSTER

BO_ 2564816929 CM1_BCM: 8 BCM
 SG_ Outside_Air_Temp_Stat_Climate : 0|8@1+ (0.5,-40) [-40|86.5] "Degrees C"  PCCM,INSTRUMENT_CLUSTER
 SG_ CabIntTempComStatus : 8|16@1+ (0.03125,-273) [-273|1734.96875] "deg C"  PCCM,ENGINE_CONTROL_MODULE
 SG_ AuxiliaryHeaterModeStatus : 48|4@1+ (1,0) [0|15] "SED"  PCCM,ENGINE_CONTROL_MODULE
 SG_ ParticulateTrapRegenForceSw : 42|2@1+ (1,0) [0|3] ""  PCCM,ENGINE_CONTROL_MODULE
 SG_ ParticulateTrapRegenInSwitch : 40|2@1+ (1,0) [0|3] ""  PCCM,ENGINE_CONTROL_MODULE

CM_ BO_ 2566843648 "Cruise Control/Vehicle Speed Setup";
CM_ BO_ 2566708224 "Adaptive Cruise Control";
CM_ SG_ 2566708224 CruiseCtrlSpeed "Value of set (chosen) velocity of velocity control system.";
CM_ SG_ 2566708224 CruiseCtrlSetSpeed_HighRes "Value of set (chosen) velocity of velocity control system.";
CM_ SG_ 2566708224 SAControlDeviceforPauseCC "Signal which indicates the level of the body height as an anser to 'ramp level request'.";
CM_ SG_ 2566708224 SAControlDeviceforDisableCC "Signal which indicates the level of the body height as an anser to 'ramp level request'.";
CM_ BO_ 2365512010 "Era glonass Emergency call message to BCM";
CM_ BO_ 2565475095 "Request";
CM_ SG_ 2565475095 ParameterGroupNumber "PGN which is requested by Request2 message";
CM_ BO_ 2565472279 "Request";
CM_ SG_ 2565472279 ParameterGroupNumber "PGN which is requested by Request2 message";
CM_ BO_ 2349465642 "Adaptive Cruise Control";
CM_ BO_ 2432593706 "Adaptive Cruise Control";
CM_ SG_ 2432593706 ForwardCollisionWarning "This parameter indicates if a collision is imminent and strong driver reaction either by braking hard or by an avoidance";
CM_ SG_ 2432593706 ACCDistanceAlertSignal "Signal to indicate to the operator that the ACC system is not able to maintain the distance to the target.";
CM_ SG_ 2432593706 ACCSystemShutoffWarning "Signal to warn the driver of system deactivation due to non-driver actions.";
CM_ SG_ 2432593706 ACCTargetDetected "Signal to indicate to the driver that the ACC system has detected a target.";
CM_ SG_ 2432593706 RoadCurvature "Estimated value of the current road curvature for use by the adaptive cruise control system.";
CM_ SG_ 2432593706 AdptveCruiseCtrlSetDistanceMode "Selected distance mode for adaptive cruise control.";
CM_ SG_ 2432593706 AdaptiveCruiseCtrlMode "This parameter is used to indicate the current state, or mode, of operation by the Adaptive Cruise Control (ACC) device.";
CM_ SG_ 2432593706 AdaptiveCruiseCtrlSetSpeed "Value of the desired (chosen) velocity of the adaptive cruise control system.";
CM_ SG_ 2432593706 DistanceToForwardVehicle "Distance to the preceding vehicle situated within 250 m in the same lane and moving in the same direction.";
CM_ SG_ 2432593706 SpeedOfForwardVehicle "Absolute velocity of the preceding vehicle situated within 250 m in the same lane and moving in the same direction.";
CM_ SG_ 2566838561 RqedACCDistanceMode "The Requested Distance Control Mode to the ACC system from the operators interface.";
CM_ SG_ 2566838561 AuxI_O08_GearboxNeutralPos_AUX1 "Identifies the current status of auxiliary input/output functions that are configured uniquely per application.";
CM_ SG_ 2566838561 AuxI_O07_TrailerABSFulOper_AUX1 "Identifies the current status of auxiliary input/output functions that are configured uniquely per application.";
CM_ SG_ 2566838561 AuxI_O06_TrailerABSDetected_AUX1 "Identifies the current status of auxiliary input/output functions that are configured uniquely per application.";
CM_ SG_ 2566838561 AuxI_O05_TrailerConnected_AUX1 "Identifies the current status of auxiliary input/output functions that are configured uniquely per application.";
CM_ BO_ 2564431089 "Tester command to PCCM";
CM_ BO_ 2564429809 "Tester command to CLUSTER";
CM_ BO_ 2564434673 "Tester command to RADAR";
CM_ BO_ 2564428017 "Tester command to INTARDER";
CM_ BO_ 2564436209 "Tester command to EAPU";
CM_ BO_ 2564423921 "Tester command to EBS";
CM_ BO_ 2564483313 "Tester command to CAMERA";
CM_ BO_ 2564432369 "Tester command to BCM";
CM_ BO_ 2564426737 "Tester command to EBS";
CM_ BO_ 2566827774 "Air Supply Pressure";
CM_ SG_ 2566827774 ServiceBrakeCircuit2AirPress "The pneumatic pressure in the secondary service brake circuit or reservoir, supplying the front axle.";
CM_ SG_ 2566827774 ServiceBrakeCircuit1AirPress "The pneumatic pressure in the primary service brake circuit or reservoir, supplying the rear axle.";
CM_ SG_ 2566827774 AirCompressorStatus "Indicates whether the air compressor is actively compressing air.";
CM_ SG_ 2566827774 AirSuspensionSupplyPress "The pneumatic pressure in the circuit for the electronically controlled air suspension system.";
CM_ SG_ 2566827774 AuxEquipmentSupplyPress "The pneumatic pressure in the auxiliary circuit.";
CM_ SG_ 2566827774 ParkingAnd_OrTrailerAirPress "The pneumatic pressure in the circuit or reservoir for the parking brake and/or the trailer supply.";
CM_ SG_ 2566827774 PneumaticSupplyPress "The pneumatic pressure in the main reservoir, sometimes referred to as the wet tank.";
CM_ BO_ 2565603114 "Transport Protocol - Data Transfer";
CM_ BO_ 2565668394 "Transport Protocol - Connection Management";
CM_ SG_ 2565668394 TotalNumberOfPacketsEoMA "Total number of packets for BAM message.Total number of packets received for RTS/CTS message.Total number of packets for RTS/CTS message.";
CM_ SG_ 2565668394 TotalMessageSizeEoMA "Total message size (in bytes) for BAM message.Total message size (in bytes) for RTS/CTS message.Total message size (in bytes) for RTS/CTS message.";
CM_ SG_ 2565668394 TotalMessageSizeBAM "Total message size (in bytes) for BAM message.Total message size (in bytes) for RTS/CTS message.Total message size (in bytes) for RTS/CTS message.";
CM_ SG_ 2565668394 TotalNumberOfPacketsBAM "Total number of packets for BAM message.Total number of packets received for RTS/CTS message.Total number of packets for RTS/CTS message.";
CM_ SG_ 2565668394 ConnectionAbortReason "Reason for connection abort message.";
CM_ SG_ 2565668394 NextPacketNumberToBeSent "Next Packet Number to be sent (TP.CM_CTS)";
CM_ SG_ 2565668394 NumberOfPacketsThatCanBeSent "Number of Packets that can be sent (TP.CM_CTS)";
CM_ SG_ 2565668394 MaximumNumberOfPackets "Maximum number of packets for RTS/CTS message.";
CM_ SG_ 2565668394 TotalNumberOfPackets "Total number of packets for BAM message.Total number of packets received for RTS/CTS message.Total number of packets for RTS/CTS message.";
CM_ SG_ 2565668394 TotalMessageSize "Total message size (in bytes) for BAM message.Total message size (in bytes) for RTS/CTS message.Total message size (in bytes) for RTS/CTS message.";
CM_ BO_ 2565603304 "Transport Protocol - Data Transfer";
CM_ BO_ 2565668840 "Transport Protocol - Connection Management";
CM_ SG_ 2565668840 TotalNumberOfPacketsEoMA "Total number of packets for BAM message.Total number of packets received for RTS/CTS message.Total number of packets for RTS/CTS message.";
CM_ SG_ 2565668840 TotalMessageSizeEoMA "Total message size (in bytes) for BAM message.Total message size (in bytes) for RTS/CTS message.Total message size (in bytes) for RTS/CTS message.";
CM_ SG_ 2565668840 TotalMessageSizeBAM "Total message size (in bytes) for BAM message.Total message size (in bytes) for RTS/CTS message.Total message size (in bytes) for RTS/CTS message.";
CM_ SG_ 2565668840 TotalNumberOfPacketsBAM "Total number of packets for BAM message.Total number of packets received for RTS/CTS message.Total number of packets for RTS/CTS message.";
CM_ SG_ 2565668840 ConnectionAbortReason "Reason for connection abort message.";
CM_ SG_ 2565668840 NextPacketNumberToBeSent "Next Packet Number to be sent (TP.CM_CTS)";
CM_ SG_ 2565668840 NumberOfPacketsThatCanBeSent "Number of Packets that can be sent (TP.CM_CTS)";
CM_ SG_ 2565668840 MaximumNumberOfPackets "Maximum number of packets for RTS/CTS message.";
CM_ SG_ 2565668840 TotalNumberOfPackets "Total number of packets for BAM message.Total number of packets received for RTS/CTS message.Total number of packets for RTS/CTS message.";
CM_ SG_ 2565668840 TotalMessageSize "Total message size (in bytes) for BAM message.Total message size (in bytes) for RTS/CTS message.Total message size (in bytes) for RTS/CTS message.";
CM_ SG_ 2565919516 PreCru_Ctrl_State "Value of set (chosen) velocity of velocity control system.";
CM_ SG_ 2565919516 PreCru_Ctrl_SetSpeedOffset "Value of set (chosen) velocity of velocity control system.";
CM_ SG_ 2565919516 PreCru_Ctrl_PresentGrade "Value of set (chosen) velocity of velocity control system.";
CM_ SG_ 2566848540 PCCMaxPosSpdOffset "The pneumatic pressure in the circuit for the electronically controlled air suspension system.";
CM_ SG_ 2566848540 PCCMaxNegSpdOffset "The pneumatic pressure in the circuit for the electronically controlled air suspension system.";
CM_ SG_ 2566848540 PCCM_BremsomatSetSpeed "Value of set (chosen) velocity of velocity control system.";
CM_ SG_ 2566832894 CruiseCtrlRetarderSpeedOffset "Value of set (chosen) velocity of velocity control system.";
CM_ SG_ 2558918398 Pre_Crus_Cnrt_MaxNeg_Offset "Value of set (chosen) velocity of velocity control system.";
CM_ SG_ 2558918398 Pre_Crus_Cnrt_MaxPoss_Offset "Value of set (chosen) velocity of velocity control system.";
CM_ BO_ 2631728651 "Anti-theft Status";
CM_ SG_ 2631728651 AntitheftRandomNumber "A seven byte random numeric code provided by the component in response to an anti-theft request.";
CM_ SG_ 2631728651 AntitheftComponentStatusStates "Indicates whether or not the component can be started.";
CM_ SG_ 2631728651 AntthftEncryptnSdPrsntIndicator "Indicates the presence of the encryption seed random number.";
CM_ SG_ 2631728651 AntitheftPwdValidIndicator "Indicates the presence of a validated password.";
CM_ BO_ 2631794218 "Anti-theft Request";
CM_ SG_ 2631794218 AntthftEncryptonIndicatorStates "This parameter is used to indicate if a random number seed is being requested, or if an encrypted password is being";
CM_ SG_ 2631794218 AntitheftCmdStates "This parameter is used to identify the specific requests being sent to the component.";
CM_ SG_ 2631794218 AntitheftPasswordRepresentation "This parameter is the seven byte numeric code (i.";
CM_ BO_ 2566775040 "Cab A/C Climate System Information";
CM_ SG_ 2566775040 CbA_CRfrgrntCmprssorOutletPress "This is the gage pressure at the compressor outlet in the cab air conditioning system.";
CM_ BO_ 2565668619 "Transport Protocol - Connection Management";
CM_ SG_ 2565668619 TotalNumberOfPacketsEoMA "Total number of packets for BAM message.Total number of packets received for RTS/CTS message.Total number of packets for RTS/CTS message.";
CM_ SG_ 2565668619 TotalMessageSizeEoMA "Total message size (in bytes) for BAM message.Total message size (in bytes) for RTS/CTS message.Total message size (in bytes) for RTS/CTS message.";
CM_ SG_ 2565668619 TotalMessageSizeBAM "Total message size (in bytes) for BAM message.Total message size (in bytes) for RTS/CTS message.Total message size (in bytes) for RTS/CTS message.";
CM_ SG_ 2565668619 TotalNumberOfPacketsBAM "Total number of packets for BAM message.Total number of packets received for RTS/CTS message.Total number of packets for RTS/CTS message.";
CM_ SG_ 2565668619 ConnectionAbortReason "Reason for connection abort message.";
CM_ SG_ 2565668619 NextPacketNumberToBeSent "Next Packet Number to be sent (TP.CM_CTS)";
CM_ SG_ 2565668619 NumberOfPacketsThatCanBeSent "Number of Packets that can be sent (TP.CM_CTS)";
CM_ SG_ 2565668619 MaximumNumberOfPackets "Maximum number of packets for RTS/CTS message.";
CM_ SG_ 2565668619 TotalNumberOfPackets "Total number of packets for BAM message.Total number of packets received for RTS/CTS message.Total number of packets for RTS/CTS message.";
CM_ SG_ 2565668619 TotalMessageSize "Total message size (in bytes) for BAM message.Total message size (in bytes) for RTS/CTS message.Total message size (in bytes) for RTS/CTS message.";
CM_ BO_ 2565603083 "Transport Protocol - Data Transfer";
CM_ SG_ 2566834920 OccurenceCount_Camera "SPN #1 (Conversion Version 4)";
CM_ SG_ 2566834920 FailureModeIdentifier1_Camera "The FMI defines the type of failure detected in the subsystem identified by an SPN.";
CM_ SG_ 2566834920 AmberWarningLampStatus_Camera "This lamp is used to relay trouble code information that is reporting a problem with the vehicle system but the vehicle need
not be immediately stopped.";
CM_ SG_ 2566834920 SPN4_Camera "SPN #1 (Conversion Version 4)";
CM_ SG_ 2566834920 SPN3_Camera "SPN #1 (Conversion Version 4)";
CM_ SG_ 2566834920 SPN2_Camera "SPN #1 (Conversion Version 4)";
CM_ SG_ 2566834920 SPN1_Camera "SPN #1 (Conversion Version 4)";
CM_ SG_ 2566834730 SPN4_Radar "SPN #1 (Conversion Version 4)";
CM_ SG_ 2566834730 SPN3_Radar "SPN #1 (Conversion Version 4)";
CM_ SG_ 2566834730 SPN2_Radar "SPN #1 (Conversion Version 4)";
CM_ SG_ 2566834730 SPN1_Radar "SPN #1 (Conversion Version 4)";
CM_ SG_ 2566834730 OccurenceCount_Radar "SPN #1 (Conversion Version 4)";
CM_ SG_ 2566834730 FailureModeIdentifier1_Radar "The FMI defines the type of failure detected in the subsystem identified by an SPN.";
CM_ SG_ 2566834730 AmberWarningLampStatus_Radar "This lamp is used to relay trouble code information that is reporting a problem with the vehicle system but the vehicle need
not be immediately stopped.";
CM_ SG_ 2348875776 TransMode1 "Indicates whether transmission mode 1 is enabled.";
CM_ SG_ 2566722593 BatteryRefresh "Request to activate the ABS off-road function. The switch signal is independent of an actual ABS control situation.";
CM_ BO_ 2566843134 "Vehicle Weight";
CM_ SG_ 2566843134 AxleLocation "To identify to which of several similar devices (such as tires or fuel tanks) the information applies.";
CM_ SG_ 2566843134 CargoWeight_30 "The mass of freight carried.";
CM_ SG_ 2566843134 CargoWeight_20 "The mass of freight carried.";
CM_ SG_ 2566843134 CargoWeight_10 "The mass of freight carried.";
CM_ SG_ 2566843134 CargoWeight_00 "The mass of freight carried.";
CM_ SG_ 2566843134 TrailerWeight_30 "Total mass of freight-carrying vehicle designed to be pulled by truck, including the weight of the contents.";
CM_ SG_ 2566843134 TrailerWeight_20 "Total mass of freight-carrying vehicle designed to be pulled by truck, including the weight of the contents.";
CM_ SG_ 2566843134 TrailerWeight_10 "Total mass of freight-carrying vehicle designed to be pulled by truck, including the weight of the contents.";
CM_ SG_ 2566843134 TrailerWeight_00 "Total mass of freight-carrying vehicle designed to be pulled by truck, including the weight of the contents.";
CM_ SG_ 2566843134 AxleWeight_30 "Total mass imposed by the tires on the road surface at the specified axle.";
CM_ SG_ 2566843134 AxleWeight_20 "Total mass imposed by the tires on the road surface at the specified axle.";
CM_ SG_ 2566843134 AxleWeight_10 "Total mass imposed by the tires on the road surface at the specified axle.";
CM_ SG_ 2566843134 AxleWeight_00 "Total mass imposed by the tires on the road surface at the specified axle.";
CM_ BO_ 2365479678 "Air Suspension Control 1";
CM_ SG_ 2365479678 SpeedDependantLevelCtrlStatus "This parameter indicates if the function Speed Dependant Level Control is active.";
CM_ SG_ 2365479678 MemoryLevel "Signal which indicates that the air suspension control has memory levels selected or stored.";
CM_ SG_ 2365479678 AllwLvelCtrlDuringBrakingStatus "This parameter indicates if the function Allow Level Control During Braking is active.";
CM_ SG_ 2365479678 SspensionCtrlRefusalInformation "Signal which indicates that the air suspension control cannot perform a request due to the operating conditions.";
CM_ SG_ 2365479678 SuspensionRemoteCtrl2 "Signal which indicates that the suspension system is controlled by remote control #2.";
CM_ SG_ 2365479678 SuspensionRemoteCtrl1 "Signal which indicates that the suspension system is controlled by remote control #1.";
CM_ SG_ 2365479678 RearAxleInBumperRange "Signal which indicates that the vehicle height at the rear axle (SPNs 1723 and 1724) is within the bumper range.";
CM_ SG_ 2365479678 FrontAxleInBumperRange "Signal which indicates that the vehicle height at the front axle (SPNs 1721 and 1722) is within the bumper range.";
CM_ SG_ 2365479678 DoorRelease "Signal which indicates that the doors may be opened.";
CM_ SG_ 2365479678 VehicleMotionInhibit "Signal which indicates whether vehicle motion is inhibited.";
CM_ SG_ 2365479678 SecurityDevice "The signal which indicates the status of the security device.";
CM_ SG_ 2365479678 LevelCtrlMode "Signal which indicates the actual control mode of the air suspension system";
CM_ SG_ 2365479678 KneelingInformation "Signal which indicates the actual level change in case of kneeling function";
CM_ SG_ 2365479678 LiftingCtrlModeRearAxle "Signal which indicates the actual lifting level change at the rear axle";
CM_ SG_ 2365479678 LiftingCtrlModeFrontAxle "Signal which indicates the actual lifting level change at the front axle";
CM_ SG_ 2365479678 LoweringCtrlModeRearAxle "Signal which indicates the actual lowering level change at the rear axle";
CM_ SG_ 2365479678 LoweringCtrlModeFrontAxle "Signal which indicates the actual lowering level change at the front axle";
CM_ SG_ 2365479678 AboveNominalLevelRearAxle "Signal which indicates whether the actual height of the rear axle is above the nominal (desired) level of the rear axle.";
CM_ SG_ 2365479678 AboveNominalLevelFrontAxle "Signal which indicates whether the actual height of the front axle is above the nominal (desired) level of the front axle.";
CM_ SG_ 2365479678 BelowNominalLevelRearAxle "Signal which indicates whether the actual height of the rear axle is below the nominal (desired) level for the rear axle.";
CM_ SG_ 2365479678 BelowNominalLevelFrontAxle "Signal which indicates whether the actual height of the front axle is below the nominal (desired) level for the front axle.";
CM_ SG_ 2365479678 NominalLevelRearAxle "Signal which indicates the nominal (desired) height of the rear axle to be controlled by the suspension system.";
CM_ SG_ 2365479678 NominalLevelFrontAxle "Signal which indicates the nominal (desired) height of the front axle to be controlled by the suspension system.";
CM_ SG_ 2365479678 LiftAxle2Pos "Signal which indicates the position / load condition of lift axle / tag axle #2.";
CM_ SG_ 2365479678 LiftAxle1Pos "Signal which indicates the position / load condition of lift axle / tag axle #1.";
CM_ BO_ 2566841344 "Shutdown";
CM_ SG_ 2566841344 EngineOperationMode "Signal which indicates the state of the engine start switch.";
CM_ SG_ 2566841344 EngOverspeedTest "The engine overspeed test signal as measured by the reporting ECM.";
CM_ SG_ 2566841344 EngAirShutoffCmdStatus "State signal which indicates when the Air Shutoff driver output is being driven.";
CM_ SG_ 2566841344 EngAlarmOutputCmdStatus "State signal which indicates when the Alarm driver output is being driven.";
CM_ SG_ 2566841344 EngAlarmAcknowledge "The Engine Alarm Acknowledge Input signal as measured by the reporting ECM.";
CM_ SG_ 2566841344 EngProtectionSystemConfig "Parameter which indicates the configuration of the engine shutdown system.";
CM_ SG_ 2566841344 EngProtectionSystemTimerState "Status signal which indicates the current mode of the engine protection system timer system.";
CM_ SG_ 2566841344 EngPrtectionSystemTimerOverride "Status signal which indicates the status of the override feature of the engine protection system timer.";
CM_ SG_ 2566841344 EngPrtctnSystmApprchingShutdown "Status signal which indicates that engine shutdown is imminent.";
CM_ SG_ 2566841344 EngWaitToStartLamp "Lamp signal which indicates that the engine is too cold to start and the operator should wait until the signal becomes";
CM_ SG_ 2566841344 RefrigerantHighPressSwitch "Switch signal which indicates the position of the high pressure switch in the coolant circuit of an air conditioning system.";
CM_ SG_ 2566841344 RefrigerantLowPressSwitch "Switch signal which indicates the position of the low pressure switch in the coolant circuit of an air conditioning system.";
CM_ SG_ 2566841344 A_CHighPressFanSwitch "Switch signal which indicates that the pressure in the coolant circuit of an air conditioning system is high and the fan may";
CM_ SG_ 2566841344 EngIdleShutdownTimerFunction "Parameter which indicates the configuration of the idle shutdown timer system.";
CM_ SG_ 2566841344 EngIdleShutdownTimerState "Status signal which indicates the current mode of operation of the idle shutdown timer system.";
CM_ SG_ 2566841344 EngIdleShutdownTimerOverride "Status signal which indicates the status of the override feature of the idle shutdown timer system.";
CM_ SG_ 2566841344 EngIdleShutdownDriverAlertMode "Status signal which indicates the status of the driver alert mode of the idle shutdown timer system.";
CM_ SG_ 2566841344 PTOShutdownHasShutdownEng "Status signal which identifies whether or not the engine has been shutdown by the PTO shutdown system.";
CM_ SG_ 2566841344 EngPrtctnSystmHasShutdownEngine "Status signal which indicates whether or not the engine protection system has shutdown the engine.";
CM_ SG_ 2566841344 EngIdlShutdownHasShutdownEngine "Status signal which identifies whether or not the engine has been shutdown by the idle shutdown timer system.";
CM_ SG_ 2566841344 EngAirShutoffStatus "State signal which indicates the actual measured position of the Air Shutoff.";
CM_ BO_ 2566848256 "Water in Fuel Indicator";
CM_ SG_ 2566848256 WaterInFuelIndicator "Signal which indicates the presence of water in the fuel.";
CM_ BO_ 2566719744 "High Resolution Fuel Consumption (Liquid)";
CM_ SG_ 2566719744 HighResolutionEngTotalFuelUsed "Accumulated amount of fuel used during vehicle operation.";
CM_ SG_ 2566719744 HighResolutionEngTripFuel "Fuel consumed during all or part of a journey.";
CM_ BO_ 2566844928 "Fuel Economy (Liquid)";
CM_ SG_ 2566844928 EngAverageFuelEconomy "Average of instantaneous fuel economy for that segment of vehicle operation of interest.";
CM_ SG_ 2566844928 EngInstantaneousFuelEconomy "Current fuel economy at current vehicle velocity.";
CM_ SG_ 2566844928 EngFuelRate "Amount of fuel consumed by engine per unit of time.";
CM_ SG_ 2566844928 EngThrottleValve1Pos "The position of the valve used to regulate the supply of a fluid, usually air or fuel/air mixture, to an engine.";
CM_ BO_ 2566831360 "Fan Drive";
CM_ SG_ 2566831360 FanSpeed "The speed of the fan associated with engine coolant system.";
CM_ SG_ 2566831360 FanDriveState "This parameter is used to indicate the current state or mode of operation by the fan drive.";
CM_ SG_ 2566831360 EstPercentFanSpeed "Estimated fan speed as a ratio of the fan drive (current speed) to the fully engaged fan drive (maximum fan speed).";
CM_ SG_ 2566831360 HydFanMotorPress "The hydraulic pressure used to drive the fan system, sensed before the hydraulic fan motor.";
CM_ SG_ 2566831360 FanDriveBypassCmdStatus "Status of the Fan Drive Bypass Command as being commanded by the ECU.";
CM_ BO_ 2566843904 "Engine Temperature 1";
CM_ SG_ 2566843904 EngFuelTemp1 "Temperature of fuel (or gas) passing through the first fuel control system.";
CM_ SG_ 2566843904 EngIntercoolerThermostatOpening "The current position of the thermostat used to regulate the temperature of the engine intercooler.";
CM_ SG_ 2566843904 EngIntercoolerTemp "Temperature of liquid found in the intercooler located after the turbocharger.";
CM_ SG_ 2566843904 EngTurboOilTemp "Temperature of the turbocharger lubricant.";
CM_ SG_ 2566843904 EngOilTemp1 "Temperature of the engine lubricant.";
CM_ SG_ 2566843904 EngCoolantTemp "Temperature of liquid found in engine cooling system.";
CM_ BO_ 2566841088 "Engine Configuration 1";
CM_ SG_ 2566841088 SupportTSC1CtrlPurposeGroup4 "This parameter indicates which TSC1 control purposes are supported in group 4 of 4.";
CM_ SG_ 2566841088 SupportTSC1CtrlPurposeGroup3 "This parameter indicates which TSC1 control purposes are supported in group 3 of 4.";
CM_ SG_ 2566841088 SupportTSC1CtrlPurposeGroup2 "This parameter indicates which TSC1 control purposes are supported in group 2 of 4.";
CM_ SG_ 2566841088 SupportTSC1CtrlPurposeGroup1 "This parameter indicates which TSC1 control purposes are supported in group 1 of 4.";
CM_ SG_ 2566841088 SupportVariableRateTSC1Message "This parameter indicates which TSC1 transmission rates are supported by the engine ECU in addition to the required";
CM_ SG_ 2566841088 EngDefaultTorqueLimit "Companion parameter to Transmission Torque Limit (SPN 1845).";
CM_ SG_ 2566841088 EngMomentOfInertia "Moment of inertia for the engine, including items driven full-time by the engine such as fuel, oil and cooling pumps.";
CM_ SG_ 2566841088 EngExRngRqdSpdCtrlRngUpperLimit "The maximum engine speed regardless of load that the engine will allow when operating in a speed control/limit mode,";
CM_ SG_ 2566841088 EngRqdTorqueCtrlRangeUpperLimit "The maximum engine torque that the engine will allow when operating in a torque control/limit mode.";
CM_ SG_ 2566841088 EngRqdTorqueCtrlRangeLowerLimit "The minimum engine torque that the engine will allow when operating in a torque control/limit mode.";
CM_ SG_ 2566841088 EngRqedSpeedCtrlRangeUpperLimit "The maximum engine speed regardless of load that the engine will allow when operating in a speed control/limit mode,";
CM_ SG_ 2566841088 EngRqedSpeedCtrlRangeLowerLimit "The minimum engine speed that the engine will allow when operating in a speed control/limit mode.";
CM_ SG_ 2566841088 EngMxMomentaryOverrideTimeLimit "The maximum time limit allowed to override the engine's high idle speed.";
CM_ SG_ 2566841088 EngMxMmntaryOverrideSpeedPoint7 "The maximum engine speed above high idle allowed by the engine control during a momentary high idle override.";
CM_ SG_ 2566841088 EngReferenceTorque "This parameter is the 100% reference value for all defined indicated engine torque parameters.";
CM_ SG_ 2566841088 EngSpeedAtHighIdlePoint6 "Engine speed of high idle (point 6) of the engine torque map (see PGN 65251 and supporting document).";
CM_ SG_ 2566841088 EngGainOfEndspeedGovernor "The endspeed governor is defined as a linear line with the following equations (Capital letters mean physical values, small";
CM_ SG_ 2566841088 EngPercentTorqueAtPoint5 "The torque limit that indicates the available engine torque which can be provided by the engine at point 3, 4, and 5 of the";
CM_ SG_ 2566841088 EngSpeedAtPoint5 "Engine speed of point 3, 4, and 5 of the engine torque map (see PGN 65251 and supporting document).";
CM_ SG_ 2566841088 EngPercentTorqueAtPoint4 "The torque limit that indicates the available engine torque which can be provided by the engine at point 3, 4, and 5 of the";
CM_ SG_ 2566841088 EngSpeedAtPoint4 "Engine speed of point 3, 4, and 5 of the engine torque map (see PGN 65251 and supporting document).";
CM_ SG_ 2566841088 EngPercentTorqueAtPoint3 "The torque limit that indicates the available engine torque which can be provided by the engine at point 3, 4, and 5 of the";
CM_ SG_ 2566841088 EngSpeedAtPoint3 "Engine speed of point 3, 4, and 5 of the engine torque map (see PGN 65251 and supporting document).";
CM_ SG_ 2566841088 EngPercentTorqueAtPoint2 "The torque limit that indicates the available engine torque which can be provided by the engine at point 2 of the engine";
CM_ SG_ 2566841088 EngSpeedAtPoint2 "Engine speed of point 2 of the engine torque map (see PGN 65251 and supporting document).";
CM_ SG_ 2566841088 EngPercentTorqueAtIdlePoint1 "The torque limit that indicates the available engine torque which can be provided by the engine at idle speed.";
CM_ SG_ 2566841088 EngSpeedAtIdlePoint1 "Stationary low idle speed of engine which includes influences due to engine temperature (after power up) and other";
CM_ BO_ 2566840064 "Electronic Engine Controller 3";
CM_ SG_ 2566840064 EngsDsrdOprtngSpdAsymmtryAdjstmn "This byte is utilized in transmission gear selection routines and indicates the engine's preference of lower versus higher";
CM_ SG_ 2566840064 Aftrtratment1ExhaustGasMassFlow "Measured/calculated exhaust gas mass upstream of the aftertreatment system in exhaust bank 1 and 2.";
CM_ SG_ 2566840064 Aftertreatment2IntakeDewPoint "Indicates that the temperature on the intake side of the aftertreatment system has exceeded the dew point, as estimated";
CM_ SG_ 2566840064 Aftertreatment2ExhaustDewPoint "Indicates that the temperature on the exhaust side of the aftertreatment has exceeded the dew point, as estimated by the";
CM_ SG_ 2566840064 Aftertreatment1IntakeDewPoint "Indicates that the temperature on the intake side of the aftertreatment system has exceeded the dew point, as estimated";
CM_ SG_ 2566840064 Aftertreatment1ExhaustDewPoint "Indicates that the temperature on the exhaust side of the aftertreatment has exceeded the dew point, as estimated by the";
CM_ SG_ 2566840064 EstEngPrsticLossesPercentTorque "The calculated torque that indicates the estimated amount of torque loss due to engine parasitics, such as cooling fan, air";
CM_ SG_ 2566840064 EngsDesiredOperatingSpeed "An indication by the engine of the optimal operating speed of the engine for the current existing conditions.";
CM_ SG_ 2566840064 NominalFrictionPercentTorque "The calculated torque that indicates the amount of torque required by the basic engine itself added by the loss torque of";
CM_ BO_ 2364539648 "Electronic Engine Controller 2";
CM_ SG_ 2364539648 EstPumpingPercentTorque "The calculated torque that indicates the estimated amount of torque loss due to the engine air handling system.";
CM_ SG_ 2364539648 ActlMxAvailableEngPercentTorque "This is the maximum amount of torque that the engine can immediately deliver as a percentage of the reference engine";
CM_ SG_ 2364539648 AccelPedalPos2 "The ratio of actual position of the second analog engine speed/torque request input device (such as an accelerator pedal";
CM_ SG_ 2364539648 VhclAccelerationRateLimitStatus "Status (active or not active) of the system used to limit maximum forward vehicle acceleration.";
CM_ SG_ 2364539648 EngPercentLoadAtCurrentSpeed "The ratio of actual engine percent torque (indicated) to maximum indicated torque available at the current engine speed,";
CM_ SG_ 2364539648 GearShiftIndication "Switch signal which indicates the state of the accelerator pedal 2 low idle switch.";
CM_ SG_ 2364539648 RoadSpeedLimitStatus "Status (active or not active) of the system used to limit maximum vehicle velocity.";
CM_ SG_ 2364539648 AccelPedalKickdownSwitch "Switch signal which indicates whether the accelerator pedal kickdown switch is opened or closed.";
CM_ SG_ 2364539648 AccelPedal1LowIdleSwitch "Switch signal which indicates the state of the accelerator pedal 1 low idle switch.";
CM_ SG_ 2364539648 RemoteAccelPedalPos "The ratio of actual position of the remote analog engine speed/torque request input device (such as an accelerator pedal";
CM_ SG_ 2364539648 AccelPedalPos1 "The ratio of actual position of the analog engine speed/torque request input device (such as an accelerator pedal or";
CM_ BO_ 2364539904 "Electronic Engine Controller 1";
CM_ SG_ 2364539904 SrcAddrssOfCtrllngDvcFrEngCntrl "The source address of the SAE J1939 device currently controlling the engine.";
CM_ SG_ 2364539904 ActlEngPrcntTrqueHighResolution "This parameter displays an additional torque in percent of the reference engine torque.";
CM_ SG_ 2364539904 EngDemandPercentTorque "The requested torque output of the engine by all dynamic internal inputs, including smoke control, noise control and low";
CM_ SG_ 2364539904 EngStarterMode "There are several phases in a starting action and different reasons why a start cannot take place.";
CM_ SG_ 2364539904 EngSpeed "Actual engine speed which is calculated over a minimum crankshaft angle of 720 degrees divided by the number of cylinders.";
CM_ SG_ 2364539904 ActualEngPercentTorque "The calculated output torque of the engine.";
CM_ SG_ 2364539904 DriversDemandEngPercentTorque "The requested torque output of the engine by the driver.";
CM_ SG_ 2364539904 EngTorqueMode "State signal which indicates which engine torque mode is currently generating, limiting, or controlling the torque.";
CM_ BO_ 2566844672 "Cruise Control/Vehicle Speed";
CM_ SG_ 2566844672 PTOGovernorState_CCVS_ECM "This parameter is used to indicate the current state or mode of operation by the power takeoff (PTO) governor.";
CM_ SG_ 2566844672 EngShutdownOverrideSwitch "Switch signal which indicates the position of the engine shutdown override switch.";
CM_ SG_ 2566844672 EngTestModeSwitch "Switch signal which indicates the position of the engine test mode switch.";
CM_ SG_ 2566844672 EngIdleDecrementSwitch "Switch signal which indicates the position of the idle decrement switch.";
CM_ SG_ 2566844672 EngIdleIncrementSwitch "Switch signal which indicates the position of the idle increment switch.";
CM_ SG_ 2566844672 CruiseCtrlStates "This parameter is used to indicate the current state, or mode, of operation by the cruise control device.";
CM_ SG_ 2566844672 CruiseCtrlSetSpeed "Value of set (chosen) velocity of velocity control system.";
CM_ SG_ 2566844672 CruiseCtrlAccelerateSwitch_CCVSE "Switch signal of the cruise control activator which indicates that the activator is in the position “accelerate.";
CM_ SG_ 2566844672 CruiseCtrlResumeSwitch_CCVS_ECM "Switch signal of the cruise control activator which indicates that the activator is in the position “resume.";
CM_ SG_ 2566844672 CruiseCtrlCoastSwitch_CCVS_ECM "Switch signal of the cruise control activator which indicates that the activator is in the position “coast (decelerate).";
CM_ SG_ 2566844672 CruiseCtrlSetSwitch "Switch signal of the cruise control activator which indicates that the activator is in the position “set.";
CM_ SG_ 2566844672 ClutchSwitch_CCVS_ECM "Switch signal which indicates that the clutch pedal is being pressed.";
CM_ SG_ 2566844672 BrakeSwitch_CCVS_ECM "Switch signal which indicates that the driver operated brake foot pedal is being pressed.";
CM_ SG_ 2566844672 CruiseCtrlEnableSwitch "Switch signal which indicates that it is possible to manage the cruise control function.";
CM_ SG_ 2566844672 CruiseCtrlActive "Cruise control is switched on.";
CM_ SG_ 2566844672 WheelBasedVehicleSpeed_CCVS_ECM "Speed of the vehicle as calculated from wheel or tailshaft speed.";
CM_ SG_ 2566844672 ParkingBrakeSwitch_CCVS_ECM "Switch signal which indicates when the parking brake is set.";
CM_ BO_ 2566845696 "Ambient Conditions";
CM_ SG_ 2566845696 RoadSurfaceTemp "Indicated temperature of road surface over which vehicle is operating.";
CM_ SG_ 2566845696 AmbientAirTemp "Temperature of air surrounding vehicle.";
CM_ SG_ 2566845696 CabInteriorTemp "Temperature of air inside the part of the vehicle that encloses the driver and vehicle operating controls.";
CM_ SG_ 2566845696 EngAirIntakeTemp "Temperature of air entering vehicle air induction system.";
CM_ SG_ 2566845696 BarometricPress "Absolute air pressure of the atmosphere.";
CM_ BO_ 2566801923 "Electronic Transmission Controller 7";
CM_ SG_ 2566801923 TransEngCrankEnable "State signal from the transmission indicating if the transmission’s status is such that engine cranking is allowed (i.";
CM_ BO_ 2565406224 "Acknowledgment Message";
CM_ SG_ 2565406224 ParameterGroupNumber "PGN which is requested by Request2 message";
CM_ SG_ 2565406224 GroupFunctionValue "Group Function of PGN being acknowledged. This field identifies for a device the specific group function of a PGN being acknowledged or declined.  This field is not used if the PGN being acknowledged or declined is not a group function PGN.";
CM_ BO_ 2566810606 "Driver's Identification";
CM_ BO_ 2365484270 "Tachograph";
CM_ SG_ 2365484270 VehicleOverspeed "Indicates whether the vehicle is exceeding the legal speed limit set in the tachograph.";
CM_ SG_ 2365484270 VehicleMotion "Indicates whether motion of the vehicle is detected or not.";
CM_ SG_ 2365484270 TachographVehicleSpeed "Speed of the vehicle registered by the tachograph.";
CM_ SG_ 2365484270 TachographOutputShaftSpeed "Calculated speed of the transmission output shaft.";
CM_ SG_ 2365484270 DirectionIndicator "Indicates the direction of the vehicle.";
CM_ SG_ 2365484270 TachographPerformance "Indicates the tachograph performance; including electronic or mechanical analysis, instrument analysis, speed sensor";
CM_ SG_ 2365484270 HandlingInformation "Indicates that handling information is present.";
CM_ SG_ 2365484270 SystemEvent "Indicates that a tachograph event has occurred.";
CM_ SG_ 2365484270 DriverCardDriver2 "Indicates the presence of a driver card";
CM_ SG_ 2365484270 Driver2TimeRelatedStates "Indicates if the driver approaches or exceeds working time limits (or other limits).";
CM_ SG_ 2365484270 DriverCardDriver1 "Indicates the presence of a driver card";
CM_ SG_ 2365484270 Driver1TimeRelatedStates "Indicates if the driver approaches or exceeds working time limits (or other limits).";
CM_ SG_ 2365484270 Driver2WorkingState "State of work of the driver.";
CM_ SG_ 2365484270 Driver1WorkingState "State of work of the driver.";
CM_ BO_ 2566832366 "Service Information";
CM_ SG_ 2566832366 ServiceComponentIdentificationB "Identification of component needing service.";
CM_ SG_ 2566832366 ServiceComponentIdentificationA "Identification of component needing service.";
CM_ SG_ 2566832366 SrvceDelay_OperationalTimeBased "The time in vehicle operational time until the next vehicle service inspection is required.";
CM_ SG_ 2566832366 ServiceDelay_CalendarTimeBased "The time in weeks until the next vehicle service inspection is required.";
CM_ SG_ 2566832366 ServiceDistance "The distance which can be traveled by the vehicle before the next service inspection is required.";
CM_ SG_ 2566832366 ServiceComponentIdentification "Identification of component needing service.";
CM_ BO_ 2566832622 "High Resolution Vehicle Distance";
CM_ SG_ 2566832622 HighResolutionTripDistance "Distance traveled during all or part of a journey.";
CM_ SG_ 2566832622 HghRslutionTotalVehicleDistance "Accumulated distance traveled by the vehicle during its operation.";
CM_ BO_ 2566843630 "Vehicle Identification";
CM_ SG_ 2566843630 VehicleIdentificationNumber "Vehicle Identification Number";
CM_ BO_ 2566842094 "Time/Date";
CM_ SG_ 2566842094 LocalHourOffset "The hour component of the offset between the UTC (Universal Time Coordinate) time and date and a local time zone time";
CM_ SG_ 2566842094 LocalMinuteOffset "The minute component of the offset between the UTC time and date and a local time zone time and date.";
CM_ SG_ 2566842094 Year "The year component of the current calendar date.";
CM_ SG_ 2566842094 Day "The day component of the current calendar date.";
CM_ SG_ 2566842094 Month "The month component of the current calendar date.";
CM_ SG_ 2566842094 Hours "The hour component of the current time of day.";
CM_ SG_ 2566842094 Minutes "The minutes component of the current time of day.";
CM_ SG_ 2566842094 Seconds "The seconds component of the current time of day.";
CM_ BO_ 2631855639 "Reset";
CM_ SG_ 2631855639 TripGroup2Proprietary "Command signal used to reset proprietary parameters associated with a trip but not defined within this document.";
CM_ SG_ 2631855639 TripGroup1 "Command signal used to reset the PGNs and parameters as defined in Table SPN988_A.";
CM_ BO_ 2566847511 "Dash Display";
CM_ SG_ 2566847511 FuelLevel1 "Ratio of volume of fuel to the total volume of fuel storage container.";
CM_ SG_ 2566847511 CargoAmbientTemp "Temperature of air inside vehicle container used to accommodate cargo.";
CM_ BO_ 2566838551 "Auxiliary Input/Output Status 1";
CM_ SG_ 2566838551 ACCUsageDemand_AUXIO_R_IC "This parameter indicates the drivers demand to activate or deactivate ACC keeping distance control.";
CM_ SG_ 2566838551 AuxI_O03_RetarderLeverPosition "Identifies the current status of auxiliary input/output functions that are configured uniquely per application.";
CM_ SG_ 2566838551 AuxI_O02_BlendingSwitchPos "Identifies the current status of auxiliary input/output functions that are configured uniquely per application.";
CM_ SG_ 2566838551 PCCLevelSelection "This parameter is used to identify the specific requests being sent to the component.";
CM_ BO_ 2566827543 "Air Supply Pressure";
CM_ SG_ 2566827543 ServiceBrakeCircuit2AirPress "The pneumatic pressure in the secondary service brake circuit or reservoir, supplying the front axle.";
CM_ SG_ 2566827543 ServiceBrakeCircuit1AirPress "The pneumatic pressure in the primary service brake circuit or reservoir, supplying the rear axle.";
CM_ SG_ 2566827543 AuxEquipmentSupplyPress "The pneumatic pressure in the auxiliary circuit.";
CM_ SG_ 2566827543 ParkingAnd_OrTrailerAirPress "The pneumatic pressure in the circuit or reservoir for the parking brake and/or the trailer supply.";
CM_ SG_ 2566827543 PneumaticSupplyPress "The pneumatic pressure in the main reservoir, sometimes referred to as the wet tank.";
CM_ BO_ 2565537534 "Request";
CM_ SG_ 2565537534 ParameterGroupNumber "PGN which is requested by Request2 message";
CM_ BO_ 2631729175 "Anti-theft Request";
CM_ SG_ 2631729175 AntthftEncryptonIndicatorStates "This parameter is used to indicate if a random number seed is being requested, or if an encrypted password is being";
CM_ SG_ 2631729175 AntitheftDesiredExitModeStates "This parameter is used to specify the desired triggers that are to be used by the component in deciding when to transition";
CM_ SG_ 2631729175 AntitheftCmdStates "This parameter is used to identify the specific requests being sent to the component.";
CM_ SG_ 2631729175 AntitheftPasswordRepresentation "This parameter is the seven byte numeric code (i.";
CM_ BO_ 2566806504 "Forward Lane Image";
CM_ SG_ 2566806504 Line_type_left_side "Indicates whether lane departure indication is active.";
CM_ SG_ 2566806504 Line_type_right_side "Indicates whether lane departure indication is active.";
CM_ SG_ 2566806504 LnDprtureIndicationEnableStatus "Indicates whether lane departure indication is active.";
CM_ SG_ 2566806504 LaneTrackingStatusLeftSide "Indicates whether the left side is tracking lane.";
CM_ SG_ 2566806504 LaneTrackingStatusRightSide "Indicates whether right side is tracking lane.";
CM_ BO_ 2431649768 "Forward Lane Image urgent msg";
CM_ SG_ 2431649768 LaneDepartureRightSide "Indicates that the middle of vehicle departs the lane on the right side.";
CM_ SG_ 2431649768 LaneDepartureLeftSide "Indicates that the middle of vehicle departs the lane on the left side.";
CM_ SG_ 2431649768 LaneDepartureImminentLeftSide "Indicates departure imminent on left side of lane.";
CM_ SG_ 2431649768 LaneDepartureImminentRightSide "Indicates departure imminent on right side of lane.";
CM_ BO_ 2348810282 "Torque/Speed Control 1";
CM_ SG_ 2348810282 MessageCounter "The message counter is used to detect situations where the transmitting ECU malfunction repeats the same frame all the time.";
CM_ SG_ 2348810282 ControlPurpose "State signal which indicates which control mode the sending device is using to generate the TSC1 command.";
CM_ SG_ 2348810282 TransmissionRate "This parameter indicates the transmission rate at which the sending device will transmit the TSC1 message.";
CM_ SG_ 2348810282 EngRqedTorque_TorqueLimit "Parameter provided to the engine or retarder in the torque/speed control message for controlling or limiting the output torque.";
CM_ SG_ 2348810282 EngRqedSpeed_SpeedLimit "Parameter provided to the engine from external sources in the torque/speed control message.";
CM_ SG_ 2348810282 EngRqedSpeedCtrlConditions "This mode tells the engine control system the governor characteristics that are desired during speed control.";
CM_ SG_ 2348810282 MessageChecksum "The checksum is used to verify the signal path from the transmitting device to the receiving device.";
CM_ SG_ 2348810282 EngineRequestedTorqueHiRes "This parameter displays an additional torque in percent of the reference engine torque.";
CM_ BO_ 2349075242 "External Brake Request";
CM_ SG_ 2349075242 XBRMessageChecksum "The XBR message checksum is used to verify the signal path from the demanding device to the brake controller on";
CM_ SG_ 2349075242 XBRMessageCounter "The XBR message counter is to verify the signal path from the demanding device to the brake controller on electronic";
CM_ SG_ 2349075242 XBRCtrlMode "The XBR Control Mode is used as an input to the brake system and defines how the external acceleration demand has to";
CM_ SG_ 2349075242 XBRPriority "The XBR Priority is used as an input to the brake system to manage the priority of overlapping external and internal requests.";
CM_ SG_ 2349075242 XBREBIMode "The XBR EBI (Endurance Brake Integration) Mode is used as an input for the brake system to prescribe the use of";
CM_ SG_ 2349075242 ExtlAccelerationDemand "Parameter provided to the brake system from external sources.";
CM_ SG_ 2349075242 XBRUrgency "The idea of the urgency value is to adjust the endurance brake integration behavior in the EBS system according to the";
CM_ BO_ 2365443122 "Operators External Light Controls Message";
CM_ SG_ 2365443122 OperatorsDesiredBacklight "A 8 bit parameter to indicate the level of back lighting the operator has selected for displays.";
CM_ SG_ 2365443122 HighLowBeamSwitch "A 2 bit parameter to indicate the selected position of the operator's high/low beam select switch.";
CM_ SG_ 2365443122 HazardLightSwitch "A 2 bit parameter to indicate the selected position of the operator's hazard light switch.";
CM_ SG_ 2365443122 TurnSignalSwitch_OEL_BCM "A 4 bit parameter to indicate the selected position of the operator's turn signal switch.";
CM_ SG_ 2365443122 MainLightSwitch "A 4 bit parameter to indicate the selected position of the operator's main light switch.";
CM_ SG_ 2365443122 WorkLightSwitch "A 4 bit parameter to indicate the selected position of the operator's work light switch.";
CM_ BO_ 2561271841 "Forward Lane Image Command";
CM_ SG_ 2561271841 LaneDepartureWarningEnableCmd "Command to enable/disable Lane Departure Indication";
CM_ BO_ 2565867041 "Electronic Axle Controller 1";
CM_ SG_ 2565867041 RearAxleGroupEngagementStatus "Rear axle group engagement status";
CM_ SG_ 2565867041 FrontAxleGroupEngagementStatus "Front axle group engagement status";
CM_ SG_ 2565867041 DiffLockStateCentralRear "State used which indicates the condition of the central rear differential lock.";
CM_ SG_ 2565867041 DiffLockStateCentralFront "State used which indicates the condition of the central front differential lock.";
CM_ SG_ 2565867041 Interlock "State used which indicates the condition of the central differential lock.";
CM_ SG_ 2565867041 DiffLockStateRearAxle2 "State used which indicates the condition of the rear axle 2 differential lock.";
CM_ SG_ 2565867041 DiffLockStateRearAxle1 "State used which indicates the condition of the rear axle 1 differential lock.";
CM_ SG_ 2565867041 DiffLock1 "State used which indicates the condition of the front axle 2 differential lock.";
CM_ SG_ 2565867041 DiffLock2 "State used which indicates the condition of the front axle 1 differential lock.";
CM_ SG_ 2565867041 Location "To identify to which of several similar devices (such as tires or fuel tanks) the information applies.";
CM_ SG_ 2564816929 CabIntTempComStatus "Parameter used to command a certain cab interior temperature.";
BA_DEF_ SG_  "SigType" ENUM  "Default","Range","RangeSigned","ASCII","Discrete","Control","ReferencePGN","DTC","StringDelimiter","StringLength","StringLengthControl";
BA_DEF_ SG_  "GenSigStartValue" INT 0 10000;
BA_DEF_ SG_  "GenSigSendType" ENUM  "Cyclic","OnWrite","reserved","OnChange","reserved","reserved","reserved","NoSigSendType";
BA_DEF_ SG_  "GenSigILSupport" ENUM  "Yes","No";
BA_DEF_ SG_  "GenSigEVName" STRING ;
BA_DEF_ SG_  "SPN" INT 0 524287;
BA_DEF_ BO_  "GenMsgStartDelayTime" INT 0 100000;
BA_DEF_ BO_  "GenMsgILSupport" ENUM  "Yes","No";
BA_DEF_ BO_  "GenMsgDelayTime" INT 0 1000;
BA_DEF_ BO_  "GenMsgRequestable" INT 0 1;
BA_DEF_ BO_  "GenMsgSendType" ENUM  "cyclic","Spontaneus","cyclicIfActive","reserved","reserved","reserved","reserved","reserved","noMsgSendType","OnRequest";
BA_DEF_ BO_  "VFrameFormat" ENUM  "StandardCAN","ExtendedCAN","reserved","J1939PG";
BA_DEF_ BO_  "GenMsgCycleTime" INT 0 3600000;
BA_DEF_ SG_  "SystemSignalLongSymbol" STRING ;
BA_DEF_DEF_  "SigType" "Default";
BA_DEF_DEF_  "GenSigStartValue" 0;
BA_DEF_DEF_  "GenSigSendType" "NoSigSendType";
BA_DEF_DEF_  "GenSigILSupport" "Yes";
BA_DEF_DEF_  "GenSigEVName" "Env@Nodename_@Signame";
BA_DEF_DEF_  "SPN" 0;
BA_DEF_DEF_  "GenMsgStartDelayTime" 0;
BA_DEF_DEF_  "GenMsgILSupport" "Yes";
BA_DEF_DEF_  "GenMsgDelayTime" 0;
BA_DEF_DEF_  "GenMsgRequestable" 1;
BA_DEF_DEF_  "GenMsgSendType" "noMsgSendType";
BA_DEF_DEF_  "VFrameFormat" "J1939PG";
BA_DEF_DEF_  "GenMsgCycleTime" 0;
BA_DEF_DEF_  "SystemSignalLongSymbol" "";
BA_ "GenMsgSendType" BO_ 2566843648 2;
BA_ "GenMsgCycleTime" BO_ 2566843648 50;
BA_ "GenMsgSendType" BO_ 2566708224 0;
BA_ "GenMsgCycleTime" BO_ 2566708224 100;
BA_ "GenMsgCycleTime" BO_ 2365512010 500;
BA_ "GenMsgSendType" BO_ 2365512010 0;
BA_ "GenMsgCycleTime" BO_ 2565475095 1000;
BA_ "GenMsgCycleTime" BO_ 2565472279 1000;
BA_ "GenMsgSendType" BO_ 2349465642 0;
BA_ "GenMsgCycleTime" BO_ 2349465642 100;
BA_ "GenMsgSendType" BO_ 2432593706 0;
BA_ "GenMsgCycleTime" BO_ 2432593706 100;
BA_ "GenMsgCycleTime" BO_ 2566799393 100;
BA_ "GenMsgSendType" BO_ 2566799393 0;
BA_ "GenMsgCycleTime" BO_ 2566838561 100;
BA_ "GenMsgSendType" BO_ 2566838561 0;
BA_ "GenMsgSendType" BO_ 2566827774 0;
BA_ "GenMsgCycleTime" BO_ 2566827774 1000;
BA_ "GenMsgSendType" BO_ 2565919516 0;
BA_ "GenMsgCycleTime" BO_ 2565919516 100;
BA_ "GenMsgCycleTime" BO_ 2566848540 100;
BA_ "GenMsgSendType" BO_ 2566848540 0;
BA_ "GenMsgCycleTime" BO_ 2631728651 5000;
BA_ "GenMsgCycleTime" BO_ 2631794218 5000;
BA_ "GenMsgCycleTime" BO_ 2566775040 1000;
BA_ "GenMsgSendType" BO_ 2566775040 0;
BA_ "GenMsgCycleTime" BO_ 2566811651 100;
BA_ "GenMsgSendType" BO_ 2566811651 2;
BA_ "GenMsgCycleTime" BO_ 2565668619 1000;
BA_ "GenMsgSendType" BO_ 2565668619 1;
BA_ "GenMsgCycleTime" BO_ 2565603083 50;
BA_ "GenMsgSendType" BO_ 2565603083 1;
BA_ "GenMsgCycleTime" BO_ 2566870526 100;
BA_ "GenMsgSendType" BO_ 2566870526 0;
BA_ "GenMsgCycleTime" BO_ 2563829271 100;
BA_ "GenMsgSendType" BO_ 2563829271 0;
BA_ "GenMsgCycleTime" BO_ 2566834920 1000;
BA_ "GenMsgSendType" BO_ 2566834920 0;
BA_ "GenMsgSendType" BO_ 2566834730 0;
BA_ "GenMsgCycleTime" BO_ 2566834730 1000;
BA_ "GenMsgSendType" BO_ 2566759427 0;
BA_ "GenMsgCycleTime" BO_ 2566759427 100;
BA_ "GenMsgSendType" BO_ 2348875776 0;
BA_ "GenMsgCycleTime" BO_ 2348875776 50;
BA_ "GenMsgSendType" BO_ 2566722593 0;
BA_ "GenMsgCycleTime" BO_ 2566722593 100;
BA_ "GenMsgSendType" BO_ 2566722849 0;
BA_ "GenMsgCycleTime" BO_ 2566722849 100;
BA_ "GenMsgSendType" BO_ 2566879486 0;
BA_ "GenMsgCycleTime" BO_ 2566879486 100;
BA_ "GenMsgSendType" BO_ 2566851105 0;
BA_ "GenMsgCycleTime" BO_ 2566851105 100;
BA_ "GenMsgSendType" BO_ 2566843134 0;
BA_ "GenMsgCycleTime" BO_ 2566843134 100;
BA_ "GenMsgSendType" BO_ 2365479678 0;
BA_ "GenMsgCycleTime" BO_ 2365479678 100;
BA_ "GenMsgSendType" BO_ 2566759457 0;
BA_ "GenMsgCycleTime" BO_ 2566759457 500;
BA_ "GenMsgCycleTime" BO_ 2566756875 1000;
BA_ "GenMsgSendType" BO_ 2566756875 2;
BA_ "GenMsgSendType" BO_ 2566910462 0;
BA_ "GenMsgCycleTime" BO_ 2566910462 30;
BA_ "GenMsgCycleTime" BO_ 2566905342 8;
BA_ "GenMsgSendType" BO_ 2566905342 0;
BA_ "GenMsgCycleTime" BO_ 2566905086 10;
BA_ "GenMsgSendType" BO_ 2566905086 0;
BA_ "GenMsgCycleTime" BO_ 2566910206 30;
BA_ "GenMsgSendType" BO_ 2566910206 0;
BA_ "GenMsgCycleTime" BO_ 2566841344 1000;
BA_ "GenMsgSendType" BO_ 2566841344 0;
BA_ "GenMsgCycleTime" BO_ 2566848256 100;
BA_ "GenMsgSendType" BO_ 2566848256 0;
BA_ "GenMsgCycleTime" BO_ 2566719744 1000;
BA_ "GenMsgSendType" BO_ 2566719744 0;
BA_ "GenMsgCycleTime" BO_ 2566844928 100;
BA_ "GenMsgSendType" BO_ 2566844928 0;
BA_ "GenMsgCycleTime" BO_ 2566831360 1000;
BA_ "GenMsgSendType" BO_ 2566831360 0;
BA_ "GenMsgSendType" BO_ 2566843904 0;
BA_ "GenMsgCycleTime" BO_ 2566843904 1000;
BA_ "GenMsgSendType" BO_ 2566841088 0;
BA_ "GenMsgCycleTime" BO_ 2566841088 5000;
BA_ "GenMsgSendType" BO_ 2566840064 0;
BA_ "GenMsgCycleTime" BO_ 2566840064 250;
BA_ "GenMsgSendType" BO_ 2364539648 0;
BA_ "GenMsgCycleTime" BO_ 2364539648 50;
BA_ "GenMsgSendType" BO_ 2364539904 0;
BA_ "GenMsgCycleTime" BO_ 2364539904 10;
BA_ "GenMsgSendType" BO_ 2566844672 0;
BA_ "GenMsgCycleTime" BO_ 2566844672 100;
BA_ "GenMsgSendType" BO_ 2566845696 0;
BA_ "GenMsgCycleTime" BO_ 2566845696 1000;
BA_ "GenMsgCycleTime" BO_ 2566801923 100;
BA_ "GenMsgSendType" BO_ 2566801923 0;
BA_ "GenMsgCycleTime" BO_ 2565406224 200;
BA_ "GenMsgCycleTime" BO_ 2566870288 100;
BA_ "GenMsgSendType" BO_ 2566870288 0;
BA_ "GenMsgSendType" BO_ 2566810606 9;
BA_ "GenMsgCycleTime" BO_ 2566810606 100;
BA_ "GenMsgCycleTime" BO_ 2365484270 50;
BA_ "GenMsgSendType" BO_ 2365484270 0;
BA_ "GenMsgSendType" BO_ 2566832366 9;
BA_ "GenMsgCycleTime" BO_ 2566832622 1000;
BA_ "GenMsgSendType" BO_ 2566832622 0;
BA_ "GenMsgSendType" BO_ 2566843630 9;
BA_ "GenMsgCycleTime" BO_ 2566842094 1000;
BA_ "GenMsgSendType" BO_ 2566842094 0;
BA_ "GenMsgCycleTime" BO_ 2631855639 1000;
BA_ "GenMsgSendType" BO_ 2631855639 0;
BA_ "GenMsgCycleTime" BO_ 2566847511 500;
BA_ "GenMsgSendType" BO_ 2566847511 0;
BA_ "GenMsgCycleTime" BO_ 2566838551 100;
BA_ "GenMsgSendType" BO_ 2566838551 0;
BA_ "GenMsgCycleTime" BO_ 2566827543 1000;
BA_ "GenMsgSendType" BO_ 2566827543 0;
BA_ "GenMsgCycleTime" BO_ 2565537534 1000;
BA_ "GenMsgCycleTime" BO_ 2566806504 100;
BA_ "GenMsgSendType" BO_ 2566806504 0;
BA_ "GenMsgCycleTime" BO_ 2431649768 50;
BA_ "GenMsgSendType" BO_ 2431649768 0;
BA_ "GenMsgSendType" BO_ 2348810282 2;
BA_ "GenMsgCycleTime" BO_ 2348810282 20;
BA_ "GenMsgSendType" BO_ 2364550954 0;
BA_ "GenMsgCycleTime" BO_ 2364550954 50;
BA_ "GenMsgSendType" BO_ 2349075242 2;
BA_ "GenMsgCycleTime" BO_ 2349075242 20;
BA_ "GenMsgSendType" BO_ 2365443122 0;
BA_ "GenMsgCycleTime" BO_ 2365443122 20;
BA_ "GenMsgSendType" BO_ 2561271841 0;
BA_ "GenMsgCycleTime" BO_ 2561271841 200;
BA_ "GenMsgSendType" BO_ 2565867041 0;
BA_ "GenMsgCycleTime" BO_ 2565867041 500;
BA_ "GenMsgSendType" BO_ 2564816929 0;
BA_ "GenMsgCycleTime" BO_ 2564816929 500;
BA_ "SigType" SG_ 2566708224 CCDriverCancellationStatus 4;
BA_ "SigType" SG_ 2566708224 CruiseCtrlSpeed 1;
BA_ "SPN" SG_ 2566708224 CruiseCtrlSpeed 86;
BA_ "SigType" SG_ 2566708224 CruiseCtrlSetSpeed_HighRes 1;
BA_ "SPN" SG_ 2566708224 CruiseCtrlSetSpeed_HighRes 86;
BA_ "SigType" SG_ 2566708224 SAControlDeviceforPauseCC 4;
BA_ "SigType" SG_ 2566708224 SAControlDeviceforDisableCC 4;
BA_ "SPN" SG_ 2365512010 Audio_Mute 84;
BA_ "SigType" SG_ 2365512010 Audio_Mute 1;
BA_ "SPN" SG_ 2565475095 ParameterGroupNumber 2574;
BA_ "SigType" SG_ 2565475095 ParameterGroupNumber 6;
BA_ "SPN" SG_ 2565472279 ParameterGroupNumber 2574;
BA_ "SigType" SG_ 2565472279 ParameterGroupNumber 6;
BA_ "SPN" SG_ 2432593706 ForwardCollisionWarning 5022;
BA_ "SigType" SG_ 2432593706 ForwardCollisionWarning 4;
BA_ "SPN" SG_ 2432593706 ACCDistanceAlertSignal 1796;
BA_ "SigType" SG_ 2432593706 ACCDistanceAlertSignal 4;
BA_ "SPN" SG_ 2432593706 ACCSystemShutoffWarning 1797;
BA_ "SigType" SG_ 2432593706 ACCSystemShutoffWarning 4;
BA_ "SPN" SG_ 2432593706 ACCTargetDetected 1798;
BA_ "SigType" SG_ 2432593706 ACCTargetDetected 4;
BA_ "SPN" SG_ 2432593706 RoadCurvature 1591;
BA_ "SigType" SG_ 2432593706 RoadCurvature 1;
BA_ "SPN" SG_ 2432593706 AdptveCruiseCtrlSetDistanceMode 1589;
BA_ "SPN" SG_ 2432593706 AdaptiveCruiseCtrlMode 1590;
BA_ "SPN" SG_ 2432593706 AdaptiveCruiseCtrlSetSpeed 1588;
BA_ "SigType" SG_ 2432593706 AdaptiveCruiseCtrlSetSpeed 1;
BA_ "SPN" SG_ 2432593706 DistanceToForwardVehicle 1587;
BA_ "SigType" SG_ 2432593706 DistanceToForwardVehicle 1;
BA_ "SPN" SG_ 2432593706 SpeedOfForwardVehicle 1586;
BA_ "SigType" SG_ 2432593706 SpeedOfForwardVehicle 1;
BA_ "GenSigStartValue" SG_ 2566838561 CabInteriorTempCommand_BCM 80;
BA_ "SPN" SG_ 2566838561 RqedACCDistanceMode 1799;
BA_ "SPN" SG_ 2566838561 AuxI_O08_GearboxNeutralPos_AUX1 708;
BA_ "SigType" SG_ 2566838561 AuxI_O08_GearboxNeutralPos_AUX1 4;
BA_ "SPN" SG_ 2566838561 AuxI_O07_TrailerABSFulOper_AUX1 707;
BA_ "SigType" SG_ 2566838561 AuxI_O07_TrailerABSFulOper_AUX1 4;
BA_ "SPN" SG_ 2566838561 AuxI_O06_TrailerABSDetected_AUX1 706;
BA_ "SigType" SG_ 2566838561 AuxI_O06_TrailerABSDetected_AUX1 4;
BA_ "SPN" SG_ 2566838561 AuxI_O05_TrailerConnected_AUX1 705;
BA_ "SigType" SG_ 2566838561 AuxI_O05_TrailerConnected_AUX1 4;
BA_ "GenSigStartValue" SG_ 2566838561 AuxI_O05_TrailerConnected_AUX1 3;
BA_ "GenSigSendType" SG_ 2564432369 TesterReqBCM 3;
BA_ "GenSigEVName" SG_ 2564432369 TesterReqBCM "TesterReqBCM";
BA_ "SPN" SG_ 2566827774 ServiceBrakeCircuit2AirPress 1088;
BA_ "SigType" SG_ 2566827774 ServiceBrakeCircuit2AirPress 1;
BA_ "SPN" SG_ 2566827774 ServiceBrakeCircuit1AirPress 1087;
BA_ "SigType" SG_ 2566827774 ServiceBrakeCircuit1AirPress 1;
BA_ "SPN" SG_ 2566827774 AirCompressorStatus 1351;
BA_ "SigType" SG_ 2566827774 AirCompressorStatus 4;
BA_ "GenSigStartValue" SG_ 2566827774 AirCompressorStatus 255;
BA_ "SPN" SG_ 2566827774 AirSuspensionSupplyPress 1090;
BA_ "SigType" SG_ 2566827774 AirSuspensionSupplyPress 1;
BA_ "GenSigStartValue" SG_ 2566827774 AirSuspensionSupplyPress 31.875;
BA_ "SPN" SG_ 2566827774 AuxEquipmentSupplyPress 1089;
BA_ "SigType" SG_ 2566827774 AuxEquipmentSupplyPress 1;
BA_ "GenSigStartValue" SG_ 2566827774 AuxEquipmentSupplyPress 31.875;
BA_ "SPN" SG_ 2566827774 ParkingAnd_OrTrailerAirPress 1086;
BA_ "SigType" SG_ 2566827774 ParkingAnd_OrTrailerAirPress 1;
BA_ "GenSigStartValue" SG_ 2566827774 ParkingAnd_OrTrailerAirPress 31.875;
BA_ "SPN" SG_ 2566827774 PneumaticSupplyPress 46;
BA_ "SigType" SG_ 2566827774 PneumaticSupplyPress 1;
BA_ "GenSigStartValue" SG_ 2566827774 PneumaticSupplyPress 31.875;
BA_ "SPN" SG_ 2565603114 SequenceNumber 2572;
BA_ "SPN" SG_ 2565668394 TotalNumberOfPacketsEoMA 2558;
BA_ "SPN" SG_ 2565668394 TotalMessageSizeEoMA 2557;
BA_ "SPN" SG_ 2565668394 TotalMessageSizeBAM 2557;
BA_ "SPN" SG_ 2565668394 TotalNumberOfPacketsBAM 2558;
BA_ "SPN" SG_ 2565668394 ConnectionAbortReason 2570;
BA_ "SPN" SG_ 2565668394 NextPacketNumberToBeSent 2562;
BA_ "SPN" SG_ 2565668394 NumberOfPacketsThatCanBeSent 2561;
BA_ "SPN" SG_ 2565668394 PGNumber 2560;
BA_ "SigType" SG_ 2565668394 PGNumber 6;
BA_ "SPN" SG_ 2565668394 MaximumNumberOfPackets 2559;
BA_ "SPN" SG_ 2565668394 TotalNumberOfPackets 2558;
BA_ "SPN" SG_ 2565668394 TotalMessageSize 2557;
BA_ "SPN" SG_ 2565668394 ControlByte 2556;
BA_ "SPN" SG_ 2565603304 SequenceNumber 2572;
BA_ "SPN" SG_ 2565668840 TotalNumberOfPacketsEoMA 2558;
BA_ "SPN" SG_ 2565668840 TotalMessageSizeEoMA 2557;
BA_ "SPN" SG_ 2565668840 TotalMessageSizeBAM 2557;
BA_ "SPN" SG_ 2565668840 TotalNumberOfPacketsBAM 2558;
BA_ "SPN" SG_ 2565668840 ConnectionAbortReason 2570;
BA_ "SPN" SG_ 2565668840 NextPacketNumberToBeSent 2562;
BA_ "SPN" SG_ 2565668840 NumberOfPacketsThatCanBeSent 2561;
BA_ "SPN" SG_ 2565668840 PGNumber 2560;
BA_ "SigType" SG_ 2565668840 PGNumber 6;
BA_ "SPN" SG_ 2565668840 MaximumNumberOfPackets 2559;
BA_ "SPN" SG_ 2565668840 TotalNumberOfPackets 2558;
BA_ "SPN" SG_ 2565668840 TotalMessageSize 2557;
BA_ "SPN" SG_ 2565668840 ControlByte 2556;
BA_ "SPN" SG_ 2565919516 PreCru_Ctrl_State 86;
BA_ "SigType" SG_ 2565919516 PreCru_Ctrl_State 1;
BA_ "GenSigStartValue" SG_ 2565919516 PreCru_Ctrl_SetSpeedOffset 32000;
BA_ "SPN" SG_ 2565919516 PreCru_Ctrl_SetSpeedOffset 86;
BA_ "SigType" SG_ 2565919516 PreCru_Ctrl_SetSpeedOffset 1;
BA_ "GenSigStartValue" SG_ 2565919516 PreCru_Ctrl_PresentGrade 128;
BA_ "SPN" SG_ 2565919516 PreCru_Ctrl_PresentGrade 86;
BA_ "SigType" SG_ 2565919516 PreCru_Ctrl_PresentGrade 1;
BA_ "GenSigStartValue" SG_ 2566848540 PCC_MaxPosSpd_Offset_Lvl3 15;
BA_ "GenSigStartValue" SG_ 2566848540 PCC_MaxNegSpd_Offset_Lvl3 15;
BA_ "GenSigStartValue" SG_ 2566848540 PCC_MaxPosSpd_Offset_Lvl2 15;
BA_ "GenSigStartValue" SG_ 2566848540 PCC_MaxNegSpd_Offset_Lvl2 15;
BA_ "GenSigStartValue" SG_ 2566848540 PCC_MaxPosSpd_Offset_Lvl1 15;
BA_ "GenSigStartValue" SG_ 2566848540 PCC_MaxNegSpd_Offset_Lvl1 15;
BA_ "GenSigStartValue" SG_ 2566848540 TransmissionRequestedGear 125;
BA_ "SigType" SG_ 2566848540 PCCMaxPosSpdOffset 1;
BA_ "SPN" SG_ 2566848540 PCCMaxPosSpdOffset 1090;
BA_ "SPN" SG_ 2566848540 PCCMaxNegSpdOffset 1090;
BA_ "SigType" SG_ 2566848540 PCCMaxNegSpdOffset 1;
BA_ "GenSigStartValue" SG_ 2566848540 PCCMaxNegSpdOffset 250;
BA_ "SigType" SG_ 2566848540 PCCM_BremsomatSetSpeed 1;
BA_ "SPN" SG_ 2566848540 PCCM_BremsomatSetSpeed 86;
BA_ "SigType" SG_ 2566832894 CruiseCtrlRetarderSpeedOffset 1;
BA_ "SPN" SG_ 2566832894 CruiseCtrlRetarderSpeedOffset 86;
BA_ "SigType" SG_ 2558918398 Pre_Crus_Cnrt_MaxNeg_Offset 1;
BA_ "SPN" SG_ 2558918398 Pre_Crus_Cnrt_MaxNeg_Offset 86;
BA_ "SigType" SG_ 2558918398 Pre_Crus_Cnrt_MaxPoss_Offset 1;
BA_ "SPN" SG_ 2558918398 Pre_Crus_Cnrt_MaxPoss_Offset 86;
BA_ "SPN" SG_ 2631728651 AntitheftRandomNumber 1198;
BA_ "SigType" SG_ 2631728651 AntitheftRandomNumber 1;
BA_ "SPN" SG_ 2631728651 AntitheftComponentStatusStates 1196;
BA_ "SigType" SG_ 2631728651 AntitheftComponentStatusStates 4;
BA_ "SPN" SG_ 2631728651 AntthftEncryptnSdPrsntIndicator 1194;
BA_ "SigType" SG_ 2631728651 AntthftEncryptnSdPrsntIndicator 4;
BA_ "SPN" SG_ 2631728651 AntitheftPwdValidIndicator 1195;
BA_ "SigType" SG_ 2631728651 AntitheftPwdValidIndicator 4;
BA_ "SPN" SG_ 2631794218 AntthftEncryptonIndicatorStates 1199;
BA_ "SigType" SG_ 2631794218 AntthftEncryptonIndicatorStates 4;
BA_ "SPN" SG_ 2631794218 AntitheftCmdStates 1201;
BA_ "SPN" SG_ 2631794218 AntitheftPasswordRepresentation 1202;
BA_ "SigType" SG_ 2631794218 AntitheftPasswordRepresentation 1;
BA_ "GenSigStartValue" SG_ 2566849534 MeasuredMotorControllerTemp 8736;
BA_ "SPN" SG_ 2566775040 CbA_CRfrgrntCmprssorOutletPress 2609;
BA_ "SigType" SG_ 2566775040 CbA_CRfrgrntCmprssorOutletPress 1;
BA_ "SPN" SG_ 2565668619 TotalNumberOfPacketsEoMA 2558;
BA_ "SPN" SG_ 2565668619 TotalMessageSizeEoMA 2557;
BA_ "SPN" SG_ 2565668619 TotalMessageSizeBAM 2557;
BA_ "SPN" SG_ 2565668619 TotalNumberOfPacketsBAM 2558;
BA_ "SPN" SG_ 2565668619 ConnectionAbortReason 2570;
BA_ "SPN" SG_ 2565668619 NextPacketNumberToBeSent 2562;
BA_ "SPN" SG_ 2565668619 NumberOfPacketsThatCanBeSent 2561;
BA_ "SPN" SG_ 2565668619 PGNumber 2560;
BA_ "SigType" SG_ 2565668619 PGNumber 6;
BA_ "SPN" SG_ 2565668619 MaximumNumberOfPackets 2559;
BA_ "SPN" SG_ 2565668619 TotalNumberOfPackets 2558;
BA_ "SPN" SG_ 2565668619 TotalMessageSize 2557;
BA_ "SPN" SG_ 2565668619 ControlByte 2556;
BA_ "SPN" SG_ 2565603083 SequenceNumber 2572;
BA_ "SPN" SG_ 2566834920 OccurenceCount_Camera 1214;
BA_ "SPN" SG_ 2566834920 FailureModeIdentifier1_Camera 1215;
BA_ "SPN" SG_ 2566834920 AmberWarningLampStatus_Camera 624;
BA_ "SigType" SG_ 2566834920 AmberWarningLampStatus_Camera 4;
BA_ "SPN" SG_ 2566834920 SPN4_Camera 1214;
BA_ "SPN" SG_ 2566834920 SPN3_Camera 1214;
BA_ "SPN" SG_ 2566834920 SPN2_Camera 1214;
BA_ "SPN" SG_ 2566834920 SPN1_Camera 1214;
BA_ "SPN" SG_ 2566834730 SPN4_Radar 1214;
BA_ "SPN" SG_ 2566834730 SPN3_Radar 1214;
BA_ "SPN" SG_ 2566834730 SPN2_Radar 1214;
BA_ "SPN" SG_ 2566834730 SPN1_Radar 1214;
BA_ "SPN" SG_ 2566834730 OccurenceCount_Radar 1214;
BA_ "SPN" SG_ 2566834730 FailureModeIdentifier1_Radar 1215;
BA_ "SPN" SG_ 2566834730 AmberWarningLampStatus_Radar 624;
BA_ "SigType" SG_ 2566834730 AmberWarningLampStatus_Radar 4;
BA_ "SPN" SG_ 2348875776 TransMode1 1852;
BA_ "SigType" SG_ 2348875776 TransMode1 4;
BA_ "SigType" SG_ 2566722593 BatteryRefresh 4;
BA_ "GenSigStartValue" SG_ 2566722593 TargetBatDischargeVoltage 2692.9982047;
BA_ "GenSigStartValue" SG_ 2566722593 ZcurveBasedBatVoltSetpoint 2692.9982047;
BA_ "GenSigStartValue" SG_ 2566722849 MeasuredBatteryVoltage 2692.9982047;
BA_ "GenSigStartValue" SG_ 2566722849 TargetBatteryStateofCharge 20;
BA_ "GenSigStartValue" SG_ 2566722849 MeasuredBatteryStateofCharge 20;
BA_ "SPN" SG_ 2566843134 AxleLocation 928;
BA_ "SigType" SG_ 2566843134 AxleLocation 1;
BA_ "SPN" SG_ 2566843134 CargoWeight_30 522230;
BA_ "SigType" SG_ 2566843134 CargoWeight_30 1;
BA_ "SPN" SG_ 2566843134 CargoWeight_20 522220;
BA_ "SigType" SG_ 2566843134 CargoWeight_20 1;
BA_ "SPN" SG_ 2566843134 CargoWeight_10 522210;
BA_ "SigType" SG_ 2566843134 CargoWeight_10 1;
BA_ "SPN" SG_ 2566843134 CargoWeight_00 522200;
BA_ "SigType" SG_ 2566843134 CargoWeight_00 1;
BA_ "SPN" SG_ 2566843134 TrailerWeight_30 522130;
BA_ "SigType" SG_ 2566843134 TrailerWeight_30 1;
BA_ "SPN" SG_ 2566843134 TrailerWeight_20 522120;
BA_ "SigType" SG_ 2566843134 TrailerWeight_20 1;
BA_ "SPN" SG_ 2566843134 TrailerWeight_10 522110;
BA_ "SigType" SG_ 2566843134 TrailerWeight_10 1;
BA_ "SPN" SG_ 2566843134 TrailerWeight_00 522100;
BA_ "SigType" SG_ 2566843134 TrailerWeight_00 1;
BA_ "SPN" SG_ 2566843134 AxleWeight_30 522030;
BA_ "SigType" SG_ 2566843134 AxleWeight_30 1;
BA_ "SPN" SG_ 2566843134 AxleWeight_20 522020;
BA_ "SigType" SG_ 2566843134 AxleWeight_20 1;
BA_ "SPN" SG_ 2566843134 AxleWeight_10 522010;
BA_ "SigType" SG_ 2566843134 AxleWeight_10 1;
BA_ "SPN" SG_ 2566843134 AxleWeight_00 522000;
BA_ "SigType" SG_ 2566843134 AxleWeight_00 1;
BA_ "SPN" SG_ 2365479678 SpeedDependantLevelCtrlStatus 5296;
BA_ "SigType" SG_ 2365479678 SpeedDependantLevelCtrlStatus 4;
BA_ "SPN" SG_ 2365479678 MemoryLevel 5432;
BA_ "SigType" SG_ 2365479678 MemoryLevel 4;
BA_ "SPN" SG_ 2365479678 AllwLvelCtrlDuringBrakingStatus 5294;
BA_ "SigType" SG_ 2365479678 AllwLvelCtrlDuringBrakingStatus 4;
BA_ "SPN" SG_ 2365479678 SspensionCtrlRefusalInformation 1827;
BA_ "SigType" SG_ 2365479678 SspensionCtrlRefusalInformation 4;
BA_ "SPN" SG_ 2365479678 SuspensionRemoteCtrl2 1825;
BA_ "SigType" SG_ 2365479678 SuspensionRemoteCtrl2 4;
BA_ "SPN" SG_ 2365479678 SuspensionRemoteCtrl1 1826;
BA_ "SigType" SG_ 2365479678 SuspensionRemoteCtrl1 4;
BA_ "SPN" SG_ 2365479678 RearAxleInBumperRange 1823;
BA_ "SigType" SG_ 2365479678 RearAxleInBumperRange 4;
BA_ "SPN" SG_ 2365479678 FrontAxleInBumperRange 1824;
BA_ "SigType" SG_ 2365479678 FrontAxleInBumperRange 4;
BA_ "SPN" SG_ 2365479678 DoorRelease 1744;
BA_ "SigType" SG_ 2365479678 DoorRelease 4;
BA_ "SPN" SG_ 2365479678 VehicleMotionInhibit 1745;
BA_ "SigType" SG_ 2365479678 VehicleMotionInhibit 4;
BA_ "SPN" SG_ 2365479678 SecurityDevice 1746;
BA_ "SigType" SG_ 2365479678 SecurityDevice 4;
BA_ "SPN" SG_ 2365479678 LevelCtrlMode 1741;
BA_ "SigType" SG_ 2365479678 LevelCtrlMode 4;
BA_ "SPN" SG_ 2365479678 KneelingInformation 1742;
BA_ "SigType" SG_ 2365479678 KneelingInformation 4;
BA_ "SPN" SG_ 2365479678 LiftingCtrlModeRearAxle 1756;
BA_ "SigType" SG_ 2365479678 LiftingCtrlModeRearAxle 4;
BA_ "SPN" SG_ 2365479678 LiftingCtrlModeFrontAxle 1739;
BA_ "SigType" SG_ 2365479678 LiftingCtrlModeFrontAxle 4;
BA_ "SPN" SG_ 2365479678 LoweringCtrlModeRearAxle 1755;
BA_ "SigType" SG_ 2365479678 LoweringCtrlModeRearAxle 4;
BA_ "SPN" SG_ 2365479678 LoweringCtrlModeFrontAxle 1740;
BA_ "SigType" SG_ 2365479678 LoweringCtrlModeFrontAxle 4;
BA_ "SPN" SG_ 2365479678 AboveNominalLevelRearAxle 1736;
BA_ "SigType" SG_ 2365479678 AboveNominalLevelRearAxle 4;
BA_ "SPN" SG_ 2365479678 AboveNominalLevelFrontAxle 1737;
BA_ "SigType" SG_ 2365479678 AboveNominalLevelFrontAxle 4;
BA_ "SPN" SG_ 2365479678 BelowNominalLevelRearAxle 1754;
BA_ "SigType" SG_ 2365479678 BelowNominalLevelRearAxle 4;
BA_ "SPN" SG_ 2365479678 BelowNominalLevelFrontAxle 1738;
BA_ "SigType" SG_ 2365479678 BelowNominalLevelFrontAxle 4;
BA_ "SPN" SG_ 2365479678 NominalLevelRearAxle 1733;
BA_ "SigType" SG_ 2365479678 NominalLevelRearAxle 4;
BA_ "SPN" SG_ 2365479678 NominalLevelFrontAxle 1734;
BA_ "SigType" SG_ 2365479678 NominalLevelFrontAxle 4;
BA_ "SPN" SG_ 2365479678 LiftAxle2Pos 1822;
BA_ "SigType" SG_ 2365479678 LiftAxle2Pos 4;
BA_ "SPN" SG_ 2365479678 LiftAxle1Pos 1743;
BA_ "SigType" SG_ 2365479678 LiftAxle1Pos 4;
BA_ "SigType" SG_ 2566841344 EngineOperationMode 4;
BA_ "SPN" SG_ 2566841344 EngOverspeedTest 2812;
BA_ "SigType" SG_ 2566841344 EngOverspeedTest 4;
BA_ "SPN" SG_ 2566841344 EngAirShutoffCmdStatus 2813;
BA_ "SigType" SG_ 2566841344 EngAirShutoffCmdStatus 4;
BA_ "SPN" SG_ 2566841344 EngAlarmOutputCmdStatus 2814;
BA_ "SigType" SG_ 2566841344 EngAlarmOutputCmdStatus 4;
BA_ "SPN" SG_ 2566841344 EngAlarmAcknowledge 2815;
BA_ "SigType" SG_ 2566841344 EngAlarmAcknowledge 4;
BA_ "SPN" SG_ 2566841344 EngProtectionSystemConfig 1111;
BA_ "SigType" SG_ 2566841344 EngProtectionSystemConfig 4;
BA_ "SPN" SG_ 2566841344 EngProtectionSystemTimerState 1107;
BA_ "SigType" SG_ 2566841344 EngProtectionSystemTimerState 4;
BA_ "SPN" SG_ 2566841344 EngPrtectionSystemTimerOverride 1108;
BA_ "SigType" SG_ 2566841344 EngPrtectionSystemTimerOverride 4;
BA_ "SPN" SG_ 2566841344 EngPrtctnSystmApprchingShutdown 1109;
BA_ "SigType" SG_ 2566841344 EngPrtctnSystmApprchingShutdown 4;
BA_ "SPN" SG_ 2566841344 EngWaitToStartLamp 1081;
BA_ "SigType" SG_ 2566841344 EngWaitToStartLamp 4;
BA_ "SPN" SG_ 2566841344 RefrigerantHighPressSwitch 605;
BA_ "SigType" SG_ 2566841344 RefrigerantHighPressSwitch 4;
BA_ "SPN" SG_ 2566841344 RefrigerantLowPressSwitch 875;
BA_ "SigType" SG_ 2566841344 RefrigerantLowPressSwitch 4;
BA_ "SPN" SG_ 2566841344 A_CHighPressFanSwitch 985;
BA_ "SigType" SG_ 2566841344 A_CHighPressFanSwitch 4;
BA_ "SPN" SG_ 2566841344 EngIdleShutdownTimerFunction 591;
BA_ "SigType" SG_ 2566841344 EngIdleShutdownTimerFunction 4;
BA_ "SPN" SG_ 2566841344 EngIdleShutdownTimerState 590;
BA_ "SigType" SG_ 2566841344 EngIdleShutdownTimerState 4;
BA_ "SPN" SG_ 2566841344 EngIdleShutdownTimerOverride 592;
BA_ "SigType" SG_ 2566841344 EngIdleShutdownTimerOverride 4;
BA_ "SPN" SG_ 2566841344 EngIdleShutdownDriverAlertMode 594;
BA_ "SigType" SG_ 2566841344 EngIdleShutdownDriverAlertMode 4;
BA_ "SPN" SG_ 2566841344 PTOShutdownHasShutdownEng 5404;
BA_ "SigType" SG_ 2566841344 PTOShutdownHasShutdownEng 4;
BA_ "SPN" SG_ 2566841344 EngPrtctnSystmHasShutdownEngine 1110;
BA_ "SigType" SG_ 2566841344 EngPrtctnSystmHasShutdownEngine 4;
BA_ "SPN" SG_ 2566841344 EngIdlShutdownHasShutdownEngine 593;
BA_ "SigType" SG_ 2566841344 EngIdlShutdownHasShutdownEngine 4;
BA_ "SPN" SG_ 2566841344 EngAirShutoffStatus 3667;
BA_ "SigType" SG_ 2566841344 EngAirShutoffStatus 4;
BA_ "GenSigStartValue" SG_ 2566848256 TransmissionCurrentGear 125;
BA_ "SPN" SG_ 2566848256 WaterInFuelIndicator 97;
BA_ "SigType" SG_ 2566848256 WaterInFuelIndicator 4;
BA_ "SPN" SG_ 2566719744 HighResolutionEngTotalFuelUsed 5054;
BA_ "SigType" SG_ 2566719744 HighResolutionEngTotalFuelUsed 1;
BA_ "SPN" SG_ 2566719744 HighResolutionEngTripFuel 5053;
BA_ "SigType" SG_ 2566719744 HighResolutionEngTripFuel 1;
BA_ "SPN" SG_ 2566844928 EngAverageFuelEconomy 185;
BA_ "SigType" SG_ 2566844928 EngAverageFuelEconomy 1;
BA_ "SPN" SG_ 2566844928 EngInstantaneousFuelEconomy 184;
BA_ "SigType" SG_ 2566844928 EngInstantaneousFuelEconomy 1;
BA_ "SPN" SG_ 2566844928 EngFuelRate 183;
BA_ "SigType" SG_ 2566844928 EngFuelRate 1;
BA_ "SPN" SG_ 2566844928 EngThrottleValve1Pos 51;
BA_ "SigType" SG_ 2566844928 EngThrottleValve1Pos 1;
BA_ "SPN" SG_ 2566831360 FanSpeed 1639;
BA_ "SigType" SG_ 2566831360 FanSpeed 1;
BA_ "SPN" SG_ 2566831360 FanDriveState 977;
BA_ "SigType" SG_ 2566831360 FanDriveState 4;
BA_ "SPN" SG_ 2566831360 EstPercentFanSpeed 975;
BA_ "SigType" SG_ 2566831360 EstPercentFanSpeed 1;
BA_ "SPN" SG_ 2566831360 HydFanMotorPress 4211;
BA_ "SigType" SG_ 2566831360 HydFanMotorPress 1;
BA_ "SPN" SG_ 2566831360 FanDriveBypassCmdStatus 4212;
BA_ "SigType" SG_ 2566831360 FanDriveBypassCmdStatus 1;
BA_ "SPN" SG_ 2566843904 EngFuelTemp1 174;
BA_ "SigType" SG_ 2566843904 EngFuelTemp1 1;
BA_ "SPN" SG_ 2566843904 EngIntercoolerThermostatOpening 1134;
BA_ "SigType" SG_ 2566843904 EngIntercoolerThermostatOpening 1;
BA_ "SPN" SG_ 2566843904 EngIntercoolerTemp 52;
BA_ "SigType" SG_ 2566843904 EngIntercoolerTemp 1;
BA_ "SPN" SG_ 2566843904 EngTurboOilTemp 176;
BA_ "SigType" SG_ 2566843904 EngTurboOilTemp 1;
BA_ "SPN" SG_ 2566843904 EngOilTemp1 175;
BA_ "SigType" SG_ 2566843904 EngOilTemp1 1;
BA_ "SPN" SG_ 2566843904 EngCoolantTemp 1637;
BA_ "SigType" SG_ 2566843904 EngCoolantTemp 1;
BA_ "SPN" SG_ 2566841088 SupportTSC1CtrlPurposeGroup4 3348;
BA_ "SigType" SG_ 2566841088 SupportTSC1CtrlPurposeGroup4 1;
BA_ "SPN" SG_ 2566841088 SupportTSC1CtrlPurposeGroup3 3347;
BA_ "SigType" SG_ 2566841088 SupportTSC1CtrlPurposeGroup3 1;
BA_ "SPN" SG_ 2566841088 SupportTSC1CtrlPurposeGroup2 3346;
BA_ "SigType" SG_ 2566841088 SupportTSC1CtrlPurposeGroup2 1;
BA_ "SPN" SG_ 2566841088 SupportTSC1CtrlPurposeGroup1 3345;
BA_ "SigType" SG_ 2566841088 SupportTSC1CtrlPurposeGroup1 1;
BA_ "SPN" SG_ 2566841088 SupportVariableRateTSC1Message 3344;
BA_ "SigType" SG_ 2566841088 SupportVariableRateTSC1Message 1;
BA_ "SPN" SG_ 2566841088 EngDefaultTorqueLimit 1846;
BA_ "SigType" SG_ 2566841088 EngDefaultTorqueLimit 1;
BA_ "SPN" SG_ 2566841088 EngMomentOfInertia 1794;
BA_ "SigType" SG_ 2566841088 EngMomentOfInertia 1;
BA_ "SPN" SG_ 2566841088 EngExRngRqdSpdCtrlRngUpperLimit 1712;
BA_ "SigType" SG_ 2566841088 EngExRngRqdSpdCtrlRngUpperLimit 1;
BA_ "SPN" SG_ 2566841088 EngRqdTorqueCtrlRangeUpperLimit 538;
BA_ "SigType" SG_ 2566841088 EngRqdTorqueCtrlRangeUpperLimit 1;
BA_ "SPN" SG_ 2566841088 EngRqdTorqueCtrlRangeLowerLimit 537;
BA_ "SigType" SG_ 2566841088 EngRqdTorqueCtrlRangeLowerLimit 1;
BA_ "SPN" SG_ 2566841088 EngRqedSpeedCtrlRangeUpperLimit 536;
BA_ "SigType" SG_ 2566841088 EngRqedSpeedCtrlRangeUpperLimit 1;
BA_ "SPN" SG_ 2566841088 EngRqedSpeedCtrlRangeLowerLimit 535;
BA_ "SigType" SG_ 2566841088 EngRqedSpeedCtrlRangeLowerLimit 1;
BA_ "SPN" SG_ 2566841088 EngMxMomentaryOverrideTimeLimit 534;
BA_ "SigType" SG_ 2566841088 EngMxMomentaryOverrideTimeLimit 1;
BA_ "SPN" SG_ 2566841088 EngMxMmntaryOverrideSpeedPoint7 533;
BA_ "SigType" SG_ 2566841088 EngMxMmntaryOverrideSpeedPoint7 1;
BA_ "SPN" SG_ 2566841088 EngReferenceTorque 544;
BA_ "SigType" SG_ 2566841088 EngReferenceTorque 1;
BA_ "SPN" SG_ 2566841088 EngSpeedAtHighIdlePoint6 532;
BA_ "SigType" SG_ 2566841088 EngSpeedAtHighIdlePoint6 1;
BA_ "SPN" SG_ 2566841088 EngGainOfEndspeedGovernor 545;
BA_ "SigType" SG_ 2566841088 EngGainOfEndspeedGovernor 1;
BA_ "SPN" SG_ 2566841088 EngPercentTorqueAtPoint5 543;
BA_ "SigType" SG_ 2566841088 EngPercentTorqueAtPoint5 1;
BA_ "SPN" SG_ 2566841088 EngSpeedAtPoint5 531;
BA_ "SigType" SG_ 2566841088 EngSpeedAtPoint5 1;
BA_ "SPN" SG_ 2566841088 EngPercentTorqueAtPoint4 542;
BA_ "SigType" SG_ 2566841088 EngPercentTorqueAtPoint4 1;
BA_ "SPN" SG_ 2566841088 EngSpeedAtPoint4 530;
BA_ "SigType" SG_ 2566841088 EngSpeedAtPoint4 1;
BA_ "SPN" SG_ 2566841088 EngPercentTorqueAtPoint3 541;
BA_ "SigType" SG_ 2566841088 EngPercentTorqueAtPoint3 1;
BA_ "SPN" SG_ 2566841088 EngSpeedAtPoint3 529;
BA_ "SigType" SG_ 2566841088 EngSpeedAtPoint3 1;
BA_ "SPN" SG_ 2566841088 EngPercentTorqueAtPoint2 540;
BA_ "SigType" SG_ 2566841088 EngPercentTorqueAtPoint2 1;
BA_ "SPN" SG_ 2566841088 EngSpeedAtPoint2 528;
BA_ "SigType" SG_ 2566841088 EngSpeedAtPoint2 1;
BA_ "SPN" SG_ 2566841088 EngPercentTorqueAtIdlePoint1 539;
BA_ "SigType" SG_ 2566841088 EngPercentTorqueAtIdlePoint1 1;
BA_ "SPN" SG_ 2566841088 EngSpeedAtIdlePoint1 188;
BA_ "SigType" SG_ 2566841088 EngSpeedAtIdlePoint1 1;
BA_ "SPN" SG_ 2566840064 EngsDsrdOprtngSpdAsymmtryAdjstmn 519;
BA_ "SigType" SG_ 2566840064 EngsDsrdOprtngSpdAsymmtryAdjstmn 1;
BA_ "SystemSignalLongSymbol" SG_ 2566840064 EngsDsrdOprtngSpdAsymmtryAdjstmn "EngsDsrdOprtngSpdAsymmtryAdjstmnt";
BA_ "SPN" SG_ 2566840064 Aftrtratment1ExhaustGasMassFlow 3236;
BA_ "SigType" SG_ 2566840064 Aftrtratment1ExhaustGasMassFlow 1;
BA_ "SPN" SG_ 2566840064 Aftertreatment2IntakeDewPoint 3239;
BA_ "SigType" SG_ 2566840064 Aftertreatment2IntakeDewPoint 4;
BA_ "SPN" SG_ 2566840064 Aftertreatment2ExhaustDewPoint 3240;
BA_ "SigType" SG_ 2566840064 Aftertreatment2ExhaustDewPoint 4;
BA_ "SPN" SG_ 2566840064 Aftertreatment1IntakeDewPoint 3237;
BA_ "SigType" SG_ 2566840064 Aftertreatment1IntakeDewPoint 4;
BA_ "SPN" SG_ 2566840064 Aftertreatment1ExhaustDewPoint 3238;
BA_ "SigType" SG_ 2566840064 Aftertreatment1ExhaustDewPoint 4;
BA_ "GenSigStartValue" SG_ 2566840064 EstEngPrsticLossesPercentTorque 125;
BA_ "SPN" SG_ 2566840064 EstEngPrsticLossesPercentTorque 2978;
BA_ "SigType" SG_ 2566840064 EstEngPrsticLossesPercentTorque 1;
BA_ "SPN" SG_ 2566840064 EngsDesiredOperatingSpeed 515;
BA_ "SigType" SG_ 2566840064 EngsDesiredOperatingSpeed 1;
BA_ "GenSigStartValue" SG_ 2566840064 NominalFrictionPercentTorque 125;
BA_ "SPN" SG_ 2566840064 NominalFrictionPercentTorque 514;
BA_ "SigType" SG_ 2566840064 NominalFrictionPercentTorque 1;
BA_ "SPN" SG_ 2364539648 EstPumpingPercentTorque 5398;
BA_ "SigType" SG_ 2364539648 EstPumpingPercentTorque 1;
BA_ "SPN" SG_ 2364539648 ActlMxAvailableEngPercentTorque 3357;
BA_ "SigType" SG_ 2364539648 ActlMxAvailableEngPercentTorque 1;
BA_ "SPN" SG_ 2364539648 AccelPedalPos2 29;
BA_ "SigType" SG_ 2364539648 AccelPedalPos2 1;
BA_ "SPN" SG_ 2364539648 VhclAccelerationRateLimitStatus 2979;
BA_ "SigType" SG_ 2364539648 VhclAccelerationRateLimitStatus 4;
BA_ "SPN" SG_ 2364539648 EngPercentLoadAtCurrentSpeed 92;
BA_ "SigType" SG_ 2364539648 EngPercentLoadAtCurrentSpeed 1;
BA_ "SPN" SG_ 2364539648 GearShiftIndication 2970;
BA_ "SigType" SG_ 2364539648 GearShiftIndication 4;
BA_ "SPN" SG_ 2364539648 RoadSpeedLimitStatus 1437;
BA_ "SigType" SG_ 2364539648 RoadSpeedLimitStatus 4;
BA_ "SPN" SG_ 2364539648 AccelPedalKickdownSwitch 559;
BA_ "SigType" SG_ 2364539648 AccelPedalKickdownSwitch 4;
BA_ "SPN" SG_ 2364539648 AccelPedal1LowIdleSwitch 558;
BA_ "SigType" SG_ 2364539648 AccelPedal1LowIdleSwitch 4;
BA_ "SPN" SG_ 2364539648 RemoteAccelPedalPos 974;
BA_ "SigType" SG_ 2364539648 RemoteAccelPedalPos 1;
BA_ "SPN" SG_ 2364539648 AccelPedalPos1 91;
BA_ "SigType" SG_ 2364539648 AccelPedalPos1 1;
BA_ "SPN" SG_ 2364539904 SrcAddrssOfCtrllngDvcFrEngCntrl 1483;
BA_ "SigType" SG_ 2364539904 SrcAddrssOfCtrllngDvcFrEngCntrl 1;
BA_ "SPN" SG_ 2364539904 ActlEngPrcntTrqueHighResolution 4154;
BA_ "SigType" SG_ 2364539904 ActlEngPrcntTrqueHighResolution 1;
BA_ "GenSigStartValue" SG_ 2364539904 EngDemandPercentTorque 125;
BA_ "SPN" SG_ 2364539904 EngDemandPercentTorque 2432;
BA_ "SigType" SG_ 2364539904 EngDemandPercentTorque 1;
BA_ "SPN" SG_ 2364539904 EngStarterMode 1675;
BA_ "SigType" SG_ 2364539904 EngStarterMode 4;
BA_ "SPN" SG_ 2364539904 EngSpeed 190;
BA_ "SigType" SG_ 2364539904 EngSpeed 1;
BA_ "GenSigStartValue" SG_ 2364539904 ActualEngPercentTorque 125;
BA_ "SPN" SG_ 2364539904 ActualEngPercentTorque 513;
BA_ "SigType" SG_ 2364539904 ActualEngPercentTorque 1;
BA_ "GenSigStartValue" SG_ 2364539904 DriversDemandEngPercentTorque 125;
BA_ "SPN" SG_ 2364539904 DriversDemandEngPercentTorque 512;
BA_ "SigType" SG_ 2364539904 DriversDemandEngPercentTorque 1;
BA_ "SPN" SG_ 2364539904 EngTorqueMode 899;
BA_ "SigType" SG_ 2364539904 EngTorqueMode 4;
BA_ "SPN" SG_ 2566844672 PTOGovernorState_CCVS_ECM 976;
BA_ "SigType" SG_ 2566844672 PTOGovernorState_CCVS_ECM 4;
BA_ "SPN" SG_ 2566844672 EngShutdownOverrideSwitch 1237;
BA_ "SigType" SG_ 2566844672 EngShutdownOverrideSwitch 4;
BA_ "SPN" SG_ 2566844672 EngTestModeSwitch 966;
BA_ "SigType" SG_ 2566844672 EngTestModeSwitch 4;
BA_ "SPN" SG_ 2566844672 EngIdleDecrementSwitch 967;
BA_ "SigType" SG_ 2566844672 EngIdleDecrementSwitch 4;
BA_ "SPN" SG_ 2566844672 EngIdleIncrementSwitch 968;
BA_ "SigType" SG_ 2566844672 EngIdleIncrementSwitch 4;
BA_ "SPN" SG_ 2566844672 CruiseCtrlStates 527;
BA_ "SPN" SG_ 2566844672 CruiseCtrlSetSpeed 86;
BA_ "SigType" SG_ 2566844672 CruiseCtrlSetSpeed 1;
BA_ "SPN" SG_ 2566844672 CruiseCtrlAccelerateSwitch_CCVSE 602;
BA_ "SigType" SG_ 2566844672 CruiseCtrlAccelerateSwitch_CCVSE 4;
BA_ "SPN" SG_ 2566844672 CruiseCtrlResumeSwitch_CCVS_ECM 601;
BA_ "SigType" SG_ 2566844672 CruiseCtrlResumeSwitch_CCVS_ECM 4;
BA_ "SPN" SG_ 2566844672 CruiseCtrlCoastSwitch_CCVS_ECM 600;
BA_ "SigType" SG_ 2566844672 CruiseCtrlCoastSwitch_CCVS_ECM 4;
BA_ "SPN" SG_ 2566844672 CruiseCtrlSetSwitch 599;
BA_ "SigType" SG_ 2566844672 CruiseCtrlSetSwitch 4;
BA_ "SPN" SG_ 2566844672 ClutchSwitch_CCVS_ECM 598;
BA_ "SigType" SG_ 2566844672 ClutchSwitch_CCVS_ECM 4;
BA_ "SPN" SG_ 2566844672 BrakeSwitch_CCVS_ECM 597;
BA_ "SigType" SG_ 2566844672 BrakeSwitch_CCVS_ECM 4;
BA_ "SPN" SG_ 2566844672 CruiseCtrlEnableSwitch 596;
BA_ "SigType" SG_ 2566844672 CruiseCtrlEnableSwitch 4;
BA_ "SPN" SG_ 2566844672 CruiseCtrlActive 595;
BA_ "SigType" SG_ 2566844672 CruiseCtrlActive 4;
BA_ "SPN" SG_ 2566844672 WheelBasedVehicleSpeed_CCVS_ECM 84;
BA_ "SigType" SG_ 2566844672 WheelBasedVehicleSpeed_CCVS_ECM 1;
BA_ "SPN" SG_ 2566844672 ParkingBrakeSwitch_CCVS_ECM 70;
BA_ "SigType" SG_ 2566844672 ParkingBrakeSwitch_CCVS_ECM 4;
BA_ "SPN" SG_ 2566845696 RoadSurfaceTemp 79;
BA_ "SigType" SG_ 2566845696 RoadSurfaceTemp 1;
BA_ "GenSigStartValue" SG_ 2566845696 RoadSurfaceTemp 233;
BA_ "SPN" SG_ 2566845696 AmbientAirTemp 171;
BA_ "SigType" SG_ 2566845696 AmbientAirTemp 1;
BA_ "SPN" SG_ 2566845696 CabInteriorTemp 170;
BA_ "SigType" SG_ 2566845696 CabInteriorTemp 1;
BA_ "SPN" SG_ 2566845696 EngAirIntakeTemp 172;
BA_ "SigType" SG_ 2566845696 EngAirIntakeTemp 1;
BA_ "SPN" SG_ 2566845696 BarometricPress 108;
BA_ "SigType" SG_ 2566845696 BarometricPress 1;
BA_ "SPN" SG_ 2566801923 TransEngCrankEnable 2900;
BA_ "SigType" SG_ 2566801923 TransEngCrankEnable 4;
BA_ "SPN" SG_ 2565406224 ControlByte 2541;
BA_ "SPN" SG_ 2565406224 ParameterGroupNumber 2574;
BA_ "SigType" SG_ 2565406224 ParameterGroupNumber 6;
BA_ "SPN" SG_ 2565406224 GroupFunctionValue 2542;
BA_ "SigType" SG_ 2565406224 GroupFunctionValue 1;
BA_ "SPN" SG_ 2566810606 Driver2 1626;
BA_ "SigType" SG_ 2566810606 Driver2 8;
BA_ "SPN" SG_ 2566810606 Driver1 1625;
BA_ "SigType" SG_ 2566810606 Driver1 8;
BA_ "SPN" SG_ 2365484270 VehicleOverspeed 1614;
BA_ "SigType" SG_ 2365484270 VehicleOverspeed 4;
BA_ "SPN" SG_ 2365484270 VehicleMotion 1611;
BA_ "SigType" SG_ 2365484270 VehicleMotion 4;
BA_ "SPN" SG_ 2365484270 TachographVehicleSpeed 1624;
BA_ "SigType" SG_ 2365484270 TachographVehicleSpeed 1;
BA_ "SPN" SG_ 2365484270 TachographOutputShaftSpeed 1623;
BA_ "SigType" SG_ 2365484270 TachographOutputShaftSpeed 1;
BA_ "SPN" SG_ 2365484270 DirectionIndicator 1619;
BA_ "SigType" SG_ 2365484270 DirectionIndicator 4;
BA_ "SPN" SG_ 2365484270 TachographPerformance 1620;
BA_ "SigType" SG_ 2365484270 TachographPerformance 4;
BA_ "SPN" SG_ 2365484270 HandlingInformation 1621;
BA_ "SigType" SG_ 2365484270 HandlingInformation 4;
BA_ "SPN" SG_ 2365484270 SystemEvent 1622;
BA_ "SigType" SG_ 2365484270 SystemEvent 4;
BA_ "SPN" SG_ 2365484270 DriverCardDriver2 1616;
BA_ "SigType" SG_ 2365484270 DriverCardDriver2 4;
BA_ "SPN" SG_ 2365484270 Driver2TimeRelatedStates 1618;
BA_ "SigType" SG_ 2365484270 Driver2TimeRelatedStates 4;
BA_ "SPN" SG_ 2365484270 DriverCardDriver1 1615;
BA_ "SigType" SG_ 2365484270 DriverCardDriver1 4;
BA_ "SPN" SG_ 2365484270 Driver1TimeRelatedStates 1617;
BA_ "SigType" SG_ 2365484270 Driver1TimeRelatedStates 4;
BA_ "SPN" SG_ 2365484270 Driver2WorkingState 1613;
BA_ "SPN" SG_ 2365484270 Driver1WorkingState 1612;
BA_ "SPN" SG_ 2566832366 ServiceComponentIdentificationB 912;
BA_ "SigType" SG_ 2566832366 ServiceComponentIdentificationB 1;
BA_ "SPN" SG_ 2566832366 ServiceComponentIdentificationA 911;
BA_ "SigType" SG_ 2566832366 ServiceComponentIdentificationA 1;
BA_ "SPN" SG_ 2566832366 SrvceDelay_OperationalTimeBased 916;
BA_ "SigType" SG_ 2566832366 SrvceDelay_OperationalTimeBased 1;
BA_ "SPN" SG_ 2566832366 ServiceDelay_CalendarTimeBased 915;
BA_ "SigType" SG_ 2566832366 ServiceDelay_CalendarTimeBased 1;
BA_ "SPN" SG_ 2566832366 ServiceDistance 914;
BA_ "SigType" SG_ 2566832366 ServiceDistance 1;
BA_ "SPN" SG_ 2566832366 ServiceComponentIdentification 1584;
BA_ "SigType" SG_ 2566832366 ServiceComponentIdentification 1;
BA_ "SPN" SG_ 2566832622 HighResolutionTripDistance 918;
BA_ "SigType" SG_ 2566832622 HighResolutionTripDistance 1;
BA_ "SPN" SG_ 2566832622 HghRslutionTotalVehicleDistance 917;
BA_ "SigType" SG_ 2566832622 HghRslutionTotalVehicleDistance 1;
BA_ "SPN" SG_ 2566843630 VehicleIdentificationNumber 237;
BA_ "SigType" SG_ 2566843630 VehicleIdentificationNumber 8;
BA_ "SPN" SG_ 2566842094 LocalHourOffset 1602;
BA_ "SigType" SG_ 2566842094 LocalHourOffset 1;
BA_ "SPN" SG_ 2566842094 LocalMinuteOffset 1601;
BA_ "SigType" SG_ 2566842094 LocalMinuteOffset 1;
BA_ "SPN" SG_ 2566842094 Year 964;
BA_ "SigType" SG_ 2566842094 Year 1;
BA_ "SPN" SG_ 2566842094 Day 962;
BA_ "SigType" SG_ 2566842094 Day 1;
BA_ "GenSigStartValue" SG_ 2566842094 Day 4;
BA_ "SPN" SG_ 2566842094 Month 963;
BA_ "SigType" SG_ 2566842094 Month 1;
BA_ "GenSigStartValue" SG_ 2566842094 Month 1;
BA_ "SPN" SG_ 2566842094 Hours 961;
BA_ "SigType" SG_ 2566842094 Hours 1;
BA_ "SPN" SG_ 2566842094 Minutes 960;
BA_ "SigType" SG_ 2566842094 Minutes 1;
BA_ "SPN" SG_ 2566842094 Seconds 959;
BA_ "SigType" SG_ 2566842094 Seconds 1;
BA_ "GenSigStartValue" SG_ 2631855639 Reset_NotDefined_3 3;
BA_ "GenSigStartValue" SG_ 2631855639 Reset_Notdefined_1 15;
BA_ "SPN" SG_ 2631855639 TripGroup2Proprietary 989;
BA_ "SigType" SG_ 2631855639 TripGroup2Proprietary 4;
BA_ "GenSigStartValue" SG_ 2631855639 TripGroup2Proprietary 3;
BA_ "SPN" SG_ 2631855639 TripGroup1 988;
BA_ "SigType" SG_ 2631855639 TripGroup1 4;
BA_ "SPN" SG_ 2566847511 FuelLevel1 96;
BA_ "SigType" SG_ 2566847511 FuelLevel1 1;
BA_ "SPN" SG_ 2566847511 CargoAmbientTemp 169;
BA_ "SigType" SG_ 2566847511 CargoAmbientTemp 1;
BA_ "GenSigStartValue" SG_ 2566838551 EcoRollSelection 1;
BA_ "SPN" SG_ 2566838551 ACCUsageDemand_AUXIO_R_IC 5023;
BA_ "SigType" SG_ 2566838551 ACCUsageDemand_AUXIO_R_IC 4;
BA_ "SigType" SG_ 2566838551 AuxI_O03_RetarderLeverPosition 4;
BA_ "SPN" SG_ 2566838551 AuxI_O03_RetarderLeverPosition 702;
BA_ "SPN" SG_ 2566838551 AuxI_O02_BlendingSwitchPos 702;
BA_ "SigType" SG_ 2566838551 AuxI_O02_BlendingSwitchPos 4;
BA_ "SPN" SG_ 2566838551 PCCLevelSelection 1201;
BA_ "SigType" SG_ 2566838551 CabinTiltSwitch 1;
BA_ "SPN" SG_ 2566838551 CabinTiltSwitch 84;
BA_ "SPN" SG_ 2566827543 ServiceBrakeCircuit2AirPress 1088;
BA_ "SigType" SG_ 2566827543 ServiceBrakeCircuit2AirPress 1;
BA_ "SPN" SG_ 2566827543 ServiceBrakeCircuit1AirPress 1087;
BA_ "SigType" SG_ 2566827543 ServiceBrakeCircuit1AirPress 1;
BA_ "SPN" SG_ 2566827543 AuxEquipmentSupplyPress 1089;
BA_ "SigType" SG_ 2566827543 AuxEquipmentSupplyPress 1;
BA_ "GenSigStartValue" SG_ 2566827543 AuxEquipmentSupplyPress 31.875;
BA_ "SPN" SG_ 2566827543 ParkingAnd_OrTrailerAirPress 1086;
BA_ "SigType" SG_ 2566827543 ParkingAnd_OrTrailerAirPress 1;
BA_ "GenSigStartValue" SG_ 2566827543 ParkingAnd_OrTrailerAirPress 31.875;
BA_ "SPN" SG_ 2566827543 PneumaticSupplyPress 46;
BA_ "SigType" SG_ 2566827543 PneumaticSupplyPress 1;
BA_ "GenSigStartValue" SG_ 2566827543 PneumaticSupplyPress 31.875;
BA_ "SPN" SG_ 2565537534 ParameterGroupNumber 2574;
BA_ "SigType" SG_ 2565537534 ParameterGroupNumber 6;
BA_ "SPN" SG_ 2631729175 AntthftEncryptonIndicatorStates 1199;
BA_ "SigType" SG_ 2631729175 AntthftEncryptonIndicatorStates 4;
BA_ "SPN" SG_ 2631729175 AntitheftDesiredExitModeStates 1200;
BA_ "SigType" SG_ 2631729175 AntitheftDesiredExitModeStates 4;
BA_ "SPN" SG_ 2631729175 AntitheftCmdStates 1201;
BA_ "SPN" SG_ 2631729175 AntitheftPasswordRepresentation 1202;
BA_ "SigType" SG_ 2631729175 AntitheftPasswordRepresentation 1;
BA_ "SigType" SG_ 2566806504 Line_type_left_side 4;
BA_ "SPN" SG_ 2566806504 Line_type_left_side 1702;
BA_ "SigType" SG_ 2566806504 Line_type_right_side 4;
BA_ "SPN" SG_ 2566806504 Line_type_right_side 1702;
BA_ "SPN" SG_ 2566806504 LnDprtureIndicationEnableStatus 1702;
BA_ "SigType" SG_ 2566806504 LnDprtureIndicationEnableStatus 4;
BA_ "SPN" SG_ 2566806504 LaneTrackingStatusLeftSide 1710;
BA_ "SigType" SG_ 2566806504 LaneTrackingStatusLeftSide 4;
BA_ "SPN" SG_ 2566806504 LaneTrackingStatusRightSide 1711;
BA_ "SigType" SG_ 2566806504 LaneTrackingStatusRightSide 4;
BA_ "SPN" SG_ 2431649768 LaneDepartureRightSide 3566;
BA_ "SigType" SG_ 2431649768 LaneDepartureRightSide 4;
BA_ "SPN" SG_ 2431649768 LaneDepartureLeftSide 3565;
BA_ "SigType" SG_ 2431649768 LaneDepartureLeftSide 4;
BA_ "SPN" SG_ 2431649768 LaneDepartureImminentLeftSide 1700;
BA_ "SigType" SG_ 2431649768 LaneDepartureImminentLeftSide 4;
BA_ "SPN" SG_ 2431649768 LaneDepartureImminentRightSide 1701;
BA_ "SigType" SG_ 2431649768 LaneDepartureImminentRightSide 4;
BA_ "SPN" SG_ 2348810282 MessageCounter 4206;
BA_ "SPN" SG_ 2348810282 ControlPurpose 3350;
BA_ "SPN" SG_ 2348810282 TransmissionRate 3349;
BA_ "SPN" SG_ 2348810282 EngRqedTorque_TorqueLimit 518;
BA_ "SigType" SG_ 2348810282 EngRqedTorque_TorqueLimit 1;
BA_ "SPN" SG_ 2348810282 EngRqedSpeed_SpeedLimit 898;
BA_ "SigType" SG_ 2348810282 EngRqedSpeed_SpeedLimit 1;
BA_ "SPN" SG_ 2348810282 OverrideCtrlModePriority 897;
BA_ "SPN" SG_ 2348810282 EngRqedSpeedCtrlConditions 696;
BA_ "SPN" SG_ 2348810282 EngOverrideCtrlMode 695;
BA_ "SPN" SG_ 2348810282 MessageChecksum 4207;
BA_ "SPN" SG_ 2348810282 EngineRequestedTorqueHiRes 4191;
BA_ "SPN" SG_ 2349075242 XBRMessageChecksum 3188;
BA_ "SigType" SG_ 2349075242 XBRMessageChecksum 4;
BA_ "SPN" SG_ 2349075242 XBRMessageCounter 3189;
BA_ "SigType" SG_ 2349075242 XBRMessageCounter 4;
BA_ "SPN" SG_ 2349075242 XBRCtrlMode 2916;
BA_ "SigType" SG_ 2349075242 XBRCtrlMode 4;
BA_ "SPN" SG_ 2349075242 XBRPriority 2915;
BA_ "SigType" SG_ 2349075242 XBRPriority 4;
BA_ "SPN" SG_ 2349075242 XBREBIMode 2914;
BA_ "SigType" SG_ 2349075242 XBREBIMode 4;
BA_ "SPN" SG_ 2349075242 ExtlAccelerationDemand 2920;
BA_ "SigType" SG_ 2349075242 ExtlAccelerationDemand 1;
BA_ "SPN" SG_ 2349075242 XBRUrgency 4099;
BA_ "SigType" SG_ 2349075242 XBRUrgency 1;
BA_ "SPN" SG_ 2365443122 OperatorsDesiredBacklight 2878;
BA_ "SigType" SG_ 2365443122 OperatorsDesiredBacklight 1;
BA_ "SPN" SG_ 2365443122 HighLowBeamSwitch 2874;
BA_ "SigType" SG_ 2365443122 HighLowBeamSwitch 4;
BA_ "SPN" SG_ 2365443122 HazardLightSwitch 2875;
BA_ "SigType" SG_ 2365443122 HazardLightSwitch 4;
BA_ "SPN" SG_ 2365443122 TurnSignalSwitch_OEL_BCM 2876;
BA_ "SigType" SG_ 2365443122 TurnSignalSwitch_OEL_BCM 4;
BA_ "SPN" SG_ 2365443122 MainLightSwitch 2872;
BA_ "SigType" SG_ 2365443122 MainLightSwitch 4;
BA_ "SPN" SG_ 2365443122 WorkLightSwitch 2873;
BA_ "SigType" SG_ 2365443122 WorkLightSwitch 4;
BA_ "SPN" SG_ 2561271841 LaneDepartureWarningEnableCmd 3564;
BA_ "SigType" SG_ 2561271841 LaneDepartureWarningEnableCmd 4;
BA_ "SPN" SG_ 2565867041 RearAxleGroupEngagementStatus 3820;
BA_ "SigType" SG_ 2565867041 RearAxleGroupEngagementStatus 4;
BA_ "GenSigStartValue" SG_ 2565867041 RearAxleGroupEngagementStatus 3;
BA_ "SPN" SG_ 2565867041 FrontAxleGroupEngagementStatus 3819;
BA_ "SigType" SG_ 2565867041 FrontAxleGroupEngagementStatus 4;
BA_ "SPN" SG_ 2565867041 DiffLockStateCentralRear 566;
BA_ "SigType" SG_ 2565867041 DiffLockStateCentralRear 4;
BA_ "GenSigStartValue" SG_ 2565867041 DiffLockStateCentralRear 3;
BA_ "SPN" SG_ 2565867041 DiffLockStateCentralFront 565;
BA_ "SigType" SG_ 2565867041 DiffLockStateCentralFront 4;
BA_ "GenSigStartValue" SG_ 2565867041 DiffLockStateCentralFront 3;
BA_ "SPN" SG_ 2565867041 Interlock 564;
BA_ "SigType" SG_ 2565867041 Interlock 4;
BA_ "GenSigStartValue" SG_ 2565867041 Interlock 3;
BA_ "SPN" SG_ 2565867041 DiffLockStateRearAxle2 570;
BA_ "SigType" SG_ 2565867041 DiffLockStateRearAxle2 4;
BA_ "GenSigStartValue" SG_ 2565867041 DiffLockStateRearAxle2 3;
BA_ "SPN" SG_ 2565867041 DiffLockStateRearAxle1 569;
BA_ "SigType" SG_ 2565867041 DiffLockStateRearAxle1 4;
BA_ "SPN" SG_ 2565867041 DiffLock1 568;
BA_ "SigType" SG_ 2565867041 DiffLock1 4;
BA_ "GenSigStartValue" SG_ 2565867041 DiffLock1 3;
BA_ "SPN" SG_ 2565867041 DiffLock2 567;
BA_ "SigType" SG_ 2565867041 DiffLock2 4;
BA_ "GenSigStartValue" SG_ 2565867041 DiffLock2 3;
BA_ "SPN" SG_ 2565867041 Location 927;
BA_ "SigType" SG_ 2565867041 Location 1;
BA_ "GenSigStartValue" SG_ 2565867041 Location 255;
BA_ "GenSigStartValue" SG_ 2564816929 Outside_Air_Temp_Stat_Climate 254;
BA_ "SPN" SG_ 2564816929 CabIntTempComStatus 1691;
BA_ "SigType" SG_ 2564816929 CabIntTempComStatus 1;
VAL_ 2566843648 SpeedLimitsExceedStatus 7 "Reserved " 6 "Reserved " 5 "Reserved " 4 "Reserved " 3 "ASLD  speed limit exceed" 2 "PCC upper speed limit exceed" 1 "Cruise control set speed exceed" 0 "No exceed" ;
VAL_ 2566843648 ASLD_States 7 "Not available" 6 "Reserved" 5 "Reserved" 4 "Exceeding Limit" 3 "Accelerator Override" 2 "Active" 1 "Standby" 0 "Off / Disabled" ;
VAL_ 2566708224 AdaptCCReadinessStt 3 "Not available" 2 "Error" 1 "On" 0 "Off" ;
VAL_ 2365512010 Audio_Mute 3 "Manual Emergency Call Mute" 2 "Automatic Emergency Call Mute" 1 "Emergency Call Unmute" 0 "Null" ;
VAL_ 2349465642 CruiseControlPauseCommand 3 "Dont Care" 2 "Reserved" 1 "Cruise Control Not Allowed" 0 "Cruise Control Allowed" ;
VAL_ 2349465642 CruiseControlDisableCommand 3 "Dont Care" 2 "Reserved" 1 "Cruise Control Not Allowed" 0 "Cruise Control Allowed" ;
VAL_ 2432593706 ForwardCollisionWarning 3 "notAvailable" 2 "ErrorIndicator" 1 "CollisionIsImminent" 0 "NoWarning" ;
VAL_ 2432593706 ACCDistanceAlertSignal 3 "TakeNoAction" 2 "Reserved" 1 "ACCDASActive" 0 "ACCDASNotActive" ;
VAL_ 2432593706 ACCSystemShutoffWarning 3 "TakeNoAction" 2 "Reserved" 1 "ACCSSOWActive" 0 "ACCSSOWNotActive" ;
VAL_ 2432593706 ACCTargetDetected 3 "TakeNoAction" 2 "Reserved" 1 "TargetDetected" 0 "NoTargetsDetected" ;
VAL_ 2432593706 AdptveCruiseCtrlSetDistanceMode 7 "NotAvailable_NotValid" 6 "ErrorCondition" 5 "ConventionalCruiseCtrlMode" 4 "ACCDistanceMode5" 3 "ACCDistanceMode4" 2 "ACCDistanceMode3" 1 "ACCDistanceMode2" 0 "ACCDistanceMode1" ;
VAL_ 2432593706 AdaptiveCruiseCtrlMode 7 "NotAvailable_NotValid" 6 "DsbldErrrCndtnUsdTIndctThtACCIs" 5 "FinishMode" 4 "HldMdUsdTIndctThtACCHsLstThPrvs" 3 "OvertakeMode" 2 "DstncCtrlActvUsdTIndctThtACCIsO" 1 "SpeedCtrlActive" 0 "OffUsdTIndctACCIsEnbldInClbCnfg" ;
VAL_ 2566799393 Dimming_Lvl_VCAN 255 "Invalid" 254 "Unknown" 18 "Day6" 17 "Day5" 16 "Day4" 15 "Day3" 14 "Day2" 13 "Day1" 12 "Night12" 11 "Night11" 10 "Night10" 9 "Night9" 8 "Night8" 7 "Night7" 6 "Night6" 5 "Night5" 4 "Night4" 3 "Night3" 2 "Night2" 1 "Night1" 0 "Off" ;
VAL_ 2566799393 Litval_VCAN 255 "Invalid" 254 "Unknown" 5 "Day" 4 "Twilight4" 3 "Twilight3" 2 "Twilight2" 1 "Twilight1" 0 "Night" ;
VAL_ 2566799393 Day_Night_Status_VCAN 3 "Not Used" 2 "Night" 1 "Day" 0 "Null" ;
VAL_ 2566799393 ParkLamp_Status_VCAN 3 "Invalid" 2 "Unknown" 1 "On" 0 "Off" ;
VAL_ 2566799393 FrontFogLight 3 "NotAvailable" 2 "Error" 1 "Activated" 0 "Deactivated" ;
VAL_ 2566799393 RearFogLight 3 "NotAvailable" 2 "Error" 1 "Activated" 0 "Deactivated" ;
VAL_ 2566799393 SideMarkerPositionLamp 3 "NotAvailable" 2 "Error" 1 "Activated" 0 "Deactivated" ;
VAL_ 2566799393 HomeSafeLightChime 3 "NotAvailable" 2 "Error" 1 "Activated" 0 "Deactivated" ;
VAL_ 2566799393 HighBeam 3 "NotAvailable" 2 "Error" 1 "Activated" 0 "Deactivated" ;
VAL_ 2566799393 LowBeam 3 "NotAvailable" 2 "Error" 1 "Activated" 0 "Deactivated" ;
VAL_ 2566838561 LaneDepartureWarningEnable 3 "NA" 2 "Error" 1 "Enable Lane Departure Warning" 0 "Disable Lane Departure Warning" ;
VAL_ 2566838561 DrvActDemandAdvEmergBrake 3 "don’t care / take no action" 2 "error" 1 "no deactivation of AEBS" 0 "deactivation of AEBS" ;
VAL_ 2566838561 Ignition_Status_VCAN 15 "Invalid" 8 "Start" 4 "Run" 2 "Accessory" 1 "Off" 0 "Unknown" ;
VAL_ 2566838561 AirDistributionMode 6 "Windshield & Panel & Foot" 15 "Not available" 14 "Error" 5 "Panel & Foot" 4 "Windshield & Foot" 3 "Windshield & Panel" 2 "Foot" 1 "Panel" 0 "Windshield" ;
VAL_ 2566838561 TrailerABSEBSFault 3 "Not available" 2 "Error" 1 "Active" 0 "Deactive" ;
VAL_ 2566838561 SteWhlSwtchMenu_B_Stat 1 "Active" 0 "Deactive" ;
VAL_ 2566838561 SteWhlSwtchBack_B_Stat 1 "Active" 0 "Deactive" ;
VAL_ 2566838561 SteWhlSwtchUp_B_Stat 1 "Active" 0 "Deactive" ;
VAL_ 2566838561 SteWhlSwtchOk_B_Stat 1 "Active" 0 "Deactive" ;
VAL_ 2566838561 SteWhlSwtchDown_B_Stat 1 "Active" 0 "Deactive" ;
VAL_ 2566838561 ManeuveringMode 3 "Take no action" 2 "Reserved" 1 "Enable" 0 "Disable" ;
VAL_ 2566838561 PowerMode_BCM 3 "Takenoaction" 2 "Reserve" 1 "Enable" 0 "Disable" ;
VAL_ 2566838561 OffRoadMode_BCM 3 "Takenoaction" 2 "Reserve" 1 "Enable" 0 "Disable" ;
VAL_ 2566838561 RockingMode_BCM 3 "Takenoaction" 2 "Reserve" 1 "Enable" 0 "Disable" ;
VAL_ 2566838561 RollingMode_BCM 3 "Takenoaction" 2 "Reserve" 1 "Enable" 0 "Disable" ;
VAL_ 2566838561 RqedACCDistanceMode 7 "notAvailable" 6 "errorCondition" 5 "notDefined" 4 "RqedACCDistanceMode5" 3 "RqedACCDistanceMode4" 2 "RqedACCDistanceMode3" 1 "RqedACCDistanceMode2" 0 "RqedACCDistanceMode1" ;
VAL_ 2566838561 AuxI_O08_GearboxNeutralPos_AUX1 3 "NotAvailable" 2 "Error" 1 "SecuredNeutralPosition" 0 "NotInSecuredNeutralPosition" ;
VAL_ 2566838561 AuxI_O07_TrailerABSFulOper_AUX1 3 "NotAvailable" 2 "Error" 1 "TrailerABSFullyOperational" 0 "TrailerABSNotFullyOperational" ;
VAL_ 2566838561 AuxI_O06_TrailerABSDetected_AUX1 3 "NotAvailable" 2 "Error" 1 "TrailerABSDetected" 0 "TrailerABSNotDetected" ;
VAL_ 2566838561 AuxI_O05_TrailerConnected_AUX1 3 "NotAvailable" 1 "TrailerConnected" 0 "TrailerNotConnected" ;
VAL_ 2566838561 PassengerDoorStatus 3 "NotAvailable" 2 "Error" 1 "Passenger Door Open" 0 "Passenger Door Closed" ;
VAL_ 2566838561 DriverDoorStatus 3 "NotAvailable" 2 "Error" 1 "Driver Door Open" 0 "Driver Door Closed" ;
VAL_ 2566827774 AirCompressorStatus 3 "NotAvailable" 2 "ErrorIndicator" 1 "CompressorActive" 0 "CompressorNotActive" ;
VAL_ 2565668394 PGNumber 255 "NotAvailable" ;
VAL_ 2565668394 ControlByte 24 "EAbort" 23 "EEoMACK" 22 "EDPO" 21 "ECTS" 20 "ERTS" 255 "Abort" 32 "BAM" 19 "EoMA" 17 "CTS" 16 "RTS" ;
VAL_ 2565668840 PGNumber 255 "NotAvailable" ;
VAL_ 2565668840 ControlByte 24 "EAbort" 23 "EEoMACK" 22 "EDPO" 21 "ECTS" 20 "ERTS" 255 "Abort" 32 "BAM" 19 "EoMA" 17 "CTS" 16 "RTS" ;
VAL_ 2565919516 Data_Services_Status 3 "Reserved" 2 "On" 1 "Off" 0 "No command" ;
VAL_ 2565919516 Location_Status 3 "Reserved" 2 "On" 1 "Off" 0 "No command" ;
VAL_ 2565919516 ConnectionStatusforTelltale 3 "Reserved" 2 "Sharing Data & Location" 1 "Sharing Just Data" 0 "Off" ;
VAL_ 2565919516 Connectivity_HMI_Enable 3 "Reserved" 2 "Connectivity Enabled" 1 "Connectivity Disabled" 0 "No Command" ;
VAL_ 2565919516 PreCru_Ctrl_State 2 "Predictive Cruise Control Error" 1 "Predictive Cruise Control On" 0 "Predictive Cruise Control Off" ;
VAL_ 2566848540 WebServicesGroup1 15 "Reserved" 14 "Reserved" 13 "Reserved" 12 "Reserved" 11 "Reserved" 10 "Reserved" 9 "Reserved" 8 "Reserved" 7 "Flash successful" 6 "Parameters not restored" 5 "Ignition off on " 4 "Programming error" 3 "Server dwnld error" 2 "Server comms error" 1 "Conditions not satisfied" 0 "Default No Show" ;
VAL_ 2566848540 TransmissionRequestedGear 252 "Forward Drive Position" 249 "Upshift 1 gear" 248 "Upshift 2 gears" 247 "Downshift 1 gear" 246 "Downshift 2 gears " 231 "Toggle btw Auto and Man" 228 "Forward Manv" 224 "No Command" 222 "Neutral Gear" 28 "Reverse Manv" 255 "Not Available" 254 "Error" 223 "Reverse Selector Position" ;
VAL_ 2631728651 AntitheftComponentStatusStates 3 "NotDefined" 2 "BlckdThsSttIndctsThtALckUnlckCm" 1 "LckdThsSttIndctsThtCmpnntCnNOTB" 0 "UnlckdThsSttIndctsThtCmpnntCnBS" ;
VAL_ 2631728651 AntthftEncryptnSdPrsntIndicator 3 "NotAvailable" 2 "Error" 1 "RandomNumberIsPresent" 0 "RandomNumberIsNotPresent" ;
VAL_ 2631728651 AntitheftPwdValidIndicator 3 "NotAvailable" 2 "Error" 1 "PwdIsAValidatedPassword" 0 "PwdIsNotAValidatedPassword" ;
VAL_ 2631794218 AntthftEncryptonIndicatorStates 3 "NtAvlblThsSttIsUsdTIndctThtARnd" 2 "NotDefined" 1 "EncryptdCdPrsntThsSttIsUsdTIndc" 0 "EncryptnSdRqThsSttRprsntsARqstT" ;
VAL_ 2631794218 AntitheftCmdStates 7 "Not Defined" 6 "NotDefined" 5 "Login" 4 "ChckSttsThsSttRprsntsARqTChckTS" 3 "LockorUnlock" 2 "ChngPwdThsSttRprsntsARqTCmpnntT" 1 "DeletePwd" 0 "AddPwdThsSttRprsntsARqTCmpnntTA" ;
VAL_ 2565865214 MotorControllerPowerHoldCommand 3 "NotUsed" 2 "Reversed" 1 "PowerOn" 0 "PowerOff" ;
VAL_ 2565865214 MotorOnOffDirectionCommand 3 "Invalid" 2 "MotorOn:ReverseDirection" 1 "MotorOn:Normal/DefaultDirection" 0 "MotorOff" ;
VAL_ 2566811651 DirectorIndicator 3 "NotAvailable" 2 "Error" 1 "Reverse" 0 "Forward" ;
VAL_ 2565668619 PGNumber 255 "NotAvailable" ;
VAL_ 2565668619 ControlByte 24 "EAbort" 23 "EEoMACK" 22 "EDPO" 21 "ECTS" 20 "ERTS" 255 "Abort" 32 "BAM" 19 "EoMA" 17 "CTS" 16 "RTS" ;
VAL_ 2566870526 Hand_Lever_Signals_PROP_IT3_BCM 31 "Position 4" 15 "Position 3" 7 "Position 2" 3 "Position 1" 1 "Position 0" ;
VAL_ 2566834920 FailureModeIdentifier1_Camera 31 "Not available" 19 "Received network data in error" 18 "Below normal (moderately severe)" 17 "Below normal (least severe)" 16 "Above normal (moderately severe)" 15 "Above normal (least severe)" 14 "Special intstructions" 13 "Out of calibration" 12 "Bad intelligent device" 11 "Root cause not known" 10 "Abnormal rate of change" 9 "Abnormal update rate" 8 "Abnormal frequency" 7 "Mechanical system not responding" 6 "Current above normal" 5 "Current below normal" 4 "Voltage below normal" 3 "Voltage above normal" 2 "Data erratic" 1 "Below normal (most severe)" 0 "Above normal (most severe)" ;
VAL_ 2566834920 AmberWarningLampStatus_Camera 3 "Not available" 2 "Reserved" 1 "Lamp on" 0 "Lamp off" ;
VAL_ 2566834730 FailureModeIdentifier1_Radar 31 "Not available" 19 "Received network data in error" 18 "Below normal (moderately severe)" 17 "Below normal (least severe)" 16 "Above normal (moderately severe)" 15 "Above normal (least severe)" 14 "Special intstructions" 13 "Out of calibration" 12 "Bad intelligent device" 11 "Root cause not known" 10 "Abnormal rate of change" 9 "Abnormal update rate" 8 "Abnormal frequency" 7 "Mechanical system not responding" 6 "Current above normal" 5 "Current below normal" 4 "Voltage below normal" 3 "Voltage above normal" 2 "Data erratic" 1 "Below normal (most severe)" 0 "Above normal (most severe)" ;
VAL_ 2566834730 AmberWarningLampStatus_Radar 3 "Not available" 2 "Reserved" 1 "Lamp on" 0 "Lamp off" ;
VAL_ 2566759427 PTO1EngagementStatus 3 "NA" 2 "Error" 1 "Active" 0 "NotActive" ;
VAL_ 2348875776 TransMode1 3 "Take No Action" 2 "Reserved" 1 "Enable" 0 "Disable" ;
VAL_ 2348875776 TransRollModeEnSignal 3 "N/A(Default: disable)" 2 "N/A(Default: disable)" 1 "Rolling Enable" 0 "Rolling Disable" ;
VAL_ 2348875776 TransmissionRequestedGear 252 "Forward Drive Position" 249 "Upshift 1 gear" 248 "Upshift 2 gears" 247 "Downshift 1 gear" 246 "Downshift 2 gears " 231 "Toggle btw Auto and Man" 228 "Forward Manv" 224 "No Command" 222 "Neutral Gear" 28 "Reverse Manv" 255 "Not Available" 254 "Error" 223 "Reverse Selector Position" ;
VAL_ 2566722593 BatteryRefresh 1 "active" 0 "passive" ;
VAL_ 2566722849 ChargeMode 15 "Error" 14 "Mode 14" 13 "Mode 13" 12 "Mode 12" 11 "Mode 11" 10 "Mode 10" 9 "Mode 9" 8 "Mode 8" 7 "Mode 7" 6 "Mode 6" 5 "Mode 5" 4 "Mode 4" 3 "Mode 3" 2 "Mode 2" 1 "Mode 1" 0 "Mode 0" ;
VAL_ 2566722849 FlagSetWhenBattDischisAllowable 3 "Not Available" 2 "Error" 1 "Flag set" 0 "Flag not set" ;
VAL_ 2566722849 FlagSetWhenRegenModeisAllowable 3 "Not Available" 2 "Error" 1 "Flag set" 0 "Flag not set" ;
VAL_ 2566722849 FlagSetWhenBMSisHealthy 3 "Not Available" 2 "Error" 1 "Flag set" 0 "Flag not set" ;
VAL_ 2566879486 AxleState 3 "SelfSteer and TagAxle lifted" 2 "Tag axle lifted" 1 "Self steer axle lifted" 0 "SelfSteer and TagAxle not lifted" ;
VAL_ 2566879486 Warning 65 "parking brake is engaged " 17 "Failure Mode is detected" 9 "axle is overloaded" 5 "speedisover30kphduringaxlelift" 3 "Lift/Drop Other axle first" 0 "no warning is active" ;
VAL_ 2566879486 Action 99 "Tag axle can’t be lifted" 77 "Self-steer can’t be lifted" 66 "Self-steer can’t be dropped" 44 "Tag axle is being dropped" 22 "Self-steer is being dropped" 10 "Tag axle can’t be dropped" 9 "Tag axle can’t be lifted" 8 "Tag axle can’t be lifted" 7 "Self-steer can’t be lifted" 6 "Self-steer can’t be dropped " 5 "Self-steer can’t be dropped" 4 "Tag axle is being dropped" 3 "Tag axle is being lifted SSisup" 2 "SSisbeingdrped/AutoDropFunc" 1 "Self-steer is being lifted " 0 "No action is occurred " ;
VAL_ 2566851105 Critical_SOC 3 "NotAvailable" 2 "Error" 1 "Critical" 0 "OK" ;
VAL_ 2566851105 AlternatorStatus 3 "NotAvailable" 2 "Error" 1 "Alternator Charging" 0 "Alternator Not charging" ;
VAL_ 2566851105 BatterySoHWarning 3 "NotAvailable" 2 "Error" 1 "SoH Warning Active" 0 "SoH Warning Inactive" ;
VAL_ 2566851105 BatteryService 3 "NotAvailable" 2 "Error" 1 "BatteryServiceNeeded" 0 "BatteryServiceNotNeeded" ;
VAL_ 2566843134 AxleLocation 48 "Axle3_Position0" 32 "Axle2_Position0" 16 "Axle1_Position0" 0 "Axle0_Position0" ;
VAL_ 2365479678 SpeedDependantLevelCtrlStatus 3 "DonTCare_TakeNoAction" 2 "Reserved" 1 "Active" 0 "Inactive" ;
VAL_ 2365479678 MemoryLevel 15 "NotAvailable" 14 "ErrorIndicator" 13 "MemoryLevel5Stored" 12 "MemoryLevel4Stored" 11 "MemoryLevel3Stored" 10 "MemoryLevel2Stored" 9 "MemoryLevel1Stored" 8 "Reserved" 5 "MemoryLevel5Selected" 4 "MemoryLevel4Selected" 3 "MemoryLevel3Selected" 2 "MemoryLevel2Selected" 1 "MemoryLevel1Selected" 0 "NoMemoryLevel" ;
VAL_ 2365479678 AllwLvelCtrlDuringBrakingStatus 3 "DonTCare_TakeNoAction" 2 "Reserved" 1 "Activate" 0 "Deactivate" ;
VAL_ 2365479678 SspensionCtrlRefusalInformation 15 "NotAvailable" 14 "Error" 8 "1101NotDefined" 7 "RqedLevelNotAvailable" 6 "GnrlRjctINSpcifiedReasonApplies" 5 "BelowSpeedLimit" 4 "AboveSpeedLimit" 3 "BogieDiffNotLocked" 2 "WouldExceedAxleLoadLimit" 1 "AxleLoadLimitReached" 0 "ActualRqNotRefused" ;
VAL_ 2365479678 SuspensionRemoteCtrl2 3 "NotAvailable" 2 "Error" 1 "Active" 0 "NotActive" ;
VAL_ 2365479678 SuspensionRemoteCtrl1 3 "NotAvailable" 2 "Error" 1 "Active" 0 "NotActive" ;
VAL_ 2365479678 RearAxleInBumperRange 3 "NotAvailable" 2 "Error" 1 "ActualLevelWithinBumperRange" 0 "ActualLevelOutOfBumperRange" ;
VAL_ 2365479678 FrontAxleInBumperRange 3 "NotAvailable" 2 "Error" 1 "ActualLevelWithinBumperRange" 0 "ActualLevelOutOfBumperRange" ;
VAL_ 2365479678 DoorRelease 3 "NotAvailable" 2 "Error" 1 "DoorsMayBeOpened" 0 "DoorsMayNotBeOpened" ;
VAL_ 2365479678 VehicleMotionInhibit 3 "NotAvailable" 2 "Error" 1 "VehicleMotionIsInhibited" 0 "VehicleMayBeMoved" ;
VAL_ 2365479678 SecurityDevice 3 "NotAvailable" 2 "Error" 1 "Active" 0 "NotActive" ;
VAL_ 2365479678 LevelCtrlMode 11 "1101NotDefined" 10 "AtmtcArSuspensionCtrlProhibited" 15 "NotAvailable" 14 "Error" 9 "AirSuspensionCtrlProhibited" 8 "ExhstngBllwFnctnIBllwsArExhstdT" 7 "TractionHelpLoadReduce" 6 "OptmmTrctn2IPrssAtThDrvnAxlIsCt" 5 "OptmmTrctn1IPrssAtThDrvnAxlIsCt" 4 "PrssRt2IRtBtwnThPrssrsAtThDrvnA" 3 "PrssRt1IRtBtwnThPrssrsAtThDrvnA" 2 "LdFxngIDrvnAxlnIsLddTAVlDfndByT" 1 "TrctnHlpIDrvnAxlIsLddTAMxVlGvnB" 0 "NrmlOprtnISystmPrfrmsAPrCtrlOfT" ;
VAL_ 2365479678 KneelingInformation 15 "NotAvailable" 14 "Error" 5 "1101NotDefined" 4 "KneelingAborted" 3 "LiftingActive" 2 "KneelingLevelReached" 0 "NotActive" ;
VAL_ 2365479678 LiftingCtrlModeRearAxle 3 "NotAvailable" 2 "Error" 1 "LiftingActive" 0 "LiftingNotActive" ;
VAL_ 2365479678 LiftingCtrlModeFrontAxle 3 "NotAvailable" 2 "Error" 1 "LiftingActive" 0 "LiftingNotActive" ;
VAL_ 2365479678 LoweringCtrlModeRearAxle 3 "NotAvailable" 2 "Error" 1 "LoweringActive" 0 "LoweringNotActive" ;
VAL_ 2365479678 LoweringCtrlModeFrontAxle 3 "NotAvailable" 2 "Error" 1 "LoweringActive" 0 "LoweringNotActive" ;
VAL_ 2365479678 AboveNominalLevelRearAxle 3 "NotAvailable" 2 "Error" 1 "Above" 0 "NotAbove" ;
VAL_ 2365479678 AboveNominalLevelFrontAxle 3 "NotAvailable" 2 "Error" 1 "Above" 0 "NotAbove" ;
VAL_ 2365479678 BelowNominalLevelRearAxle 3 "NotAvailable" 2 "Error" 1 "Below" 0 "NotBelow" ;
VAL_ 2365479678 BelowNominalLevelFrontAxle 3 "NotAvailable" 2 "Error" 1 "Below" 0 "NotBelow" ;
VAL_ 2365479678 NominalLevelRearAxle 9 "Raising" 11 "1101NotDefined" 10 "Lowering" 15 "NotAvailable" 14 "Error" 8 "NotDefined" 7 "LowerLevel" 6 "UpperLevel" 5 "CustomerLevel" 4 "PresetLevel" 3 "NormalLevel3" 2 "NormalLevel2" 1 "NormalLevel1" 0 "LevelNotSpecified" ;
VAL_ 2365479678 NominalLevelFrontAxle 9 "Raising" 11 "1101NotDefined" 10 "Lowering" 15 "NotAvailable" 14 "Error" 8 "NotDefined" 7 "LowerLevel" 6 "UpperLevel" 5 "CustomerLevel" 4 "PresetLevel" 3 "NormalLevel3" 2 "NormalLevel2" 1 "NormalLevel1" 0 "LevelNotSpecified" ;
VAL_ 2365479678 LiftAxle2Pos 3 "NotAvailable" 2 "Error" 1 "LiftAxlePosUp_TagAxleUnladen" 0 "LiftAxlePosDown_TagAxleLaden" ;
VAL_ 2365479678 LiftAxle1Pos 3 "NotAvailable" 2 "Error" 1 "LiftAxlePosUp_TagAxleUnladen" 0 "LiftAxlePosDown_TagAxleLaden" ;
VAL_ 2566759457 PTOEngagementStatus 3 "NotAvailable" 2 "Error" 1 "Active" 0 "NotActive" ;
VAL_ 2566759457 EnableSwitchStatus 3 "NotAvailable" 2 "Error" 1 "Active" 0 "NotActive" ;
VAL_ 2566910462 LearnStatus 1 "Failure" 0 "NoFailure" ;
VAL_ 2566910462 EOLLearnFailureStatus 1 "Failure" 0 "NoFailure" ;
VAL_ 2566910462 InternalElectrclFaultStatus 1 "Failure" 0 "NoFailure" ;
VAL_ 2566910462 CANErrorStatus 1 "Failure" 0 "NoFailure" ;
VAL_ 2566910462 IgnitionVoltageFaultStatus 1 "Failure" 0 "NoFailure" ;
VAL_ 2566910462 SpanLearnFailStatus 1 "Failure" 0 "NoFailure" ;
VAL_ 2566910462 ObstructionStatus 1 "Failure" 0 "NoFailure" ;
VAL_ 2566910462 TempWarningStatus 1 "Failure" 0 "NoFailure" ;
VAL_ 2566910462 TemperatureFaultStatus 1 "Failure" 0 "NoFailure" ;
VAL_ 2566905342 StrokeCheckState_EGR 1 "Failure" 0 "NoFailure" ;
VAL_ 2566905342 StrokeCheckFailure_EGR 1 "Failure" 0 "NoFailure" ;
VAL_ 2566905342 ThermistorFailure 1 "Failure" 0 "NoFailure" ;
VAL_ 2566905342 InitializFailure 1 "Failure" 0 "NoFailure" ;
VAL_ 2566905342 EEPROMFailure 1 "Failure" 0 "NoFailure" ;
VAL_ 2566905342 CANCommFailure 1 "Failure" 0 "NoFailure" ;
VAL_ 2566905342 PositionSensorFailure 1 "Failure" 0 "NoFailure" ;
VAL_ 2566905342 MotorCoilOpen 1 "Failure" 0 "NoFailure" ;
VAL_ 2566905342 OverCurrentFailure 1 "Failure" 0 "NoFailure" ;
VAL_ 2566905342 PowerSupplyLowVoltage 1 "Failure" 0 "NoFailure" ;
VAL_ 2566905342 PowerSupplyHighVoltage 1 "Failure" 0 "NoFailure" ;
VAL_ 2566905342 FeedbackFailure 1 "Failure" 0 "NoFailure" ;
VAL_ 2566905086 StrokeCheckRequest_EGR 1 "Failure" 0 "NoFailure" ;
VAL_ 2566841344 EngineOperationMode 15 "Not available" 14 "error" 8 "Mode 8" 7 "Mode 7" 6 "Mode 6" 5 "Mode 5" 4 "Mode 4" 3 "Mode 3" 2 "Mode 2" 1 "Mode 1" 0 "Mode 0" ;
VAL_ 2566841344 EngOverspeedTest 3 "NotAvailable" 2 "Reserved" 1 "EngOverspeedTestActive" 0 "EngOverspeedTestNotActive" ;
VAL_ 2566841344 EngAirShutoffCmdStatus 0 "ArShtffDsbldNtAttmptngTShtffEng" 3 "NotAvailable" 2 "Reserved" 1 "ArShtffEnbldAttmptngTShtffEngAr" ;
VAL_ 2566841344 EngAlarmOutputCmdStatus 3 "NotAvailable" 2 "Reserved" 1 "EngAlarmOutputCmdActive" 0 "EngAlarmOutputCmdNotActive" ;
VAL_ 2566841344 EngAlarmAcknowledge 3 "NotAvailable" 2 "Error" 1 "EngAlarmAcknowledgeActive" 0 "EngAlarmAcknowledgeNotActive" ;
VAL_ 2566841344 EngProtectionSystemConfig 3 "NotAvailable" 2 "Error" 1 "EnabledInCalib" 0 "DisabledInCalib" ;
VAL_ 2566841344 EngProtectionSystemTimerState 3 "NotAvailable" 2 "Error" 1 "Active" 0 "Inactive" ;
VAL_ 2566841344 EngPrtectionSystemTimerOverride 3 "NotAvailable" 2 "Error" 1 "Active" 0 "Inactive" ;
VAL_ 2566841344 EngPrtctnSystmApprchingShutdown 3 "NotAvailable" 2 "Error" 1 "Approaching" 0 "NotApproaching" ;
VAL_ 2566841344 EngWaitToStartLamp 3 "NotAvailable" 2 "Error" 1 "On" 0 "Off" ;
VAL_ 2566841344 RefrigerantHighPressSwitch 3 "NotAvailable" 2 "Error" 1 "PrssTHghCmprssrCltchMyBDsngaged" 0 "PressNormal" ;
VAL_ 2566841344 RefrigerantLowPressSwitch 3 "NotAvailable" 2 "Error" 1 "PrssTLwCmprssrCltchMyBDsengaged" 0 "PressNormal" ;
VAL_ 2566841344 A_CHighPressFanSwitch 3 "NotAvailable" 2 "Error" 1 "PressHighFanMayBeEngaged" 0 "PressNormal" ;
VAL_ 2566841344 EngIdleShutdownTimerFunction 3 "NotAvailable" 2 "Error" 1 "EnabledInCalib" 0 "DisabledInCalib" ;
VAL_ 2566841344 EngIdleShutdownTimerState 3 "NotAvailable" 2 "Error" 1 "Active" 0 "Inactive" ;
VAL_ 2566841344 EngIdleShutdownTimerOverride 3 "NotAvailable" 2 "Error" 1 "Active" 0 "Inactive" ;
VAL_ 2566841344 EngIdleShutdownDriverAlertMode 3 "NotAvailable" 2 "Error" 1 "Active" 0 "Inactive" ;
VAL_ 2566841344 PTOShutdownHasShutdownEng 3 "NotAvailable" 2 "Error" 1 "Yes" 0 "No" ;
VAL_ 2566841344 EngPrtctnSystmHasShutdownEngine 3 "NotAvailable" 2 "Error" 1 "Yes" 0 "No" ;
VAL_ 2566841344 EngIdlShutdownHasShutdownEngine 3 "NotAvailable" 2 "Error" 1 "Yes" 0 "No" ;
VAL_ 2566841344 EngAirShutoffStatus 3 "NotAvailable" 2 "Error" 1 "AirFlowRestricted" 0 "AirFlowAllowedToEng" ;
VAL_ 2566848256 OLSTextWarnMssg 3 "Description for the value '0x3'" 2 "Error" 1 "Text warning enabled" 0 "Text warning disabled" ;
VAL_ 2566848256 LowOilindicatorStatus 4 "Overfill warning" 3 "Not defined" 2 "Low oil warning" 1 "Critical Low Oil level" 0 "Oil Level OK" ;
VAL_ 2566848256 OilChangeWarningIndicator 3 "Error State (Blink @ 2Hz)" 2 "Lamp On (Blinking @ 1 Hz)" 1 "Lamp On (Continuous) " 0 "Lamp Off" ;
VAL_ 2566848256 EngineFuelFilterRestrictionLam 3 "NA" 2 "NA" 1 "Lamp On" 0 "Lamp Off" ;
VAL_ 2566848256 ClutchProtectionBuzzer 3 "Error" 2 "Blinking Buzzer" 1 "Continuous Buzzer" 0 "No Buzzer" ;
VAL_ 2566848256 ClutchProtectionWarning 3 "Error" 2 "Blinking clutch warning lamp" 1 "Continuous clutch warning lamp" 0 "No warning" ;
VAL_ 2566848256 TamperingFaultsBlockedEGR 1 "Critical Emissions Failure" 0 "No warning" ;
VAL_ 2566848256 AdblueConsDosingInterr 1 "AdBlue Dosing Malfunction" 0 "No warning" ;
VAL_ 2566848256 WaterInFuelIndicator 3 "NotAvailable" 2 "Error" 1 "Yes" 0 "No" ;
VAL_ 2566831360 FanDriveState 15 "NotAvailable" 14 "Other" 13 "EngBrake" 12 "Timer" 11 "A_CSystem" 10 "TransRetarder" 9 "ManualCtrl" 8 "ReverseOperation" 7 "DefaultOperation" 6 "ExcessiveHydOilTemp" 5 "ExcessiveTransOilTemp" 4 "ExcessiveEngCoolantTemp" 3 "ExcessiveEngOilTemp" 2 "ExcessiveEngAirTemp" 1 "EngSystemGeneral" 0 "FanOff" ;
VAL_ 2566841088 SupportTSC1CtrlPurposeGroup4 1 "P25ReservedForAssignmentBySAE" ;
VAL_ 2566841088 SupportTSC1CtrlPurposeGroup3 1 "P17ReservedForAssignmentBySAE" ;
VAL_ 2566841088 SupportTSC1CtrlPurposeGroup2 1 "P9ReservedForAssignmentBySAE" ;
VAL_ 2566841088 SupportTSC1CtrlPurposeGroup1 1 "P1AccelPedal_OperatorSelection" ;
VAL_ 2566841088 SupportVariableRateTSC1Message 1 "MsTransRate" ;
VAL_ 2566840064 Aftertreatment2IntakeDewPoint 3 "NotAvailable" 2 "Error" 1 "ExceededDewPoint" 0 "NotExceededDewPoint" ;
VAL_ 2566840064 Aftertreatment2ExhaustDewPoint 3 "NotAvailable" 2 "Error" 1 "ExceededDewPoint" 0 "NotExceededDewPoint" ;
VAL_ 2566840064 Aftertreatment1IntakeDewPoint 3 "NotAvailable" 2 "Error" 1 "ExceededDewPoint" 0 "NotExceededDewPoint" ;
VAL_ 2566840064 Aftertreatment1ExhaustDewPoint 3 "NotAvailable" 2 "Error" 1 "ExceededDewPoint" 0 "NotExceededDewPoint" ;
VAL_ 2566840064 EstEngPrsticLossesPercentTorque 251 "LossesAreIncludedInSPN514" ;
VAL_ 2364539648 VhclAccelerationRateLimitStatus 3 "NotAvailable" 2 "Reserved" 1 "LimitActive" 0 "LimitNotActive" ;
VAL_ 2364539648 GearShiftIndication 3 "NotAvailable" 2 "Error" 1 "GearShiftTelltaleOn" 0 "GearShiftTelltaleOff" ;
VAL_ 2364539648 RoadSpeedLimitStatus 3 "NotAvailable" 2 "Error" 1 "NotActive" 0 "Active" ;
VAL_ 2364539648 AccelPedalKickdownSwitch 3 "NotAvailable" 2 "Error" 1 "KickdownActive" 0 "KickdownPassive" ;
VAL_ 2364539648 AccelPedal1LowIdleSwitch 3 "NotAvailable" 2 "Error" 1 "AccelPedal1InLowIdleCondition" 0 "AcclPedal1NotInLowIdleCondition" ;
VAL_ 2364539904 SrcAddrssOfCtrllngDvcFrEngCntrl 5 "Description for the value '0x5'" 4 "GearBoxControlstheEngineTorque" 3 "PTOcontrolstheEngineTorque" 2 "RetarderControlstheEngineTorque" 1 "ABS/ASRcontrolstheenginetorque" 0 "EDCcontrolsTheEngineTorque" ;
VAL_ 2364539904 ActlEngPrcntTrqueHighResolution 8 "1111NotAvailable" 7 "0875" 1 "0125" 0 "0000" ;
VAL_ 2364539904 EngStarterMode 15 "notAvailable" 14 "error" 12 "starterInhibitedReasonUnknown" 7 "strtrInhbtdDToActiveImmobilizer" 6 "strtrInhbtdDTDrvlnEnggdOthrTrns" 5 "strtrInhbtdDTEngNtReadyForStart" 4 "strtrInhbtdDToEngAlreadyRunning" 3 "strtFnshd" 2 "starterActiveGearEngaged" 1 "starterActiveGearNotEngaged" 0 "startNotRqed" ;
VAL_ 2364539904 EngTorqueMode 15 "NotUsed" 14 "VCU/PTOTorqueControl/limit" 13 "VCU/PTOTorqueControl/limit" 12 "TorqueLimitationBecasueofFuelLmt" 11 "Notused" 10 "EngineRetarderControl" 9 "HighSpeedGovernor" 8 "TorqueLimiter(NoFuelLimitation)" 7 "ABSControl" 6 "TransmissionControl" 5 "ASRControl" 4 "RoadSpeedLimiter" 3 "PTOactivebyMSSorMFlv" 2 "CruiseControl(w/positiveTorque)" 1 "AcceleratorPedalGovernorActive" 0 "Idling(Default)" ;
VAL_ 2566844672 PTOGovernorState_CCVS_ECM 31 "NotAvailable" 20 "11110NotDefined" 19 "PTOSetSpeedMemory2" 18 "PTOSetSpeedMemory1" 17 "PreprogrammedSetSpeed8" 16 "PreprogrammedSetSpeed7" 15 "PreprogrammedSetSpeed6" 14 "PreprogrammedSetSpeed5" 13 "PreprogrammedSetSpeed4" 12 "PreprogrammedSetSpeed3" 11 "PreprogrammedSetSpeed2" 10 "PreprogrammedSetSpeed1" 9 "AccelOverride" 8 "Accelerate" 7 "Resume" 6 "Decelerate_Coast" 5 "Set" 4 "RemoteStandby" 3 "Standby" 2 "RemoteHold" 1 "Hold" 0 "Off_Disabled" ;
VAL_ 2566844672 EngShutdownOverrideSwitch 3 "NotAvailable" 2 "Error" 1 "On" 0 "Off" ;
VAL_ 2566844672 EngTestModeSwitch 3 "NotAvailable" 2 "Error" 1 "On" 0 "Off" ;
VAL_ 2566844672 EngIdleDecrementSwitch 3 "NotAvailable" 2 "Error" 1 "On" 0 "Off" ;
VAL_ 2566844672 EngIdleIncrementSwitch 3 "NotAvailable" 2 "Error" 1 "On" 0 "Off" ;
VAL_ 2566844672 CruiseCtrlStates 7 "NotAvailable" 6 "AccelOverride" 5 "Set" 4 "Resume" 3 "Decelerate" 2 "Accelerate" 1 "Hold" 0 "Off_Disabled" ;
VAL_ 2566844672 CruiseCtrlAccelerateSwitch_CCVSE 3 "NotAvailable" 2 "Error" 1 "CrsCtrlActivatorInPosAccelerate" 0 "CrsCtrlActvtrNotInPosAccelerate" ;
VAL_ 2566844672 CruiseCtrlResumeSwitch_CCVS_ECM 3 "NotAvailable" 2 "Error" 1 "CruiseCtrlActivatorInPosResume" 0 "CrseCtrlActivatorNotInPosResume" ;
VAL_ 2566844672 CruiseCtrlCoastSwitch_CCVS_ECM 3 "NotAvailable" 2 "Error" 1 "CruiseCtrlActivatorInPosCoast" 0 "CriseCtrlActivatorNotInPosCoast" ;
VAL_ 2566844672 CruiseCtrlSetSwitch 3 "NotAvailable" 2 "Error" 1 "CruiseCtrlActivatorInPosSet" 0 "CruiseCtrlActivatorNotInPosSet" ;
VAL_ 2566844672 ClutchSwitch_CCVS_ECM 3 "NotAvailable" 2 "Error" 1 "ClutchPedalDepressed" 0 "ClutchPedalReleased" ;
VAL_ 2566844672 BrakeSwitch_CCVS_ECM 3 "NotAvailable" 2 "Error" 1 "BrakePedalDepressed" 0 "BrakePedalReleased" ;
VAL_ 2566844672 CruiseCtrlEnableSwitch 3 "NotAvailable" 2 "Error" 1 "CruiseCtrlEnabled" 0 "CruiseCtrlDisabled" ;
VAL_ 2566844672 CruiseCtrlActive 3 "NotAvailable" 2 "Error" 1 "CruiseCtrlSwitchedOn" 0 "CruiseCtrlSwitchedOff" ;
VAL_ 2566844672 WheelBasedVehicleSpeed_CCVS_ECM 255 "Not available" 254 "Error" ;
VAL_ 2566844672 ParkingBrakeSwitch_CCVS_ECM 3 "NotAvailable" 2 "Error" 1 "ParkingBrakeSet" 0 "ParkingBrakeNotSet" ;
VAL_ 2566801923 TransReadyForBrakeRelease 3 "NotAvailable" 2 "Error" 1 "TransReadyForBrakeRelease" 0 "TransNotReadyForBrakeRelease" ;
VAL_ 2566801923 RollingMode 3 "Takenoaction" 2 "Reserve" 1 "Enable" 0 "Disable" ;
VAL_ 2566801923 RockingMode 3 "Takenoaction" 2 "Reserve" 1 "Enable" 0 "Disable" ;
VAL_ 2566801923 OffRoadMode 3 "Takenoaction" 2 "Reserve" 1 "Enable" 0 "Disable" ;
VAL_ 2566801923 PowerMode 3 "Takenoaction" 2 "Reserve" 1 "Enable" 0 "Disable" ;
VAL_ 2566801923 TransEngCrankEnable 3 "NotAvailable" 2 "Error" 1 "CrnkngEnbldEngCrnkngIsAllwdByTr" 0 "CrnkngDsbldEngCrnkngIsPrhbtdByT" ;
VAL_ 2565406224 ControlByte 3 "CannotRespond" 2 "AccessDenied" 1 "NACK" 0 "ACK" ;
VAL_ 2566870288 RequestCruiseContrlSwtchOff 3 "NotAvailable" 2 "Reserved" 1 "IntrdrIsReqstCCSwtchOff" 0 "IntrdrIsNotReqstCCSwtchOff" ;
VAL_ 2566870288 RetarOnDriverDemand 3 "NotAvailable" 2 "Reserved" 1 "RetarderOnDriverDemand" 0 "NoRetarderOnDriverDemand" ;
VAL_ 2566870288 RequestIntPilotLamp 3 "NotAvailable" 2 "Reserved" 1 "IntIsReqstngPilotLamp" 0 "IntIsNotReqstngPilotLamp" ;
VAL_ 2566870288 IntPilotLampState 3 "NotAvailable" 2 "IntarderPilotLampFlashes" 1 "IntarderPilotLampOn" 0 "IntarderPilotLampOff" ;
VAL_ 2365484270 VehicleOverspeed 3 "NotAvailable" 2 "Error" 1 "Overspeed" 0 "NoOverspeed" ;
VAL_ 2365484270 VehicleMotion 3 "NotAvailable" 2 "Error" 1 "VehicleMotionDetected" 0 "VehicleMotionNotDetected" ;
VAL_ 2365484270 DirectionIndicator 3 "NotAvailable" 2 "Error" 1 "Reverse" 0 "Forward" ;
VAL_ 2365484270 TachographPerformance 3 "NotAvailable" 2 "Error" 1 "PerformanceAnalysis" 0 "NormalPerformance" ;
VAL_ 2365484270 HandlingInformation 3 "NotAvailable" 2 "Error" 1 "HandlingInformation" 0 "NoHandlingInformation" ;
VAL_ 2365484270 SystemEvent 3 "NotAvailable" 2 "Error" 1 "TachographEvent" 0 "NoTachographEvent" ;
VAL_ 2365484270 DriverCardDriver2 3 "NotAvailable" 2 "Error" 1 "DriverCardPresent" 0 "DriverCardNotPresent" ;
VAL_ 2365484270 Driver2TimeRelatedStates 15 "NotAvailable" 14 "Error" 13 "Other" 7 "1100Reserved" 6 "Limit616HReached" 5 "Limit515MinBefore16H" 4 "Limit49HReached" 3 "Limit315MinBefore9H" 2 "Limit24HReached" 1 "Limit115MinBefore4H" 0 "Normal_NoLimitsReached" ;
VAL_ 2365484270 DriverCardDriver1 3 "NotAvailable" 2 "Error" 1 "DriverCardPresent" 0 "DriverCardNotPresent" ;
VAL_ 2365484270 Driver1TimeRelatedStates 15 "NotAvailable" 14 "Error" 13 "Other" 7 "1100Reserved" 6 "Limit616HReached" 5 "Limit515MinBefore16H" 4 "Limit49HReached" 3 "Limit315MinBefore9H" 2 "Limit24HReached" 1 "Limit115MinBefore4H" 0 "Normal_NoLimitsReached" ;
VAL_ 2365484270 Driver2WorkingState 7 "NotAvailable" 6 "Error" 4 "101Reserved" 3 "DriveBehindWheel" 2 "WrkLdngUnldingWorkingInAnOffice" 1 "DriverAvailableShortBreak" 0 "RestSleeping" ;
VAL_ 2365484270 Driver1WorkingState 7 "NotAvailable" 6 "Error" 4 "101Reserved" 3 "DriveBehindWheel" 2 "WrkLdngUnldingWorkingInAnOffice" 1 "DriverAvailableShortBreak" 0 "RestSleeping" ;
VAL_ 2631855639 TripGroup2Proprietary 2 "Reserved" 3 "NotApplicable" 1 "Reset" 0 "TakeNoAction" ;
VAL_ 2631855639 TripGroup1 2 "Reserved" 3 "NotApplicable" 1 "Reset" 0 "TakeNoAction" ;
VAL_ 2566838551 DataandLocationServicesSelection 2 "Data Services On" 1 "Data Services Off" 0 "No Command" ;
VAL_ 2566838551 User_Connectivity_Selection 2 "Connectivity On" 1 "Connectivity Off" 0 "No Command" ;
VAL_ 2566838551 Trip_Reset_2 3 "N/A" 2 "Error" 1 "Trip2 resetted by driver" 0 "No reset" ;
VAL_ 2566838551 Trip_Reset_1 3 "N/A" 2 "Error" 1 "Trip1 resetted by driver" 0 "No reset" ;
VAL_ 2566838551 LowCoolantLevel 3 "NA" 2 "Reserved" 1 "LOW Coolant Level" 0 "Coolant Level OK" ;
VAL_ 2566838551 AirFilterRestriction 3 "NA" 2 "Reserved" 1 "Restriction on filter " 0 "No restricition on filter" ;
VAL_ 2566838551 EcoRollSelection 3 "not available" 2 "error" 1 "active" 0 "deactive" ;
VAL_ 2566838551 RaiseChassisHeight_AUXIO_R_IC 1 "Active" 0 "Deactive" ;
VAL_ 2566838551 LowerChassisHeight_AUXIO_R_IC 1 "Active" 0 "Deactive" ;
VAL_ 2566838551 RideHeightRequest_AUXIO_R_IC 1 "Active" 0 "Deactive" ;
VAL_ 2566838551 DrvTips_Enable 3 "Not available" 2 "Error" 1 "Enabled" 0 "Disabled" ;
VAL_ 2566838551 DrvEva_Reset 3 "Error" 2 "Reserved" 1 "Reset" 0 "Do not reset" ;
VAL_ 2566838551 ACCUsageDemand_AUXIO_R_IC 3 "dontCare" 2 "reserved" 1 "drvrDmndFrUsngACCDstncKpingCtrl" 0 "drvrDmndFrNtUsngACCDstncKpngCtr" ;
VAL_ 2566838551 ADASWarningMuteReq 1 "Mute active" 0 "Mute not active" ;
VAL_ 2566838551 AuxI_O03_RetarderLeverPosition 3 "Not Available" 2 "Error" 1 "IntarderLeverpos on" 0 "IntarderLeverpos off " ;
VAL_ 2566838551 TrailerABSFullyOperational 3 "Not available" 2 "Error" 1 "Trailer ABS fully operational" 0 "TrailerABSnot fully operational" ;
VAL_ 2566838551 TrailerABSDetected 3 "Not available" 2 "Error" 1 "Trailer ABS detected" 0 "Trailer ABS not detected" ;
VAL_ 2566838551 TrailerConnected 3 "Not available" 2 "Error" 1 "Trailer connected" 0 "Trailer not connected" ;
VAL_ 2566838551 LanguageInfo 33 "Thai" 32 "Romany" 31 "Serbian" 30 "Slovak" 29 "Arabic" 28 "Taiwanese" 27 "Mandarin_Chinese" 26 "Korean" 25 "AU_English" 24 "Japanese" 23 "Braz_Portuguese" 22 "EU_Portuguese" 21 "Finish" 20 "Norwegian" 19 "Danish" 18 "Swedish" 17 "Hungarian" 16 "Greek" 15 "Czech" 14 "Polish" 13 "Flemish" 12 "Dutch" 11 "Russian" 10 "Turkish" 9 "Mex_Spanish" 8 "EU_Spanish" 7 "Cana_French" 6 "EU_French" 5 "Italian" 4 "German" 3 "NA_English" 2 "UK_English" 1 "Unknown" 0 "Invalid" ;
VAL_ 2566838551 RainSensingActivation 3 "Not available" 2 "Error" 1 "Active" 0 "Deactive" ;
VAL_ 2566838551 Autolock_Activation 3 "Not available" 2 "Error" 1 "Active" 0 "Deactive" ;
VAL_ 2566838551 AuxI_O02_BlendingSwitchPos 3 "NotAvailable" 2 "Error" 1 "RetarderBlendingEnabled" 0 "RetarderBlendingDiasabled" ;
VAL_ 2566838551 OTAUpdateRequest1 3 "Not available" 2 "Error" 1 "Request update" 0 "Default - No  request" ;
VAL_ 2566838551 PCCLevelSelection 15 "Not available" 14 "Not available" 13 "Not available" 12 "Not available" 11 "Not available" 10 "Not available" 9 "Not available" 8 "Not available" 7 "Not available" 6 "Not available" 5 "Not available" 4 "Not available" 3 "Mode 3" 2 "Mode 2" 1 "Mode 1" 0 "Normal CC" ;
VAL_ 2566838551 CabinTiltSwitch 3 "NotAvailable" 2 "Error" 1 "Cabin Tilted" 0 "Cabin not tilted" ;
VAL_ 2566838551 LDWBuzzerStatus_AUXIO_R_IC 3 "DonTCare" 2 "Reserved" 1 "EnableLaneDepartureWarning" 0 "DisableLaneDepartureWarning" ;
VAL_ 2631729175 AntthftEncryptonIndicatorStates 3 "NtAvlblThsSttIsUsdTIndctThtARnd" 2 "NotDefined" 1 "EncryptdCdPrsntThsSttIsUsdTIndc" 0 "EncryptnSdRqThsSttRprsntsARqstT" ;
VAL_ 2631729175 AntitheftDesiredExitModeStates 3 "NtAvlblThsSttIsIndctsThtOptnIsN" 2 "NotDefined" 1 "LckWhnKyffThsSttIsUsdTIndctThtC" 0 "LckUpnOprtrRqThsSttIsUsdTIndctT" ;
VAL_ 2631729175 AntitheftCmdStates 6 "111NotDefined" 5 "Login" 4 "ChckSttsThsSttRprsntsARqTChckTS" 3 "LockorUnlock" 2 "ChngPwdThsSttRprsntsARqTCmpnntT" 1 "DeletePwd" 0 "AddPwdThsSttRprsntsARqTCmpnntTA" ;
VAL_ 2566806504 RightWheelLaneDepDist 255 "Not available" ;
VAL_ 2566806504 LeftWheelLaneDepDist 255 "Not available" ;
VAL_ 2566806504 Line_type_left_side 7 "no available/not installed" 6 "error" 5 "Bott'sDots detected" 4 "Double line detected" 3 "Dashed line detected" 2 "RoadEdge detected" 1 "Solid line detected" 0 "No line detected" ;
VAL_ 2566806504 Line_type_right_side 7 "no available/not installed" 6 "error" 5 "Bott'sDots detected" 4 "Double line detected" 3 "Dashed line detected" 2 "RoadEdge detected" 1 "Solid line detected" 0 "No line detected" ;
VAL_ 2566806504 CameraStatus 14 "NotAvailable" 13 "Error" 4 "Misaligned" 3 "Blocked" 2 "PartiallyBlocked" 1 "Warningup/Initializing" 0 "FullyOperational" ;
VAL_ 2566806504 LaneDepartureWarningSystemState 15 "NotAvailable" 14 "Error" 5 "SystemIsWarning" 4 "DriverOverridesSystem" 3 "SystemIsReady" 2 "SystemIsDeactivatedByDriver" 1 "SystemIsTempNotAvailable" 0 "SystemIsNotReady" ;
VAL_ 2566806504 LnDprtureIndicationEnableStatus 3 "NotUsed" 2 "Reserved" 1 "LaneDepartureIndicationEnabled" 0 "LaneDepartureIndicationDisabled" ;
VAL_ 2566806504 LaneTrackingStatusLeftSide 3 "DontCare_TakeNoAction" 2 "Reserved" 1 "TrackingLeftSide" 0 "NotTrackingLeftSide" ;
VAL_ 2566806504 LaneTrackingStatusRightSide 3 "DontCare_TakeNoAction" 2 "Reserved" 1 "TrackingRightSide" 0 "NotTrackingRightSide" ;
VAL_ 2431649768 RightWheelLaneDepDist 255 "Not available" ;
VAL_ 2431649768 LeftWheelLaneDepDist 255 "Not available" ;
VAL_ 2431649768 LaneDepartureRightSide 3 "Not available" 2 "Error indicator" 1 "Imminent" 0 "Not imminent" ;
VAL_ 2431649768 LaneDepartureLeftSide 3 "Not available" 2 "Error indicator" 1 "Imminent" 0 "Not imminent" ;
VAL_ 2431649768 AcousticalWarningLeftSide 3 "NotAvailable" 2 "Error" 1 "Active" 0 "Inactive" ;
VAL_ 2431649768 AcousticalWarningRightSide 3 "NotAvailable" 2 "Error" 1 "Active" 0 "Inactive" ;
VAL_ 2431649768 OpticalWarningLeftSide 3 "NotAvailable" 2 "Error" 1 "Active" 0 "Inactive" ;
VAL_ 2431649768 OpticalWarningRightSide 3 "NotAvailable" 2 "Error" 1 "Active" 0 "Inactive" ;
VAL_ 2431649768 LaneDepartureImminentLeftSide 3 "NotUsed" 2 "Reserved" 1 "Imminent" 0 "NotImminent" ;
VAL_ 2431649768 LaneDepartureImminentRightSide 3 "NotUsed" 2 "Reserved" 1 "Imminent" 0 "NotImminent" ;
VAL_ 2348810282 MessageCounter 14 "Reserved" 13 "Reserved" 12 "Reserved" 11 "Reserved" 10 "Reserved" 9 "Reserved" 8 "Reserved" 15 "Not Available" ;
VAL_ 2348810282 ControlPurpose 31 "TemporaryPowerTrainControl" 4 "EngineProtection" 3 "RoadSpeedGovernor" 2 "PTOGovernor" 1 "CruiseControl" 0 "AcceleratorPedal" ;
VAL_ 2348810282 TransmissionRate 7 "UseStandardRate" 6 "25ms" 5 "50ms" 4 "100ms" 3 "250ms" 2 "500ms" 1 "750ms" 0 "1000ms" ;
VAL_ 2348810282 OverrideCtrlModePriority 3 "LowPriority" 2 "MdmPrrtyUsdFrPwrtrnCtrlOprtnsWh" 1 "HighPriority" 0 "HghstPrrtyUsdFrSttnsThtRqrImmdt" ;
VAL_ 2348810282 EngRqedSpeedCtrlConditions 2 "ThsCtrlCndtnHsBnOptmzdTMnmzRpmO" 3 "StbltyOptmzdFrDrvlnEnggdAnd_OrI" 1 "StbltyOptmzdFrDrvlnDsnggdAndNnl" 0 "ThsSpdGvrnrGnSlctnIsAdjstdTPrvd" ;
VAL_ 2348810282 EngOverrideCtrlMode 3 "Spd_TrqLmtCtrlLmtSpdAnd_OrTrqBs" 2 "TrqCtrlCntrlTrqTInclddDsrdTrqVl" 1 "SpdCtrlGvrnSpdTInclddDsrdSpdVle" 0 "OvrrdDsbldDsblAnyExstngCtrlCmdd" ;
VAL_ 2348810282 MessageChecksum 15 "Not Available" ;
VAL_ 2348810282 EngineRequestedTorqueHiRes 15 "Not Available" 14 "Not Available" 13 "Not Available" 12 "Not Available" 11 "Not Available" 10 "Not Available" 9 "Not Available" 8 "Not Available" ;
VAL_ 2364550954 TimeToCollision 255 "N/A" 238 "Error indicator" ;
VAL_ 2364550954 AdvancedEmergencyBrkSysState 15 "NotAvailable" 14 "ErrorIndication" 7 "EmergencyBrakingActive" 6 "CollisionWarningWithBraking" 5 "CollisionWarningActive" 4 "DriverOverridesSystem" 3 "SystemIsReady" 2 "SystemDeactivatedbyDriver" 1 "SystemTemporaryNotAvailable" 0 "SystemIsnotReady" ;
VAL_ 2349075242 XBRCtrlMode 3 "NotDefined" 2 "AccelerationControlWithMaxMode" 1 "AccelerationControlWithAddMode" 0 "OverrideDisabled" ;
VAL_ 2349075242 XBRPriority 3 "LwPrrtyUsdInOvrrdDsbldXBRCtrlMd" 2 "MdmPrrtyUsdFrACCSystmsThsMdDsNt" 1 "HighPriorityNotDefined" 0 "HghstPrrtyUsdFrEmrgncySttnsEgFr" ;
VAL_ 2349075242 XBREBIMode 3 "NotDefined" 2 "EndranceBrakeIntegrationAllowed" 1 "OnlyEnduranceBrakesAllowed" 0 "NEndrnceBrakeIntegrationAllowed" ;
VAL_ 2349075242 XBRUrgency 4 "LwRtrdrDynmcsShllBFllyCmpnstdBy" 0 "SttnNtCrtclLwRtrdrDynmcsArTlrtd" ;
VAL_ 2365443122 HazardLampStatus 3 "not available " 2 "Error" 1 "On" 0 "Off" ;
VAL_ 2365443122 ApproachLight 17 "Approach Light Not Available" 16 "Approach Light Error" 1 "Approach Light On" 0 "Approach Light Off" ;
VAL_ 2365443122 TrailerTurnLight 3 "NotAvailable" 2 "Error" 1 "Activated" 0 "Deactivated" ;
VAL_ 2365443122 OutPointer 254 "Error indicator" 255 "N/A" ;
VAL_ 2365443122 OutLCD 254 "Error indicator" 255 "N/A" ;
VAL_ 2365443122 OutDial 254 "Error indicator" 255 "N/A" ;
VAL_ 2365443122 WiperActive 3 "NotAvailable" 2 "Error" 1 "WiperActive" 0 "WiperIsNotActive" ;
VAL_ 2365443122 HighLowBeamSwitch 3 "NotAvailable" 2 "Error" 1 "HighBeamSelected" 0 "LowBeamSelected" ;
VAL_ 2365443122 HazardLightSwitch 3 "NotAvailable" 2 "Error" 1 "HazardLampsToBeFlashing" 0 "HazardLampsToBeOff" ;
VAL_ 2365443122 TurnSignalSwitch_OEL_BCM 2 "RightTurnToBeFlashing" 15 "NotAvailable" 14 "Error" 3 "1101Reserved" 1 "LeftTurnToBeFlashing" 0 "NoTurnBeingSignaled" ;
VAL_ 2365443122 MainLightSwitch 9 "1101Reserved" 8 "DlydOffPsByWhchThOprtrSlctsThtA" 4 "0111Reserved" 2 "HdlghtOnPsByWhchThOprtrSlctsTht" 15 "NotAvailable" 14 "Error" 3 "HdlghtAndPrkOnPsByWhchThOprtrSl" 1 "PrkOnPsByWhchThOprtrSlctsThtThP" 0 "OffPsByWhchThOprtrSlctsThtNnOfT" ;
VAL_ 2365443122 WorkLightSwitch 5 "1101Reserved" 4 "WrkLghtCmbntn4OnPsByWhchThOprtr" 2 "WrkLghtCmbntn2OnPsByWhchThOprtr" 15 "NotAvailable" 14 "Error" 3 "WrkLghtCmbntn3OnPsByWhchThOprtr" 1 "WrkLghtCmbntn1OnPsByWhchThOprtr" 0 "OffPsByWhchThOprtrSlctsThtNnOfT" ;
VAL_ 2561271841 LDWBuzzerStatus_FLIC_BCM 3 "Not available" 2 "Error" 1 "EnableLaneDepartureWarning" 0 "DisableLaneDepartureWarning" ;
VAL_ 2561271841 LaneDepartureWarningEnableCmd 3 "DonTCare" 2 "Reserved" 1 "EnableLaneDepartureWarning" 0 "DisableLaneDepartureWarning" ;
VAL_ 2565867041 LowLiner 3 "Not Available" 2 "Error" 1 "Active" 0 "Deactive" ;
VAL_ 2565867041 RearAxleGroupEngagementStatus 3 "notAvailable" 2 "error" 1 "rearAxleGroupEngaged" 0 "rearAxleGroupDisengaged" ;
VAL_ 2565867041 FrontAxleGroupEngagementStatus 3 "notAvailable" 2 "error" 1 "frontAxleGroupEngaged" 0 "frontAxleGroupDisengaged" ;
VAL_ 2565867041 DiffLockStateCentralRear 3 "NotAvailable" 2 "Error" 1 "DiffLockEngaged" 0 "DiffLockDisengaged" ;
VAL_ 2565867041 DiffLockStateCentralFront 3 "NotAvailable" 2 "Error" 1 "DiffLockEngaged" 0 "DiffLockDisengaged" ;
VAL_ 2565867041 Interlock 3 "NotAvailable" 2 "Error" 1 "InterlockEngaged" 0 "InterlockDisengaged" ;
VAL_ 2565867041 DiffLockStateRearAxle2 3 "NotAvailable" 2 "Error" 1 "DiffLockEngaged" 0 "DiffLockDisengaged" ;
VAL_ 2565867041 DiffLockStateRearAxle1 3 "NotAvailable" 2 "Error" 1 "DiffLockEngaged" 0 "DiffLockDisengaged" ;
VAL_ 2565867041 DiffLock1 3 "NotAvailable" 2 "Error" 1 "DiffLockEngaged" 0 "DiffLockDisengaged" ;
VAL_ 2565867041 DiffLock2 3 "NotAvailable" 2 "Error" 1 "DiffLockEngaged" 0 "DiffLockDisengaged" ;
VAL_ 2564816929 AuxiliaryHeaterModeStatus 15 "Error" 1 "FOPH Mode Active" 0 "FOPH Mode Not Active" ;
VAL_ 2564816929 ParticulateTrapRegenForceSw 3 "NotAvailable" 2 "Error" 1 "Active" 0 "NotActive" ;
VAL_ 2564816929 ParticulateTrapRegenInSwitch 3 "NotAvailable" 2 "Error" 1 "Active" 0 "NotActive" ;
